VERSION "$Format:%h$"

NS_ :

BS_:

BU_: APB APP APS BCCEN BDY DAS DBG EAS EPAS EPAS2 EPAS3S EPB EPBM ESP GTW GTWU IBST IC MCU OCS PARK PARK3 RADAR RCM RT3000 SCCM SDM SEC TAS TAS2 TAS2DBG TOOL TPMS VCSEATD VCSEATP

BO_ 1009 RCM2_alertMatrix: 8 RCM
 SG_ RCM2_matrixIndex M : 0|4@1+ (1,0) [0|0] "" GTW
 SG_ RCM2_a567_seaTrkPosLeftConfig m5 : 42|1@1+ (1,0) [0|0] "" GTW
 SG_ RCM2_a568_occPROSSht2Gnd m5 : 43|1@1+ (1,0) [0|0] "" GTW
 SG_ RCM2_a569_occPROSSht2Bat m5 : 44|1@1+ (1,0) [0|0] "" GTW
 SG_ RCM2_a570_occPROSOpen m5 : 45|1@1+ (1,0) [0|0] "" GTW
 SG_ RCM2_a571_occPROSUndef m5 : 46|1@1+ (1,0) [0|0] "" GTW
 SG_ RCM2_a572_occPROSCrssCoup m5 : 47|1@1+ (1,0) [0|0] "" GTW
 SG_ RCM2_a573_occPROSConfig m5 : 48|1@1+ (1,0) [0|0] "" GTW
 SG_ RCM2_a587_sbrRearNetSht2Gnd m5 : 49|1@1+ (1,0) [0|0] "" GTW
 SG_ RCM2_a588_sbrRearNetSht2Bat m5 : 50|1@1+ (1,0) [0|0] "" GTW
 SG_ RCM2_a589_sbrRearNetOpen m5 : 51|1@1+ (1,0) [0|0] "" GTW
 SG_ RCM2_a590_sbrRearNetUndefined m5 : 52|1@1+ (1,0) [0|0] "" GTW
 SG_ RCM2_a591_sbrRearNetCrssCoup m5 : 53|1@1+ (1,0) [0|0] "" GTW
 SG_ RCM2_a592_sbrRearNetConfig m5 : 54|1@1+ (1,0) [0|0] "" GTW
 SG_ RCM2_a593_driveOrientaSht2Gnd m5 : 55|1@1+ (1,0) [0|0] "" GTW
 SG_ RCM2_a594_driveOrientaSht2Bat m5 : 56|1@1+ (1,0) [0|0] "" GTW
 SG_ RCM2_a595_driveOrientaOpen m5 : 57|1@1+ (1,0) [0|0] "" GTW
 SG_ RCM2_a596_driveOrientaUndefined m5 : 58|1@1+ (1,0) [0|0] "" GTW
 SG_ RCM2_a597_driveOrientaCrssCoup m5 : 59|1@1+ (1,0) [0|0] "" GTW
 SG_ RCM2_a598_driveOrientaConfig m5 : 60|1@1+ (1,0) [0|0] "" GTW
 SG_ RCM2_a600_comCANinternalTimeout m5 : 61|1@1+ (1,0) [0|0] "" GTW
 SG_ RCM2_a601_comChassisCANInit m5 : 62|1@1+ (1,0) [0|0] "" GTW
 SG_ RCM2_a602_comChassisCANBusOff m5 : 63|1@1+ (1,0) [0|0] "" GTW
 SG_ RCM2_a603_comPARTYCANInit m6 : 4|1@1+ (1,0) [0|0] "" GTW
 SG_ RCM2_a604_comPARTYCANBusOff m6 : 5|1@1+ (1,0) [0|0] "" GTW
 SG_ RCM2_a605_comStwAngStatMIA m6 : 6|1@1+ (1,0) [0|0] "" GTW
 SG_ RCM2_a606_comStwAngStatChkSm m6 : 7|1@1+ (1,0) [0|0] "" GTW
 SG_ RCM2_a607_comStwAngStatCntr m6 : 8|1@1+ (1,0) [0|0] "" GTW
 SG_ RCM2_a608_comDItorque1MIA m6 : 9|1@1+ (1,0) [0|0] "" GTW
 SG_ RCM2_a609_comDItorque1ChkSm m6 : 10|1@1+ (1,0) [0|0] "" GTW
 SG_ RCM2_a610_comDItorque1Cntr m6 : 11|1@1+ (1,0) [0|0] "" GTW
 SG_ RCM2_a611_comDItorque2MIA m6 : 12|1@1+ (1,0) [0|0] "" GTW
 SG_ RCM2_a612_comDItorque2ChkSm m6 : 13|1@1+ (1,0) [0|0] "" GTW
 SG_ RCM2_a613_comDItorque2Cntr m6 : 14|1@1+ (1,0) [0|0] "" GTW
 SG_ RCM2_a614_comESP135MIA m6 : 15|1@1+ (1,0) [0|0] "" GTW
 SG_ RCM2_a615_comESP135ChkSm m6 : 16|1@1+ (1,0) [0|0] "" GTW
 SG_ RCM2_a616_comESP135Cntr m6 : 17|1@1+ (1,0) [0|0] "" GTW
 SG_ RCM2_a617_comESP145MIA m6 : 18|1@1+ (1,0) [0|0] "" GTW
 SG_ RCM2_a618_comESP145ChkSm m6 : 19|1@1+ (1,0) [0|0] "" GTW
 SG_ RCM2_a619_comESP145Cntr m6 : 20|1@1+ (1,0) [0|0] "" GTW
 SG_ RCM2_a620_comInvalidVehicleSpeed m6 : 21|1@1+ (1,0) [0|0] "" GTW
 SG_ RCM2_a621_comESPBMIA m6 : 22|1@1+ (1,0) [0|0] "" GTW
 SG_ RCM2_a622_comESPBChkSm m6 : 23|1@1+ (1,0) [0|0] "" GTW
 SG_ RCM2_a623_comESPBCntr m6 : 24|1@1+ (1,0) [0|0] "" GTW
 SG_ RCM2_a624_comESPCMIA m6 : 25|1@1+ (1,0) [0|0] "" GTW
 SG_ RCM2_a625_comESPCChkSm m6 : 26|1@1+ (1,0) [0|0] "" GTW
 SG_ RCM2_a626_comESPCCntr m6 : 27|1@1+ (1,0) [0|0] "" GTW
 SG_ RCM2_a627_comEPBStatusMIA m6 : 28|1@1+ (1,0) [0|0] "" GTW
 SG_ RCM2_a628_comEPBStatusChkSm m6 : 29|1@1+ (1,0) [0|0] "" GTW
 SG_ RCM2_a629_comEPBStatusCntr m6 : 30|1@1+ (1,0) [0|0] "" GTW
 SG_ RCM2_a630_comGTWACSMIA m6 : 31|1@1+ (1,0) [0|0] "" GTW
 SG_ RCM2_a631_comGTWACSChkSm m6 : 32|1@1+ (1,0) [0|0] "" GTW
 SG_ RCM2_a632_comGTWACSCntr m6 : 33|1@1+ (1,0) [0|0] "" GTW
 SG_ RCM2_a633_comOCS1PMIA m6 : 34|1@1+ (1,0) [0|0] "" GTW
 SG_ RCM2_a634_comOCS1PChkSm m6 : 35|1@1+ (1,0) [0|0] "" GTW
 SG_ RCM2_a635_comOCS1PCntr m6 : 36|1@1+ (1,0) [0|0] "" GTW
 SG_ RCM2_a636_ocsFaulted m6 : 37|1@1+ (1,0) [0|0] "" GTW
 SG_ RCM2_a637_ocsUnknown m6 : 38|1@1+ (1,0) [0|0] "" GTW
 SG_ RCM2_a638_comGTWodoMIA m6 : 39|1@1+ (1,0) [0|0] "" GTW
 SG_ RCM2_a639_comGTWCarStateMIA m6 : 40|1@1+ (1,0) [0|0] "" GTW
 SG_ RCM2_a640_comTPMSStatusCMIA m6 : 41|1@1+ (1,0) [0|0] "" GTW
 SG_ RCM2_a641_comGTWCarConfigMIA m6 : 42|1@1+ (1,0) [0|0] "" GTW
 SG_ RCM2_a642_comVINmessageMIA m6 : 43|1@1+ (1,0) [0|0] "" GTW
 SG_ RCM2_a643_comDASSafetyFrntMIA m6 : 44|1@1+ (1,0) [0|0] "" GTW
 SG_ RCM2_a644_comDASSafetyFrntChkSm m6 : 45|1@1+ (1,0) [0|0] "" GTW
 SG_ RCM2_a645_comDASSafetyFrntCntr m6 : 46|1@1+ (1,0) [0|0] "" GTW
 SG_ RCM2_a646_comDIstateMIA m6 : 47|1@1+ (1,0) [0|0] "" GTW
 SG_ RCM2_a647_comDIstateChkSm m6 : 48|1@1+ (1,0) [0|0] "" GTW
 SG_ RCM2_a648_comDIstateCntr m6 : 49|1@1+ (1,0) [0|0] "" GTW
 SG_ RCM2_a649_comDIstate2MIA m6 : 50|1@1+ (1,0) [0|0] "" GTW
 SG_ RCM2_a650_comDIstate2ChkSm m6 : 51|1@1+ (1,0) [0|0] "" GTW
 SG_ RCM2_a651_comDIstate2Cntr m6 : 52|1@1+ (1,0) [0|0] "" GTW
 SG_ RCM2_a652_ambientTempFaulted m6 : 53|1@1+ (1,0) [0|0] "" GTW
 SG_ RCM2_a653_comGTWESP1MIA m6 : 54|1@1+ (1,0) [0|0] "" GTW
 SG_ RCM2_a654_comGTWESP1ChkSm m6 : 55|1@1+ (1,0) [0|0] "" GTW
 SG_ RCM2_a655_comGTWESP1Cntr m6 : 56|1@1+ (1,0) [0|0] "" GTW
 SG_ RCM2_a750_linInternalTimeout m6 : 57|1@1+ (1,0) [0|0] "" GTW
 SG_ RCM2_a800_cfgMissingCalibration m6 : 58|1@1+ (1,0) [0|0] "" GTW
 SG_ RCM2_a801_cfgImplausConfig m6 : 59|1@1+ (1,0) [0|0] "" GTW
 SG_ RCM2_a802_cfgInvalidConfig m6 : 60|1@1+ (1,0) [0|0] "" GTW
 SG_ RCM2_a803_cfgNotConfigured m6 : 61|1@1+ (1,0) [0|0] "" GTW
 SG_ RCM2_a804_cfgNotProgrammed m6 : 62|1@1+ (1,0) [0|0] "" GTW
 SG_ RCM2_a805_cfgPedProNotProgrammed m6 : 63|1@1+ (1,0) [0|0] "" GTW
 SG_ RCM2_a806_cfgCrashCalPNmissing m7 : 4|1@1+ (1,0) [0|0] "" GTW
 SG_ RCM2_a807_cfgExternalCRCError m7 : 5|1@1+ (1,0) [0|0] "" GTW
 SG_ RCM2_a808_cfgInvalParamLayoutID m7 : 6|1@1+ (1,0) [0|0] "" GTW
 SG_ RCM2_a809_cfgInvalParamTransID m7 : 7|1@1+ (1,0) [0|0] "" GTW
 SG_ RCM2_a810_cfgAlgoVerifySnsrID m7 : 8|1@1+ (1,0) [0|0] "" GTW
 SG_ RCM2_a811_cfgConfigDataInconsist m7 : 9|1@1+ (1,0) [0|0] "" GTW
 SG_ RCM2_a812_swVersionWrong m7 : 10|1@1+ (1,0) [0|0] "" GTW
 SG_ RCM2_a813_vinNotProgrammed m7 : 11|1@1+ (1,0) [0|0] "" GTW
 SG_ RCM2_a814_vinMismatch m7 : 12|1@1+ (1,0) [0|0] "" GTW
 SG_ RCM2_a815_driveLeaningNotDone m7 : 13|1@1+ (1,0) [0|0] "" GTW
 SG_ RCM2_a816_driveLeaningMismatch m7 : 14|1@1+ (1,0) [0|0] "" GTW
 SG_ RCM2_a817_bootActionsFailed m7 : 15|1@1+ (1,0) [0|0] "" GTW
 SG_ RCM2_a850_internalFault_001 m7 : 16|1@1+ (1,0) [0|0] "" GTW
 SG_ RCM2_a851_internalFault_002 m7 : 17|1@1+ (1,0) [0|0] "" GTW
 SG_ RCM2_a852_internalFault_003 m7 : 18|1@1+ (1,0) [0|0] "" GTW
 SG_ RCM2_a853_internalFault_004 m7 : 19|1@1+ (1,0) [0|0] "" GTW
 SG_ RCM2_a854_internalFault_005 m7 : 20|1@1+ (1,0) [0|0] "" GTW
 SG_ RCM2_a855_internalFault_006 m7 : 21|1@1+ (1,0) [0|0] "" GTW
 SG_ RCM2_a856_internalFault_007 m7 : 22|1@1+ (1,0) [0|0] "" GTW
 SG_ RCM2_a857_internalFault_008 m7 : 23|1@1+ (1,0) [0|0] "" GTW
 SG_ RCM2_a858_internalFault_009 m7 : 24|1@1+ (1,0) [0|0] "" GTW
 SG_ RCM2_a859_internalFault_010 m7 : 25|1@1+ (1,0) [0|0] "" GTW
 SG_ RCM2_a860_internalFault_011 m7 : 26|1@1+ (1,0) [0|0] "" GTW
 SG_ RCM2_a861_internalFault_012 m7 : 27|1@1+ (1,0) [0|0] "" GTW
 SG_ RCM2_a862_internalFault_013 m7 : 28|1@1+ (1,0) [0|0] "" GTW
 SG_ RCM2_a863_internalFault_014 m7 : 29|1@1+ (1,0) [0|0] "" GTW
 SG_ RCM2_a864_internalFault_015 m7 : 30|1@1+ (1,0) [0|0] "" GTW
 SG_ RCM2_a865_internalFault_016 m7 : 31|1@1+ (1,0) [0|0] "" GTW
 SG_ RCM2_a866_internalFault_017 m7 : 32|1@1+ (1,0) [0|0] "" GTW
 SG_ RCM2_a867_internalFault_018 m7 : 33|1@1+ (1,0) [0|0] "" GTW
 SG_ RCM2_a868_internalFault_019 m7 : 34|1@1+ (1,0) [0|0] "" GTW
 SG_ RCM2_a869_internalFault_020 m7 : 35|1@1+ (1,0) [0|0] "" GTW
 SG_ RCM2_a870_internalFault_021 m7 : 36|1@1+ (1,0) [0|0] "" GTW
 SG_ RCM2_a871_internalFault_022 m7 : 37|1@1+ (1,0) [0|0] "" GTW
 SG_ RCM2_a872_internalFault_023 m7 : 38|1@1+ (1,0) [0|0] "" GTW
 SG_ RCM2_a873_internalFault_024 m7 : 39|1@1+ (1,0) [0|0] "" GTW
 SG_ RCM2_a874_internalFault_025 m7 : 40|1@1+ (1,0) [0|0] "" GTW
 SG_ RCM2_a875_internalFault_026 m7 : 41|1@1+ (1,0) [0|0] "" GTW
 SG_ RCM2_a876_internalFault_027 m7 : 42|1@1+ (1,0) [0|0] "" GTW
 SG_ RCM2_a877_internalFault_028 m7 : 43|1@1+ (1,0) [0|0] "" GTW
 SG_ RCM2_a878_internalFault_029 m7 : 44|1@1+ (1,0) [0|0] "" GTW
 SG_ RCM2_a879_internalFault_030 m7 : 45|1@1+ (1,0) [0|0] "" GTW
 SG_ RCM2_a880_internalFault_031 m7 : 46|1@1+ (1,0) [0|0] "" GTW
 SG_ RCM2_a881_internalFault_032 m7 : 47|1@1+ (1,0) [0|0] "" GTW
 SG_ RCM2_a882_internalFault_033 m7 : 48|1@1+ (1,0) [0|0] "" GTW
 SG_ RCM2_a883_internalFault_034 m7 : 49|1@1+ (1,0) [0|0] "" GTW
 SG_ RCM2_a884_internalFault_035 m7 : 50|1@1+ (1,0) [0|0] "" GTW
 SG_ RCM2_a885_internalFault_036 m7 : 51|1@1+ (1,0) [0|0] "" GTW
 SG_ RCM2_a886_internalFault_037 m7 : 52|1@1+ (1,0) [0|0] "" GTW
 SG_ RCM2_a887_internalFault_038 m7 : 53|1@1+ (1,0) [0|0] "" GTW
 SG_ RCM2_a888_internalFault_039 m7 : 54|1@1+ (1,0) [0|0] "" GTW
 SG_ RCM2_a889_internalFault_040 m7 : 55|1@1+ (1,0) [0|0] "" GTW
 SG_ RCM2_a890_internalFault_041 m7 : 56|1@1+ (1,0) [0|0] "" GTW
 SG_ RCM2_a891_internalFault_042 m7 : 57|1@1+ (1,0) [0|0] "" GTW
 SG_ RCM2_a892_internalFault_043 m7 : 58|1@1+ (1,0) [0|0] "" GTW
 SG_ RCM2_a893_internalFault_044 m7 : 59|1@1+ (1,0) [0|0] "" GTW
 SG_ RCM2_a894_internalFault_045 m7 : 60|1@1+ (1,0) [0|0] "" GTW
 SG_ RCM2_a895_internalFault_046 m7 : 61|1@1+ (1,0) [0|0] "" GTW
 SG_ RCM2_a896_internalFault_047 m7 : 62|1@1+ (1,0) [0|0] "" GTW
 SG_ RCM2_a897_internalFault_048 m7 : 63|1@1+ (1,0) [0|0] "" GTW
 SG_ RCM2_a898_internalFault_049 m8 : 4|1@1+ (1,0) [0|0] "" GTW
 SG_ RCM2_a899_internalFault_050 m8 : 5|1@1+ (1,0) [0|0] "" GTW
 SG_ RCM2_a900_internalFault_051 m8 : 6|1@1+ (1,0) [0|0] "" GTW
 SG_ RCM2_a901_internalFault_052 m8 : 7|1@1+ (1,0) [0|0] "" GTW
 SG_ RCM2_a902_internalFault_053 m8 : 8|1@1+ (1,0) [0|0] "" GTW
 SG_ RCM2_a903_internalFault_054 m8 : 9|1@1+ (1,0) [0|0] "" GTW
 SG_ RCM2_a904_internalFault_055 m8 : 10|1@1+ (1,0) [0|0] "" GTW
 SG_ RCM2_a905_internalFault_056 m8 : 11|1@1+ (1,0) [0|0] "" GTW
 SG_ RCM2_a906_internalFault_057 m8 : 12|1@1+ (1,0) [0|0] "" GTW
 SG_ RCM2_a907_internalFault_058 m8 : 13|1@1+ (1,0) [0|0] "" GTW
 SG_ RCM2_a908_internalFault_059 m8 : 14|1@1+ (1,0) [0|0] "" GTW
 SG_ RCM2_a909_internalFault_060 m8 : 15|1@1+ (1,0) [0|0] "" GTW
 SG_ RCM2_a910_internalFault_061 m8 : 16|1@1+ (1,0) [0|0] "" GTW
 SG_ RCM2_a911_internalFault_062 m8 : 17|1@1+ (1,0) [0|0] "" GTW
 SG_ RCM2_a912_internalFault_063 m8 : 18|1@1+ (1,0) [0|0] "" GTW
 SG_ RCM2_a913_internalFault_064 m8 : 19|1@1+ (1,0) [0|0] "" GTW
 SG_ RCM2_a914_internalFault_065 m8 : 20|1@1+ (1,0) [0|0] "" GTW
 SG_ RCM2_a915_internalFault_066 m8 : 21|1@1+ (1,0) [0|0] "" GTW
 SG_ RCM2_a916_internalFault_067 m8 : 22|1@1+ (1,0) [0|0] "" GTW
 SG_ RCM2_a917_internalFault_068 m8 : 23|1@1+ (1,0) [0|0] "" GTW
 SG_ RCM2_a918_internalFault_069 m8 : 24|1@1+ (1,0) [0|0] "" GTW
 SG_ RCM2_a919_internalFault_070 m8 : 25|1@1+ (1,0) [0|0] "" GTW
 SG_ RCM2_a920_internalFault_071 m8 : 26|1@1+ (1,0) [0|0] "" GTW
 SG_ RCM2_a921_internalFault_072 m8 : 27|1@1+ (1,0) [0|0] "" GTW
 SG_ RCM2_a922_internalFault_073 m8 : 28|1@1+ (1,0) [0|0] "" GTW
 SG_ RCM2_a923_internalFault_074 m8 : 29|1@1+ (1,0) [0|0] "" GTW
 SG_ RCM2_a924_internalFault_075 m8 : 30|1@1+ (1,0) [0|0] "" GTW
 SG_ RCM2_a925_internalFault_076 m8 : 31|1@1+ (1,0) [0|0] "" GTW
 SG_ RCM2_a926_internalFault_077 m8 : 32|1@1+ (1,0) [0|0] "" GTW
 SG_ RCM2_a927_internalFault_078 m8 : 33|1@1+ (1,0) [0|0] "" GTW
 SG_ RCM2_a928_internalFault_079 m8 : 34|1@1+ (1,0) [0|0] "" GTW
 SG_ RCM2_a929_internalFault_080 m8 : 35|1@1+ (1,0) [0|0] "" GTW
 SG_ RCM2_a930_internalFault_081 m8 : 36|1@1+ (1,0) [0|0] "" GTW
 SG_ RCM2_a931_internalFault_082 m8 : 37|1@1+ (1,0) [0|0] "" GTW
 SG_ RCM2_a932_internalFault_083 m8 : 38|1@1+ (1,0) [0|0] "" GTW
 SG_ RCM2_a933_internalFault_084 m8 : 39|1@1+ (1,0) [0|0] "" GTW
 SG_ RCM2_a934_internalFault_085 m8 : 40|1@1+ (1,0) [0|0] "" GTW
 SG_ RCM2_a935_internalFault_086 m8 : 41|1@1+ (1,0) [0|0] "" GTW
 SG_ RCM2_a936_internalFault_087 m8 : 42|1@1+ (1,0) [0|0] "" GTW
 SG_ RCM2_a937_internalFault_088 m8 : 43|1@1+ (1,0) [0|0] "" GTW
 SG_ RCM2_a938_internalFault_089 m8 : 44|1@1+ (1,0) [0|0] "" GTW
 SG_ RCM2_a939_internalFault_090 m8 : 45|1@1+ (1,0) [0|0] "" GTW
 SG_ RCM2_a940_internalFault_091 m8 : 46|1@1+ (1,0) [0|0] "" GTW
 SG_ RCM2_a941_internalFault_092 m8 : 47|1@1+ (1,0) [0|0] "" GTW
 SG_ RCM2_a942_internalFault_093 m8 : 48|1@1+ (1,0) [0|0] "" GTW
 SG_ RCM2_a943_internalFault_094 m8 : 49|1@1+ (1,0) [0|0] "" GTW
 SG_ RCM2_a944_internalFault_095 m8 : 50|1@1+ (1,0) [0|0] "" GTW
 SG_ RCM2_a945_internalFault_096 m8 : 51|1@1+ (1,0) [0|0] "" GTW
 SG_ RCM2_a946_internalFault_097 m8 : 52|1@1+ (1,0) [0|0] "" GTW
 SG_ RCM2_a947_internalFault_098 m8 : 53|1@1+ (1,0) [0|0] "" GTW
 SG_ RCM2_a948_internalFault_099 m8 : 54|1@1+ (1,0) [0|0] "" GTW
 SG_ RCM2_a949_internalFault_100 m8 : 55|1@1+ (1,0) [0|0] "" GTW
 SG_ RCM2_a950_internalFault_101 m8 : 56|1@1+ (1,0) [0|0] "" GTW
 SG_ RCM2_a951_internalFault_102 m8 : 57|1@1+ (1,0) [0|0] "" GTW
 SG_ RCM2_a952_internalFault_103 m8 : 58|1@1+ (1,0) [0|0] "" GTW
 SG_ RCM2_a953_internalFault_104 m8 : 59|1@1+ (1,0) [0|0] "" GTW
 SG_ RCM2_a954_internalFault_105 m8 : 60|1@1+ (1,0) [0|0] "" GTW
 SG_ RCM2_a955_internalFault_106 m8 : 61|1@1+ (1,0) [0|0] "" GTW
 SG_ RCM2_a956_internalFault_107 m8 : 62|1@1+ (1,0) [0|0] "" GTW
 SG_ RCM2_a957_internalFault_108 m8 : 63|1@1+ (1,0) [0|0] "" GTW
 SG_ RCM2_a958_internalFault_109 m9 : 4|1@1+ (1,0) [0|0] "" GTW
 SG_ RCM2_a959_internalFault_110 m9 : 5|1@1+ (1,0) [0|0] "" GTW
 SG_ RCM2_a960_internalFault_111 m9 : 6|1@1+ (1,0) [0|0] "" GTW
 SG_ RCM2_a961_internalFault_112 m9 : 7|1@1+ (1,0) [0|0] "" GTW
 SG_ RCM2_a962_internalFault_113 m9 : 8|1@1+ (1,0) [0|0] "" GTW
 SG_ RCM2_a963_internalFault_114 m9 : 9|1@1+ (1,0) [0|0] "" GTW
 SG_ RCM2_a964_internalFault_115 m9 : 10|1@1+ (1,0) [0|0] "" GTW
 SG_ RCM2_a965_internalFault_116 m9 : 11|1@1+ (1,0) [0|0] "" GTW
 SG_ RCM2_a966_internalFault_117 m9 : 12|1@1+ (1,0) [0|0] "" GTW
 SG_ RCM2_a967_internalFault_118 m9 : 13|1@1+ (1,0) [0|0] "" GTW
 SG_ RCM2_a968_internalFault_119 m9 : 14|1@1+ (1,0) [0|0] "" GTW
 SG_ RCM2_a969_internalFault_120 m9 : 15|1@1+ (1,0) [0|0] "" GTW
 SG_ RCM2_a970_internalFault_121 m9 : 16|1@1+ (1,0) [0|0] "" GTW
 SG_ RCM2_a971_internalFault_122 m9 : 17|1@1+ (1,0) [0|0] "" GTW
 SG_ RCM2_a972_internalFault_123 m9 : 18|1@1+ (1,0) [0|0] "" GTW
 SG_ RCM2_a973_internalFault_124 m9 : 19|1@1+ (1,0) [0|0] "" GTW
 SG_ RCM2_a974_internalFault_125 m9 : 20|1@1+ (1,0) [0|0] "" GTW
 SG_ RCM2_a975_internalFault_126 m9 : 21|1@1+ (1,0) [0|0] "" GTW
 SG_ RCM2_a976_internalFault_127 m9 : 22|1@1+ (1,0) [0|0] "" GTW
 SG_ RCM2_a977_internalFault_128 m9 : 23|1@1+ (1,0) [0|0] "" GTW
 SG_ RCM2_a978_internalFault_129 m9 : 24|1@1+ (1,0) [0|0] "" GTW
 SG_ RCM2_a979_internalFault_130 m9 : 25|1@1+ (1,0) [0|0] "" GTW
 SG_ RCM2_a980_internalFault_131 m9 : 26|1@1+ (1,0) [0|0] "" GTW
 SG_ RCM2_a981_internalFault_132 m9 : 27|1@1+ (1,0) [0|0] "" GTW
 SG_ RCM2_a982_internalFault_133 m9 : 28|1@1+ (1,0) [0|0] "" GTW
 SG_ RCM2_a983_internalFault_134 m9 : 29|1@1+ (1,0) [0|0] "" GTW
 SG_ RCM2_a984_internalFault_135 m9 : 30|1@1+ (1,0) [0|0] "" GTW
 SG_ RCM2_a985_internalFault_136 m9 : 31|1@1+ (1,0) [0|0] "" GTW
 SG_ RCM2_a986_internalFault_137 m9 : 32|1@1+ (1,0) [0|0] "" GTW
 SG_ RCM2_a987_internalFault_138 m9 : 33|1@1+ (1,0) [0|0] "" GTW
 SG_ RCM2_a988_internalFault_139 m9 : 34|1@1+ (1,0) [0|0] "" GTW
 SG_ RCM2_a989_internalFault_140 m9 : 35|1@1+ (1,0) [0|0] "" GTW
 SG_ RCM2_a990_internalFault_141 m9 : 36|1@1+ (1,0) [0|0] "" GTW
 SG_ RCM2_a991_internalFault_142 m9 : 37|1@1+ (1,0) [0|0] "" GTW
 SG_ RCM2_a992_internalFault_143 m9 : 38|1@1+ (1,0) [0|0] "" GTW
 SG_ RCM2_a993_internalFault_144 m9 : 39|1@1+ (1,0) [0|0] "" GTW
 SG_ RCM2_a994_internalFault_145 m9 : 40|1@1+ (1,0) [0|0] "" GTW

BO_ 1297 RCM_alertLog: 8 RCM
 SG_ RCM_alertID M : 0|15@1+ (1,0) [0|0] "" GTW
 SG_ RCM_alertType : 15|1@1+ (1,0) [0|0] "" GTW
 SG_ RCM_canTimeout m16384 : 16|1@1+ (1,0) [0|0] "" GTW
 SG_ RCM_comMLCHMainFunc m16384 : 17|1@1+ (1,0) [0|0] "" GTW
 SG_ RCM_vBatHigh m16385 : 16|1@1+ (1,0) [0|0] "" GTW
 SG_ RCM_vBatLow m16385 : 17|1@1+ (1,0) [0|0] "" GTW
 SG_ RCM_vinMismatch m16386 : 16|1@1+ (1,0) [0|0] "" GTW
 SG_ RCM_vinNotProgrammed m16386 : 17|1@1+ (1,0) [0|0] "" GTW
 SG_ RCM_algoPASIDMismatch m16387 : 16|1@1+ (1,0) [0|0] "" GTW
 SG_ RCM_swVersion m16387 : 17|1@1+ (1,0) [0|0] "" GTW
 SG_ RCM_paramLayoutIDInv m16387 : 18|1@1+ (1,0) [0|0] "" GTW
 SG_ RCM_idleMode m16388 : 16|1@1+ (1,0) [0|0] "" GTW
 SG_ RCM_internalHard m16389 : 16|1@1+ (1,0) [0|0] "" GTW
 SG_ RCM_frontAlgoDisabled m16390 : 16|1@1+ (1,0) [0|0] "" GTW
 SG_ RCM_sideAlgoDisabled m16390 : 17|1@1+ (1,0) [0|0] "" GTW
 SG_ RCM_rollAlgoDisabled m16390 : 18|1@1+ (1,0) [0|0] "" GTW
 SG_ RCM_eolProgMismatch m16391 : 16|1@1+ (1,0) [0|0] "" GTW
 SG_ RCM_ccVDSImplausibleCfg m16391 : 17|1@1+ (1,0) [0|0] "" GTW
 SG_ RCM_invalidMDFval m16391 : 18|1@1+ (1,0) [0|0] "" GTW
 SG_ RCM_ccVDSNotConfigured m16391 : 19|1@1+ (1,0) [0|0] "" GTW
 SG_ RCM_missingCCVDScfgBlk m16391 : 20|1@1+ (1,0) [0|0] "" GTW
 SG_ RCM_ccVDSNotProgrammed m16391 : 21|1@1+ (1,0) [0|0] "" GTW
 SG_ RCM_eppDevNotProgrammed m16391 : 22|1@1+ (1,0) [0|0] "" GTW
 SG_ RCM_crcErrorExternal m16392 : 16|1@1+ (1,0) [0|0] "" GTW
 SG_ RCM_cfgFault m16393 : 16|1@1+ (1,0) [0|0] "" GTW
 SG_ RCM_ecuIsInPlantMode m16393 : 17|1@1+ (1,0) [0|0] "" GTW
 SG_ RCM_crashCalPNMissing m16394 : 16|1@1+ (1,0) [0|0] "" GTW
 SG_ RCM_vdsFieldCalibFailed m16395 : 16|1@1+ (1,0) [0|0] "" GTW
 SG_ RCM_vdsAxChSigMonTmp m16396 : 16|1@1+ (1,0) [0|0] "" GTW
 SG_ RCM_vdsAyChSigMonTmp m16396 : 17|1@1+ (1,0) [0|0] "" GTW
 SG_ RCM_vdsYawChSigMonTmp m16396 : 18|1@1+ (1,0) [0|0] "" GTW
 SG_ RCM_vdsRollChSigMonTmp m16396 : 19|1@1+ (1,0) [0|0] "" GTW
 SG_ RCM_vdsPitchChSigMonTmp m16396 : 20|1@1+ (1,0) [0|0] "" GTW
 SG_ RCM_vdsSMB200ChSigMonTmp m16396 : 21|1@1+ (1,0) [0|0] "" GTW
 SG_ RCM_vdsFieldCalibNotDone m16397 : 16|1@1+ (1,0) [0|0] "" GTW
 SG_ RCM_vdsAxChSigMonPerm m16398 : 16|1@1+ (1,0) [0|0] "" GTW
 SG_ RCM_vdsAyChSigMonPerm m16398 : 17|1@1+ (1,0) [0|0] "" GTW
 SG_ RCM_vdsInPlnChSigMonPerm m16398 : 18|1@1+ (1,0) [0|0] "" GTW
 SG_ RCM_vdsYawChSigMonPerm m16398 : 19|1@1+ (1,0) [0|0] "" GTW
 SG_ RCM_vdsYawSnsrMonPerm m16398 : 20|1@1+ (1,0) [0|0] "" GTW
 SG_ RCM_vdsRollChSigMonPerm m16398 : 21|1@1+ (1,0) [0|0] "" GTW
 SG_ RCM_vdsRollSnsrMonPerm m16398 : 22|1@1+ (1,0) [0|0] "" GTW
 SG_ RCM_vdsPitchChSigMonPerm m16398 : 23|1@1+ (1,0) [0|0] "" GTW
 SG_ RCM_vdsPitchSnsrMonPerm m16398 : 24|1@1+ (1,0) [0|0] "" GTW
 SG_ RCM_vdsSMB200ChSigMonPer m16398 : 25|1@1+ (1,0) [0|0] "" GTW
 SG_ RCM_vdsInPlnSnsrMonTmp m16399 : 16|1@1+ (1,0) [0|0] "" GTW
 SG_ RCM_vdsYawSnsrMonTmp m16399 : 17|1@1+ (1,0) [0|0] "" GTW
 SG_ RCM_vdsRollSnsrMonTmp m16399 : 18|1@1+ (1,0) [0|0] "" GTW
 SG_ RCM_vdsPitchSnsrMonTmp m16399 : 19|1@1+ (1,0) [0|0] "" GTW
 SG_ RCM_comCANInitFailre m16400 : 16|1@1+ (1,0) [0|0] "" GTW
 SG_ RCM_comGTWCarConfigTO m16401 : 16|1@1+ (1,0) [0|0] "" GTW
 SG_ RCM_vinEmptyError m16402 : 16|1@1+ (1,0) [0|0] "" GTW
 SG_ RCM_comESPCTO m16403 : 16|1@1+ (1,0) [0|0] "" GTW
 SG_ RCM_comESPCCRC m16403 : 17|1@1+ (1,0) [0|0] "" GTW
 SG_ RCM_comESPCCntr m16403 : 18|1@1+ (1,0) [0|0] "" GTW
 SG_ RCM_comESP135TO m16404 : 16|1@1+ (1,0) [0|0] "" GTW
 SG_ RCM_comESP135CRC m16404 : 17|1@1+ (1,0) [0|0] "" GTW
 SG_ RCM_comESP135Cntr m16404 : 18|1@1+ (1,0) [0|0] "" GTW
 SG_ RCM_comEPBStatusTO m16405 : 16|1@1+ (1,0) [0|0] "" GTW
 SG_ RCM_comEPBStatusCRC m16405 : 17|1@1+ (1,0) [0|0] "" GTW
 SG_ RCM_comEPBStatusCntr m16405 : 18|1@1+ (1,0) [0|0] "" GTW
 SG_ RCM_comBCS2RStatusTO m16406 : 16|1@1+ (1,0) [0|0] "" GTW
 SG_ RCM_comBCS2RStatusCRC m16406 : 17|1@1+ (1,0) [0|0] "" GTW
 SG_ RCM_comBCS2RStatusCntr m16406 : 18|1@1+ (1,0) [0|0] "" GTW
 SG_ RCM_comBCS2LStatusTO m16407 : 16|1@1+ (1,0) [0|0] "" GTW
 SG_ RCM_comBCS2LStatusCRC m16407 : 17|1@1+ (1,0) [0|0] "" GTW
 SG_ RCM_comBCS2LStatusCntr m16407 : 18|1@1+ (1,0) [0|0] "" GTW
 SG_ RCM_comBCS2CStatusTO m16408 : 16|1@1+ (1,0) [0|0] "" GTW
 SG_ RCM_comBCS2CStatusCRC m16408 : 17|1@1+ (1,0) [0|0] "" GTW
 SG_ RCM_comBCS2CStatusCntr m16408 : 18|1@1+ (1,0) [0|0] "" GTW
 SG_ RCM_comTPMSStatusTO m16409 : 16|1@1+ (1,0) [0|0] "" GTW
 SG_ RCM_airbagWarningMismatch m16410 : 16|1@1+ (1,0) [0|0] "" GTW
 SG_ RCM_ocsLevel1Error m16411 : 16|1@1+ (1,0) [0|0] "" GTW
 SG_ RCM_comOCSStatusTO m16411 : 17|1@1+ (1,0) [0|0] "" GTW
 SG_ RCM_comOCSStatusCRC m16411 : 18|1@1+ (1,0) [0|0] "" GTW
 SG_ RCM_comOCSStatusCntr m16411 : 19|1@1+ (1,0) [0|0] "" GTW
 SG_ RCM_comOCSIncorrect m16411 : 20|1@1+ (1,0) [0|0] "" GTW
 SG_ RCM_ocsInvalidCalibID m16411 : 21|1@1+ (1,0) [0|0] "" GTW
 SG_ RCM_comGTWACSCntr m16412 : 16|1@1+ (1,0) [0|0] "" GTW
 SG_ RCM_comGTWACSCRC m16412 : 17|1@1+ (1,0) [0|0] "" GTW
 SG_ RCM_comGTWACSTO m16412 : 18|1@1+ (1,0) [0|0] "" GTW
 SG_ RCM_comChassisBusOff m16413 : 16|1@1+ (1,0) [0|0] "" GTW
 SG_ RCM_comStwAngleTO m16414 : 16|1@1+ (1,0) [0|0] "" GTW
 SG_ RCM_comStwAngleCRC m16414 : 17|1@1+ (1,0) [0|0] "" GTW
 SG_ RCM_comStwAngleCntr m16414 : 18|1@1+ (1,0) [0|0] "" GTW
 SG_ RCM_comESP145TO m16415 : 16|1@1+ (1,0) [0|0] "" GTW
 SG_ RCM_comESP145CRC m16415 : 17|1@1+ (1,0) [0|0] "" GTW
 SG_ RCM_comESP145Cntr m16415 : 18|1@1+ (1,0) [0|0] "" GTW
 SG_ RCM_comDITorque2TO m16416 : 16|1@1+ (1,0) [0|0] "" GTW
 SG_ RCM_comDITorque2CRC m16416 : 17|1@1+ (1,0) [0|0] "" GTW
 SG_ RCM_comDITorque2Cntr m16416 : 18|1@1+ (1,0) [0|0] "" GTW
 SG_ RCM_comDITorque1TO m16417 : 16|1@1+ (1,0) [0|0] "" GTW
 SG_ RCM_comDITorque1CRC m16417 : 17|1@1+ (1,0) [0|0] "" GTW
 SG_ RCM_comDITorque1Cntr m16417 : 18|1@1+ (1,0) [0|0] "" GTW
 SG_ RCM_comESPBTO m16418 : 16|1@1+ (1,0) [0|0] "" GTW
 SG_ RCM_invalidVehSpeedQfRxd m16418 : 17|1@1+ (1,0) [0|0] "" GTW
 SG_ RCM_invalidAmbTempQfRxd m16418 : 18|1@1+ (1,0) [0|0] "" GTW
 SG_ RCM_comESPBCRC m16418 : 19|1@1+ (1,0) [0|0] "" GTW
 SG_ RCM_comESPBCntr m16418 : 20|1@1+ (1,0) [0|0] "" GTW
 SG_ RCM_comGTWOdoTO m16419 : 16|1@1+ (1,0) [0|0] "" GTW
 SG_ RCM_comPrivateBusOff m16420 : 16|1@1+ (1,0) [0|0] "" GTW
 SG_ RCM_comPublicBusOff m16420 : 17|1@1+ (1,0) [0|0] "" GTW
 SG_ RCM_comMissingACSSwSts m16421 : 16|1@1+ (1,0) [0|0] "" GTW
 SG_ RCM_comMissingVehConfPar m16421 : 17|1@1+ (1,0) [0|0] "" GTW
 SG_ RCM_sbsw2ndRowLConfig m16422 : 16|1@1+ (1,0) [0|0] "" GTW
 SG_ RCM_sbsw2ndRowLCrossCoup m16422 : 17|1@1+ (1,0) [0|0] "" GTW
 SG_ RCM_sbsw2ndRowLUndefined m16422 : 18|1@1+ (1,0) [0|0] "" GTW
 SG_ RCM_sbsw2ndRowLOpen m16422 : 19|1@1+ (1,0) [0|0] "" GTW
 SG_ RCM_sbsw2ndRowLSht2bat m16422 : 20|1@1+ (1,0) [0|0] "" GTW
 SG_ RCM_sbsw2ndRowLSht2gnd m16422 : 21|1@1+ (1,0) [0|0] "" GTW
 SG_ RCM_pretenLapRightCfg m16423 : 16|1@1+ (1,0) [0|0] "" GTW
 SG_ RCM_pretenLapRightCrosCou m16423 : 17|1@1+ (1,0) [0|0] "" GTW
 SG_ RCM_pretenLapRightShort m16423 : 18|1@1+ (1,0) [0|0] "" GTW
 SG_ RCM_pretenLapRightOpen m16423 : 19|1@1+ (1,0) [0|0] "" GTW
 SG_ RCM_pretenLapRightSht2Bat m16423 : 20|1@1+ (1,0) [0|0] "" GTW
 SG_ RCM_pretenLapRightSht2Gnd m16423 : 21|1@1+ (1,0) [0|0] "" GTW
 SG_ RCM_pretenLapLeftCfg m16424 : 16|1@1+ (1,0) [0|0] "" GTW
 SG_ RCM_pretenLapLeftCrossCo m16424 : 17|1@1+ (1,0) [0|0] "" GTW
 SG_ RCM_pretenLapLeftShort m16424 : 18|1@1+ (1,0) [0|0] "" GTW
 SG_ RCM_pretenLapLeftOpen m16424 : 19|1@1+ (1,0) [0|0] "" GTW
 SG_ RCM_pretenLapLeftSht2Bat m16424 : 20|1@1+ (1,0) [0|0] "" GTW
 SG_ RCM_pretenLapLeftSht2Gnd m16424 : 21|1@1+ (1,0) [0|0] "" GTW
 SG_ RCM_pretenShldRightCfg m16425 : 16|1@1+ (1,0) [0|0] "" GTW
 SG_ RCM_pretenShldRightCrossC m16425 : 17|1@1+ (1,0) [0|0] "" GTW
 SG_ RCM_pretenShldRightShort m16425 : 18|1@1+ (1,0) [0|0] "" GTW
 SG_ RCM_pretenShldRightOpen m16425 : 19|1@1+ (1,0) [0|0] "" GTW
 SG_ RCM_pretenShldRightSht2Ba m16425 : 20|1@1+ (1,0) [0|0] "" GTW
 SG_ RCM_pretenShldRightSht2Gn m16425 : 21|1@1+ (1,0) [0|0] "" GTW
 SG_ RCM_pretenShldLeftCfg m16426 : 16|1@1+ (1,0) [0|0] "" GTW
 SG_ RCM_pretenShldLeftCrossC m16426 : 17|1@1+ (1,0) [0|0] "" GTW
 SG_ RCM_pretenShldLeftShort m16426 : 18|1@1+ (1,0) [0|0] "" GTW
 SG_ RCM_pretenShldLeftOpen m16426 : 19|1@1+ (1,0) [0|0] "" GTW
 SG_ RCM_pretenShldLeftSht2Ba m16426 : 20|1@1+ (1,0) [0|0] "" GTW
 SG_ RCM_pretenShldLeftSht2Gn m16426 : 21|1@1+ (1,0) [0|0] "" GTW
 SG_ RCM_passABLampOnCfg m16427 : 16|1@1+ (1,0) [0|0] "" GTW
 SG_ RCM_passABLampOnGndorOpn m16427 : 17|1@1+ (1,0) [0|0] "" GTW
 SG_ RCM_passABLampSht2Bat m16427 : 18|1@1+ (1,0) [0|0] "" GTW
 SG_ RCM_passABLampOnBatorOpn m16427 : 19|1@1+ (1,0) [0|0] "" GTW
 SG_ RCM_pedProCrashDetected m16428 : 16|1@1+ (1,0) [0|0] "" GTW
 SG_ RCM_crashOutSigSht2Gnd m16429 : 16|1@1+ (1,0) [0|0] "" GTW
 SG_ RCM_crashOutSigSht2Bat m16429 : 17|1@1+ (1,0) [0|0] "" GTW
 SG_ RCM_passActiveVentCfg m16430 : 16|1@1+ (1,0) [0|0] "" GTW
 SG_ RCM_passActiveVentCrosCo m16430 : 17|1@1+ (1,0) [0|0] "" GTW
 SG_ RCM_passActiveVentShort m16430 : 18|1@1+ (1,0) [0|0] "" GTW
 SG_ RCM_passActiveVentOpen m16430 : 19|1@1+ (1,0) [0|0] "" GTW
 SG_ RCM_passActiveVentSht2Ba m16430 : 20|1@1+ (1,0) [0|0] "" GTW
 SG_ RCM_passActiveVentSht2Gn m16430 : 21|1@1+ (1,0) [0|0] "" GTW
 SG_ RCM_kneeABPassCfg m16431 : 16|1@1+ (1,0) [0|0] "" GTW
 SG_ RCM_kneeABPassCrosCoup m16431 : 17|1@1+ (1,0) [0|0] "" GTW
 SG_ RCM_kneeABPassShort m16431 : 18|1@1+ (1,0) [0|0] "" GTW
 SG_ RCM_kneeABPassOpen m16431 : 19|1@1+ (1,0) [0|0] "" GTW
 SG_ RCM_kneeABPassSht2Bat m16431 : 20|1@1+ (1,0) [0|0] "" GTW
 SG_ RCM_kneeABPassSht2Gnd m16431 : 21|1@1+ (1,0) [0|0] "" GTW
 SG_ RCM_presFrntRDoorDefect m16432 : 16|1@1+ (1,0) [0|0] "" GTW
 SG_ RCM_presFrntRDoorPlaus m16432 : 17|1@1+ (1,0) [0|0] "" GTW
 SG_ RCM_presFrntRDoorAbsPre m16432 : 18|1@1+ (1,0) [0|0] "" GTW
 SG_ RCM_presFrntRDoorOption m16432 : 19|1@1+ (1,0) [0|0] "" GTW
 SG_ RCM_presFrntRDoorInitTyp m16432 : 20|1@1+ (1,0) [0|0] "" GTW
 SG_ RCM_presFrntRDoorExComm m16432 : 21|1@1+ (1,0) [0|0] "" GTW
 SG_ RCM_presFrntRDoorCrosCo m16432 : 22|1@1+ (1,0) [0|0] "" GTW
 SG_ RCM_presFrntRDoorSht2Ba m16432 : 23|1@1+ (1,0) [0|0] "" GTW
 SG_ RCM_presFrntRDoorSht2Gn m16432 : 24|1@1+ (1,0) [0|0] "" GTW
 SG_ RCM_presFrntLDoorDefect m16433 : 16|1@1+ (1,0) [0|0] "" GTW
 SG_ RCM_presFrntLDoorPlaus m16433 : 17|1@1+ (1,0) [0|0] "" GTW
 SG_ RCM_presFrntLDoorAbsPre m16433 : 18|1@1+ (1,0) [0|0] "" GTW
 SG_ RCM_presFrntLDoorOption m16433 : 19|1@1+ (1,0) [0|0] "" GTW
 SG_ RCM_presFrntLDoorInitTyp m16433 : 20|1@1+ (1,0) [0|0] "" GTW
 SG_ RCM_presFrntLDoorExComm m16433 : 21|1@1+ (1,0) [0|0] "" GTW
 SG_ RCM_presFrntLDoorCrosCo m16433 : 22|1@1+ (1,0) [0|0] "" GTW
 SG_ RCM_presFrntLDoorSht2Ba m16433 : 23|1@1+ (1,0) [0|0] "" GTW
 SG_ RCM_presFrntLDoorSht2Gn m16433 : 24|1@1+ (1,0) [0|0] "" GTW
 SG_ RCM_edrDataAreaLocked m16434 : 16|1@1+ (1,0) [0|0] "" GTW
 SG_ RCM_eepromLocked m16434 : 17|1@1+ (1,0) [0|0] "" GTW
 SG_ RCM_hoodActuatorLCfg m16435 : 16|1@1+ (1,0) [0|0] "" GTW
 SG_ RCM_hoodActuatorLCrosCou m16435 : 17|1@1+ (1,0) [0|0] "" GTW
 SG_ RCM_hoodActuatorLShort m16435 : 18|1@1+ (1,0) [0|0] "" GTW
 SG_ RCM_hoodActuatorLOpen m16435 : 19|1@1+ (1,0) [0|0] "" GTW
 SG_ RCM_hoodActuatorLSht2Bat m16435 : 20|1@1+ (1,0) [0|0] "" GTW
 SG_ RCM_hoodActuatorLSht2Gnd m16435 : 21|1@1+ (1,0) [0|0] "" GTW
 SG_ RCM_hoodActuatorRCfg m16436 : 16|1@1+ (1,0) [0|0] "" GTW
 SG_ RCM_hoodActuatorRCrosCou m16436 : 17|1@1+ (1,0) [0|0] "" GTW
 SG_ RCM_hoodActuatorRShort m16436 : 18|1@1+ (1,0) [0|0] "" GTW
 SG_ RCM_hoodActuatorROpen m16436 : 19|1@1+ (1,0) [0|0] "" GTW
 SG_ RCM_hoodActuatorRSht2Bat m16436 : 20|1@1+ (1,0) [0|0] "" GTW
 SG_ RCM_hoodActuatorRSht2Gnd m16436 : 21|1@1+ (1,0) [0|0] "" GTW
 SG_ RCM_sbsw2ndRowRConfig m16437 : 16|1@1+ (1,0) [0|0] "" GTW
 SG_ RCM_sbsw2ndRowRCrossCoup m16437 : 17|1@1+ (1,0) [0|0] "" GTW
 SG_ RCM_sbsw2ndRowRUndefined m16437 : 18|1@1+ (1,0) [0|0] "" GTW
 SG_ RCM_sbsw2ndRowROpen m16437 : 19|1@1+ (1,0) [0|0] "" GTW
 SG_ RCM_sbsw2ndRowRshrt2bat m16437 : 20|1@1+ (1,0) [0|0] "" GTW
 SG_ RCM_sbsw2ndRowRshrt2gnd m16437 : 21|1@1+ (1,0) [0|0] "" GTW
 SG_ RCM_padLampCfg m16438 : 16|1@1+ (1,0) [0|0] "" GTW
 SG_ RCM_padLampGndorOpen m16438 : 17|1@1+ (1,0) [0|0] "" GTW
 SG_ RCM_padLampSht2Bat m16438 : 18|1@1+ (1,0) [0|0] "" GTW
 SG_ RCM_padLampBatorOpen m16438 : 19|1@1+ (1,0) [0|0] "" GTW
 SG_ RCM_passResOccSwCfg m16439 : 16|1@1+ (1,0) [0|0] "" GTW
 SG_ RCM_passResOccSwCrosCoup m16439 : 17|1@1+ (1,0) [0|0] "" GTW
 SG_ RCM_passResOccSwUndef m16439 : 18|1@1+ (1,0) [0|0] "" GTW
 SG_ RCM_passResOccSwOpen m16439 : 19|1@1+ (1,0) [0|0] "" GTW
 SG_ RCM_passResOccSwSht2Bat m16439 : 20|1@1+ (1,0) [0|0] "" GTW
 SG_ RCM_passResOccSwShort m16439 : 21|1@1+ (1,0) [0|0] "" GTW
 SG_ RCM_stpsDrvrCfg m16440 : 16|1@1+ (1,0) [0|0] "" GTW
 SG_ RCM_stpsDrvrCrosCoup m16440 : 17|1@1+ (1,0) [0|0] "" GTW
 SG_ RCM_stpsDrvrUndefined m16440 : 18|1@1+ (1,0) [0|0] "" GTW
 SG_ RCM_stpsDrvrOpen m16440 : 19|1@1+ (1,0) [0|0] "" GTW
 SG_ RCM_stpsDrvrSht2Bat m16440 : 20|1@1+ (1,0) [0|0] "" GTW
 SG_ RCM_stpsDrvrShort m16440 : 21|1@1+ (1,0) [0|0] "" GTW
 SG_ RCM_pasDLyDefect m16441 : 16|1@1+ (1,0) [0|0] "" GTW
 SG_ RCM_pasDLyplaus m16441 : 17|1@1+ (1,0) [0|0] "" GTW
 SG_ RCM_pasDLyOption m16441 : 18|1@1+ (1,0) [0|0] "" GTW
 SG_ RCM_pasDLyInitTyp m16441 : 19|1@1+ (1,0) [0|0] "" GTW
 SG_ RCM_pasDLyExComm m16441 : 20|1@1+ (1,0) [0|0] "" GTW
 SG_ RCM_pasDLyCrosCoup m16441 : 21|1@1+ (1,0) [0|0] "" GTW
 SG_ RCM_pasDLySht2Bat m16441 : 22|1@1+ (1,0) [0|0] "" GTW
 SG_ RCM_pasDLySht2Gnd m16441 : 23|1@1+ (1,0) [0|0] "" GTW
 SG_ RCM_pasDLxDefect m16442 : 16|1@1+ (1,0) [0|0] "" GTW
 SG_ RCM_pasDLxplaus m16442 : 17|1@1+ (1,0) [0|0] "" GTW
 SG_ RCM_pasDLxOption m16442 : 18|1@1+ (1,0) [0|0] "" GTW
 SG_ RCM_pasDLxInitTyp m16442 : 19|1@1+ (1,0) [0|0] "" GTW
 SG_ RCM_pasDLxExComm m16442 : 20|1@1+ (1,0) [0|0] "" GTW
 SG_ RCM_pasDLxCrosCoup m16442 : 21|1@1+ (1,0) [0|0] "" GTW
 SG_ RCM_pasDLxSht2Bat m16442 : 22|1@1+ (1,0) [0|0] "" GTW
 SG_ RCM_pasDLxSht2Gnd m16442 : 23|1@1+ (1,0) [0|0] "" GTW
 SG_ RCM_pasDRDefect m16443 : 16|1@1+ (1,0) [0|0] "" GTW
 SG_ RCM_pasDRplaus m16443 : 17|1@1+ (1,0) [0|0] "" GTW
 SG_ RCM_pasDROption m16443 : 18|1@1+ (1,0) [0|0] "" GTW
 SG_ RCM_pasDRInitTyp m16443 : 19|1@1+ (1,0) [0|0] "" GTW
 SG_ RCM_pasDRExComm m16443 : 20|1@1+ (1,0) [0|0] "" GTW
 SG_ RCM_pasDRCrosCoup m16443 : 21|1@1+ (1,0) [0|0] "" GTW
 SG_ RCM_pasDRSht2Bat m16443 : 22|1@1+ (1,0) [0|0] "" GTW
 SG_ RCM_pasDRSht2Gnd m16443 : 23|1@1+ (1,0) [0|0] "" GTW
 SG_ RCM_pasCRDefect m16444 : 16|1@1+ (1,0) [0|0] "" GTW
 SG_ RCM_pasCRplaus m16444 : 17|1@1+ (1,0) [0|0] "" GTW
 SG_ RCM_pasCROption m16444 : 18|1@1+ (1,0) [0|0] "" GTW
 SG_ RCM_pasCRInitTyp m16444 : 19|1@1+ (1,0) [0|0] "" GTW
 SG_ RCM_pasCRExComm m16444 : 20|1@1+ (1,0) [0|0] "" GTW
 SG_ RCM_pasCRCrosCoup m16444 : 21|1@1+ (1,0) [0|0] "" GTW
 SG_ RCM_pasCRSht2Bat m16444 : 22|1@1+ (1,0) [0|0] "" GTW
 SG_ RCM_pasCRSht2Gnd m16444 : 23|1@1+ (1,0) [0|0] "" GTW
 SG_ RCM_pasBRDefect m16445 : 16|1@1+ (1,0) [0|0] "" GTW
 SG_ RCM_pasBRplaus m16445 : 17|1@1+ (1,0) [0|0] "" GTW
 SG_ RCM_pasBROption m16445 : 18|1@1+ (1,0) [0|0] "" GTW
 SG_ RCM_pasBRInitTyp m16445 : 19|1@1+ (1,0) [0|0] "" GTW
 SG_ RCM_pasBRExComm m16445 : 20|1@1+ (1,0) [0|0] "" GTW
 SG_ RCM_pasBRCrosCoup m16445 : 21|1@1+ (1,0) [0|0] "" GTW
 SG_ RCM_pasBRSht2Bat m16445 : 22|1@1+ (1,0) [0|0] "" GTW
 SG_ RCM_pasBRSht2Gnd m16445 : 23|1@1+ (1,0) [0|0] "" GTW
 SG_ RCM_ufsRDefect m16446 : 16|1@1+ (1,0) [0|0] "" GTW
 SG_ RCM_ufsRplaus m16446 : 17|1@1+ (1,0) [0|0] "" GTW
 SG_ RCM_ufsROption m16446 : 18|1@1+ (1,0) [0|0] "" GTW
 SG_ RCM_ufsRInitTyp m16446 : 19|1@1+ (1,0) [0|0] "" GTW
 SG_ RCM_ufsRExComm m16446 : 20|1@1+ (1,0) [0|0] "" GTW
 SG_ RCM_ufsRCrosCoup m16446 : 21|1@1+ (1,0) [0|0] "" GTW
 SG_ RCM_ufsRSht2Bat m16446 : 22|1@1+ (1,0) [0|0] "" GTW
 SG_ RCM_ufsRSht2Gnd m16446 : 23|1@1+ (1,0) [0|0] "" GTW
 SG_ RCM_pasCLDefect m16447 : 16|1@1+ (1,0) [0|0] "" GTW
 SG_ RCM_pasCLplaus m16447 : 17|1@1+ (1,0) [0|0] "" GTW
 SG_ RCM_pasCLOption m16447 : 18|1@1+ (1,0) [0|0] "" GTW
 SG_ RCM_pasCLInitTyp m16447 : 19|1@1+ (1,0) [0|0] "" GTW
 SG_ RCM_pasCLExComm m16447 : 20|1@1+ (1,0) [0|0] "" GTW
 SG_ RCM_pasCLCrosCoup m16447 : 21|1@1+ (1,0) [0|0] "" GTW
 SG_ RCM_pasCLSht2Bat m16447 : 22|1@1+ (1,0) [0|0] "" GTW
 SG_ RCM_pasCLSht2Gnd m16447 : 23|1@1+ (1,0) [0|0] "" GTW
 SG_ RCM_pasBLDefect m16448 : 16|1@1+ (1,0) [0|0] "" GTW
 SG_ RCM_pasBLplaus m16448 : 17|1@1+ (1,0) [0|0] "" GTW
 SG_ RCM_pasBLOption m16448 : 18|1@1+ (1,0) [0|0] "" GTW
 SG_ RCM_pasBLInitTyp m16448 : 19|1@1+ (1,0) [0|0] "" GTW
 SG_ RCM_pasBLExComm m16448 : 20|1@1+ (1,0) [0|0] "" GTW
 SG_ RCM_pasBLCLosCoup m16448 : 21|1@1+ (1,0) [0|0] "" GTW
 SG_ RCM_pasBLSht2Bat m16448 : 22|1@1+ (1,0) [0|0] "" GTW
 SG_ RCM_pasBLSht2Gnd m16448 : 23|1@1+ (1,0) [0|0] "" GTW
 SG_ RCM_ufsLDefect m16449 : 16|1@1+ (1,0) [0|0] "" GTW
 SG_ RCM_ufsLplaus m16449 : 17|1@1+ (1,0) [0|0] "" GTW
 SG_ RCM_ufsLOption m16449 : 18|1@1+ (1,0) [0|0] "" GTW
 SG_ RCM_ufsLInitTyp m16449 : 19|1@1+ (1,0) [0|0] "" GTW
 SG_ RCM_ufsLExComm m16449 : 20|1@1+ (1,0) [0|0] "" GTW
 SG_ RCM_ufsLCrosCoup m16449 : 21|1@1+ (1,0) [0|0] "" GTW
 SG_ RCM_ufsLSht2Bat m16449 : 22|1@1+ (1,0) [0|0] "" GTW
 SG_ RCM_ufsLSht2Gnd m16449 : 23|1@1+ (1,0) [0|0] "" GTW
 SG_ RCM_loadLimRightCfg m16450 : 16|1@1+ (1,0) [0|0] "" GTW
 SG_ RCM_loadLimRightCrosCoup m16450 : 17|1@1+ (1,0) [0|0] "" GTW
 SG_ RCM_loadLimRightShort m16450 : 18|1@1+ (1,0) [0|0] "" GTW
 SG_ RCM_loadLimRightOpen m16450 : 19|1@1+ (1,0) [0|0] "" GTW
 SG_ RCM_loadLimRightSht2Bat m16450 : 20|1@1+ (1,0) [0|0] "" GTW
 SG_ RCM_loadLimRightSht2Gnd m16450 : 21|1@1+ (1,0) [0|0] "" GTW
 SG_ RCM_loadLimLeftCfg m16451 : 16|1@1+ (1,0) [0|0] "" GTW
 SG_ RCM_loadLimLeftCrosCoup m16451 : 17|1@1+ (1,0) [0|0] "" GTW
 SG_ RCM_loadLimLeftShort m16451 : 18|1@1+ (1,0) [0|0] "" GTW
 SG_ RCM_loadLimLeftOpen m16451 : 19|1@1+ (1,0) [0|0] "" GTW
 SG_ RCM_loadLimLeftSht2Bat m16451 : 20|1@1+ (1,0) [0|0] "" GTW
 SG_ RCM_loadLimLeftSht2Gnd m16451 : 21|1@1+ (1,0) [0|0] "" GTW
 SG_ RCM_curAB3rdRowRCfg m16452 : 16|1@1+ (1,0) [0|0] "" GTW
 SG_ RCM_curAB3rdRowRCrosCoup m16452 : 17|1@1+ (1,0) [0|0] "" GTW
 SG_ RCM_curAB3rdRowRShort m16452 : 18|1@1+ (1,0) [0|0] "" GTW
 SG_ RCM_curAB3rdRowROpen m16452 : 19|1@1+ (1,0) [0|0] "" GTW
 SG_ RCM_curAB3rdRowRSht2Bat m16452 : 20|1@1+ (1,0) [0|0] "" GTW
 SG_ RCM_curAB3rdRowRSht2Gnd m16452 : 21|1@1+ (1,0) [0|0] "" GTW
 SG_ RCM_curAB2ndRowRCfg m16453 : 16|1@1+ (1,0) [0|0] "" GTW
 SG_ RCM_curAB2ndRowRCrosCoup m16453 : 17|1@1+ (1,0) [0|0] "" GTW
 SG_ RCM_curAB2ndRowRShort m16453 : 18|1@1+ (1,0) [0|0] "" GTW
 SG_ RCM_curAB2ndRowROpen m16453 : 19|1@1+ (1,0) [0|0] "" GTW
 SG_ RCM_curAB2ndRowRSht2Bat m16453 : 20|1@1+ (1,0) [0|0] "" GTW
 SG_ RCM_curAB2ndRowRSht2Gnd m16453 : 21|1@1+ (1,0) [0|0] "" GTW
 SG_ RCM_curAB2ndRowLCfg m16454 : 16|1@1+ (1,0) [0|0] "" GTW
 SG_ RCM_curAB2ndRowLCrosCoup m16454 : 17|1@1+ (1,0) [0|0] "" GTW
 SG_ RCM_curAB2ndRowLShort m16454 : 18|1@1+ (1,0) [0|0] "" GTW
 SG_ RCM_curAB2ndRowLOpen m16454 : 19|1@1+ (1,0) [0|0] "" GTW
 SG_ RCM_curAB2ndRowLSht2Bat m16454 : 20|1@1+ (1,0) [0|0] "" GTW
 SG_ RCM_curAB2ndRowLSht2Gnd m16454 : 21|1@1+ (1,0) [0|0] "" GTW
 SG_ RCM_preten2ndRowRCgf m16455 : 16|1@1+ (1,0) [0|0] "" GTW
 SG_ RCM_preten2ndRowRCrosCou m16455 : 17|1@1+ (1,0) [0|0] "" GTW
 SG_ RCM_preten2ndRowRShort m16455 : 18|1@1+ (1,0) [0|0] "" GTW
 SG_ RCM_preten2ndRowROpen m16455 : 19|1@1+ (1,0) [0|0] "" GTW
 SG_ RCM_preten2ndRowRSht2Bat m16455 : 20|1@1+ (1,0) [0|0] "" GTW
 SG_ RCM_preten2ndRowRSht2Gnd m16455 : 21|1@1+ (1,0) [0|0] "" GTW
 SG_ RCM_curAB3rdRowLCfg m16456 : 16|1@1+ (1,0) [0|0] "" GTW
 SG_ RCM_curAB3rdRowLCrosCoup m16456 : 17|1@1+ (1,0) [0|0] "" GTW
 SG_ RCM_curAB3rdRowLShort m16456 : 18|1@1+ (1,0) [0|0] "" GTW
 SG_ RCM_curAB3rdRowLOpen m16456 : 19|1@1+ (1,0) [0|0] "" GTW
 SG_ RCM_curAB3rdRowLSht2Bat m16456 : 20|1@1+ (1,0) [0|0] "" GTW
 SG_ RCM_curAB3rdRowLSht2Gnd m16456 : 21|1@1+ (1,0) [0|0] "" GTW
 SG_ RCM_preten2ndRowLCgf m16457 : 16|1@1+ (1,0) [0|0] "" GTW
 SG_ RCM_preten2ndRowLCrosCou m16457 : 17|1@1+ (1,0) [0|0] "" GTW
 SG_ RCM_preten2ndRowLShort m16457 : 18|1@1+ (1,0) [0|0] "" GTW
 SG_ RCM_preten2ndRowLOpen m16457 : 19|1@1+ (1,0) [0|0] "" GTW
 SG_ RCM_preten2ndRowLSht2Bat m16457 : 20|1@1+ (1,0) [0|0] "" GTW
 SG_ RCM_preten2ndRowLSht2Gnd m16457 : 21|1@1+ (1,0) [0|0] "" GTW
 SG_ RCM_siAB2ndRowRCfg m16458 : 16|1@1+ (1,0) [0|0] "" GTW
 SG_ RCM_siAB2ndRowRCrosCoup m16458 : 17|1@1+ (1,0) [0|0] "" GTW
 SG_ RCM_siAB2ndRowRShort m16458 : 18|1@1+ (1,0) [0|0] "" GTW
 SG_ RCM_siAB2ndRowROpen m16458 : 19|1@1+ (1,0) [0|0] "" GTW
 SG_ RCM_siAB2ndRowRSht2Bat m16458 : 20|1@1+ (1,0) [0|0] "" GTW
 SG_ RCM_siAB2ndRowRSht2Gnd m16458 : 21|1@1+ (1,0) [0|0] "" GTW
 SG_ RCM_siAB2ndRowLCfg m16459 : 16|1@1+ (1,0) [0|0] "" GTW
 SG_ RCM_siAB2ndRowLCrosCoup m16459 : 17|1@1+ (1,0) [0|0] "" GTW
 SG_ RCM_siAB2ndRowLShort m16459 : 18|1@1+ (1,0) [0|0] "" GTW
 SG_ RCM_siAB2ndRowLOpen m16459 : 19|1@1+ (1,0) [0|0] "" GTW
 SG_ RCM_siAB2ndRowLSht2Bat m16459 : 20|1@1+ (1,0) [0|0] "" GTW
 SG_ RCM_siAB2ndRowLSht2Gnd m16459 : 21|1@1+ (1,0) [0|0] "" GTW
 SG_ RCM_hwcp3Cfg m16460 : 16|1@1+ (1,0) [0|0] "" GTW
 SG_ RCM_hwcp3CheckFail m16460 : 17|1@1+ (1,0) [0|0] "" GTW
 SG_ RCM_hwcp3CrosCoup m16460 : 18|1@1+ (1,0) [0|0] "" GTW
 SG_ RCM_hwcp3Undefined m16460 : 19|1@1+ (1,0) [0|0] "" GTW
 SG_ RCM_hwcp3Open m16460 : 20|1@1+ (1,0) [0|0] "" GTW
 SG_ RCM_hwcp3Sht2Bat m16460 : 21|1@1+ (1,0) [0|0] "" GTW
 SG_ RCM_hwcp3Short m16460 : 22|1@1+ (1,0) [0|0] "" GTW
 SG_ RCM_hwcp2Cfg m16461 : 16|1@1+ (1,0) [0|0] "" GTW
 SG_ RCM_hwcp2CheckFail m16461 : 17|1@1+ (1,0) [0|0] "" GTW
 SG_ RCM_hwcp2CrosCoup m16461 : 18|1@1+ (1,0) [0|0] "" GTW
 SG_ RCM_hwcp2Undefined m16461 : 19|1@1+ (1,0) [0|0] "" GTW
 SG_ RCM_hwcp2Open m16461 : 20|1@1+ (1,0) [0|0] "" GTW
 SG_ RCM_hwcp2Sht2Bat m16461 : 21|1@1+ (1,0) [0|0] "" GTW
 SG_ RCM_hwcp2Short m16461 : 22|1@1+ (1,0) [0|0] "" GTW
 SG_ RCM_hwcp1Cfg m16462 : 16|1@1+ (1,0) [0|0] "" GTW
 SG_ RCM_hwcp1CheckFail m16462 : 17|1@1+ (1,0) [0|0] "" GTW
 SG_ RCM_hwcp1CrosCoup m16462 : 18|1@1+ (1,0) [0|0] "" GTW
 SG_ RCM_hwcp1Undefined m16462 : 19|1@1+ (1,0) [0|0] "" GTW
 SG_ RCM_hwcp1Open m16462 : 20|1@1+ (1,0) [0|0] "" GTW
 SG_ RCM_hwcp1Sht2Bat m16462 : 21|1@1+ (1,0) [0|0] "" GTW
 SG_ RCM_hwcp1Short m16462 : 22|1@1+ (1,0) [0|0] "" GTW
 SG_ RCM_buckleHallRightCfg m16463 : 16|1@1+ (1,0) [0|0] "" GTW
 SG_ RCM_buckleSwRightCfg m16463 : 17|1@1+ (1,0) [0|0] "" GTW
 SG_ RCM_buckleHallRightCrosCo m16463 : 18|1@1+ (1,0) [0|0] "" GTW
 SG_ RCM_buckleHallRightUndef m16463 : 19|1@1+ (1,0) [0|0] "" GTW
 SG_ RCM_buckleHallRightOpen m16463 : 20|1@1+ (1,0) [0|0] "" GTW
 SG_ RCM_buckleHallRightSht2Ba m16463 : 21|1@1+ (1,0) [0|0] "" GTW
 SG_ RCM_buckleHallRightShort m16463 : 22|1@1+ (1,0) [0|0] "" GTW
 SG_ RCM_buckleHallLeftCfg m16464 : 16|1@1+ (1,0) [0|0] "" GTW
 SG_ RCM_buckleSwLeftCfg m16464 : 17|1@1+ (1,0) [0|0] "" GTW
 SG_ RCM_buckleHallLeftCrosCo m16464 : 18|1@1+ (1,0) [0|0] "" GTW
 SG_ RCM_buckleHallLeftUndef m16464 : 19|1@1+ (1,0) [0|0] "" GTW
 SG_ RCM_buckleHallLeftOpen m16464 : 20|1@1+ (1,0) [0|0] "" GTW
 SG_ RCM_buckleHallLeftSht2Ba m16464 : 21|1@1+ (1,0) [0|0] "" GTW
 SG_ RCM_buckleHallLeftShort m16464 : 22|1@1+ (1,0) [0|0] "" GTW
 SG_ RCM_curAB1stRowRCfg m16465 : 16|1@1+ (1,0) [0|0] "" GTW
 SG_ RCM_curAB1stRowRCrosCoup m16465 : 17|1@1+ (1,0) [0|0] "" GTW
 SG_ RCM_curAB1stRowRShort m16465 : 18|1@1+ (1,0) [0|0] "" GTW
 SG_ RCM_curAB1stRowROpen m16465 : 19|1@1+ (1,0) [0|0] "" GTW
 SG_ RCM_curAB1stRowRSht2Bat m16465 : 20|1@1+ (1,0) [0|0] "" GTW
 SG_ RCM_curAB1stRowRSht2Gnd m16465 : 21|1@1+ (1,0) [0|0] "" GTW
 SG_ RCM_siAB1stRowRCfg m16466 : 16|1@1+ (1,0) [0|0] "" GTW
 SG_ RCM_siAB1stRowRCrosCoup m16466 : 17|1@1+ (1,0) [0|0] "" GTW
 SG_ RCM_siAB1stRowRShort m16466 : 18|1@1+ (1,0) [0|0] "" GTW
 SG_ RCM_siAB1stRowROpen m16466 : 19|1@1+ (1,0) [0|0] "" GTW
 SG_ RCM_siAB1stRowRSht2Bat m16466 : 20|1@1+ (1,0) [0|0] "" GTW
 SG_ RCM_siAB1stRowRSht2Gnd m16466 : 21|1@1+ (1,0) [0|0] "" GTW
 SG_ RCM_curAB1stRowLCfg m16467 : 16|1@1+ (1,0) [0|0] "" GTW
 SG_ RCM_curAB1stRowLCrosCoup m16467 : 17|1@1+ (1,0) [0|0] "" GTW
 SG_ RCM_curAB1stRowLShort m16467 : 18|1@1+ (1,0) [0|0] "" GTW
 SG_ RCM_curAB1stRowLOpen m16467 : 19|1@1+ (1,0) [0|0] "" GTW
 SG_ RCM_curAB1stRowLSht2Bat m16467 : 20|1@1+ (1,0) [0|0] "" GTW
 SG_ RCM_curAB1stRowLSht2Gnd m16467 : 21|1@1+ (1,0) [0|0] "" GTW
 SG_ RCM_siAB1stRowLCfg m16468 : 16|1@1+ (1,0) [0|0] "" GTW
 SG_ RCM_siAB1stRowLCrosCoup m16468 : 17|1@1+ (1,0) [0|0] "" GTW
 SG_ RCM_siAB1stRowLShort m16468 : 18|1@1+ (1,0) [0|0] "" GTW
 SG_ RCM_siAB1stRowLOpen m16468 : 19|1@1+ (1,0) [0|0] "" GTW
 SG_ RCM_siAB1stRowLSht2Bat m16468 : 20|1@1+ (1,0) [0|0] "" GTW
 SG_ RCM_siAB1stRowLSht2Gnd m16468 : 21|1@1+ (1,0) [0|0] "" GTW
 SG_ RCM_pabStg2Cfg m16469 : 16|1@1+ (1,0) [0|0] "" GTW
 SG_ RCM_pabStg2CrosCo m16469 : 17|1@1+ (1,0) [0|0] "" GTW
 SG_ RCM_pabStg2Short m16469 : 18|1@1+ (1,0) [0|0] "" GTW
 SG_ RCM_pabStg2Open m16469 : 19|1@1+ (1,0) [0|0] "" GTW
 SG_ RCM_pabStg2Sht2Ba m16469 : 20|1@1+ (1,0) [0|0] "" GTW
 SG_ RCM_pabStg2Sht2Gn m16469 : 21|1@1+ (1,0) [0|0] "" GTW
 SG_ RCM_pabStg1Cfg m16470 : 16|1@1+ (1,0) [0|0] "" GTW
 SG_ RCM_pabStg1CrosCo m16470 : 17|1@1+ (1,0) [0|0] "" GTW
 SG_ RCM_pabStg1Short m16470 : 18|1@1+ (1,0) [0|0] "" GTW
 SG_ RCM_pabStg1Open m16470 : 19|1@1+ (1,0) [0|0] "" GTW
 SG_ RCM_pabStg1Sht2Ba m16470 : 20|1@1+ (1,0) [0|0] "" GTW
 SG_ RCM_pabStg1Sht2Gn m16470 : 21|1@1+ (1,0) [0|0] "" GTW
 SG_ RCM_hvDisconnectCfg m16471 : 16|1@1+ (1,0) [0|0] "" GTW
 SG_ RCM_hvDisconnectCrosCoup m16471 : 17|1@1+ (1,0) [0|0] "" GTW
 SG_ RCM_hvDisconnectShort m16471 : 18|1@1+ (1,0) [0|0] "" GTW
 SG_ RCM_hvDisconnectOpen m16471 : 19|1@1+ (1,0) [0|0] "" GTW
 SG_ RCM_hvDisconnectSht2Bat m16471 : 20|1@1+ (1,0) [0|0] "" GTW
 SG_ RCM_hvDisconnectSht2Gnd m16471 : 21|1@1+ (1,0) [0|0] "" GTW
 SG_ RCM_kneeABDrvrCfg m16472 : 16|1@1+ (1,0) [0|0] "" GTW
 SG_ RCM_kneeABDrvrCrosCoup m16472 : 17|1@1+ (1,0) [0|0] "" GTW
 SG_ RCM_kneeABDrvrShort m16472 : 18|1@1+ (1,0) [0|0] "" GTW
 SG_ RCM_kneeABDrvrOpen m16472 : 19|1@1+ (1,0) [0|0] "" GTW
 SG_ RCM_kneeABDrvrSht2Bat m16472 : 20|1@1+ (1,0) [0|0] "" GTW
 SG_ RCM_kneeABDrvrSht2Gnd m16472 : 21|1@1+ (1,0) [0|0] "" GTW
 SG_ RCM_dabStg2Cfg m16473 : 16|1@1+ (1,0) [0|0] "" GTW
 SG_ RCM_dabStg2CrosCo m16473 : 17|1@1+ (1,0) [0|0] "" GTW
 SG_ RCM_dabStg2Short m16473 : 18|1@1+ (1,0) [0|0] "" GTW
 SG_ RCM_dabStg2Open m16473 : 19|1@1+ (1,0) [0|0] "" GTW
 SG_ RCM_dabStg2Sht2Ba m16473 : 20|1@1+ (1,0) [0|0] "" GTW
 SG_ RCM_dabStg2Sht2Gn m16473 : 21|1@1+ (1,0) [0|0] "" GTW
 SG_ RCM_dabStg1Cfg m16474 : 16|1@1+ (1,0) [0|0] "" GTW
 SG_ RCM_dabStg1CrosCo m16474 : 17|1@1+ (1,0) [0|0] "" GTW
 SG_ RCM_dabStg1Short m16474 : 18|1@1+ (1,0) [0|0] "" GTW
 SG_ RCM_dabStg1Open m16474 : 19|1@1+ (1,0) [0|0] "" GTW
 SG_ RCM_dabStg1Sht2Ba m16474 : 20|1@1+ (1,0) [0|0] "" GTW
 SG_ RCM_dabStg1Sht2Gn m16474 : 21|1@1+ (1,0) [0|0] "" GTW
 SG_ RCM_comGTWCarStateTO m16475 : 16|1@1+ (1,0) [0|0] "" GTW
 SG_ RCM_driverOrientiInitNC m16476 : 16|1@1+ (1,0) [0|0] "" GTW
 SG_ RCM_driverOrientPlausi m16476 : 17|1@1+ (1,0) [0|0] "" GTW
 SG_ RCM_scmUnavailable m16477 : 16|1@1+ (1,0) [0|0] "" GTW
 SG_ RCM_comGTWESP1TO m16478 : 16|1@1+ (1,0) [0|0] "" GTW
 SG_ RCM_comGTWESP1CRC m16478 : 17|1@1+ (1,0) [0|0] "" GTW
 SG_ RCM_comGTWESP1Cnt m16478 : 18|1@1+ (1,0) [0|0] "" GTW
 SG_ RCM_comDasIDFTO m16479 : 16|1@1+ (1,0) [0|0] "" GTW
 SG_ RCM_comDasIDFCRC m16479 : 17|1@1+ (1,0) [0|0] "" GTW
 SG_ RCM_comDasIDFCntr m16479 : 18|1@1+ (1,0) [0|0] "" GTW
 SG_ RCM_comDasStatusTO m16480 : 16|1@1+ (1,0) [0|0] "" GTW
 SG_ RCM_comDasStatusCRC m16480 : 17|1@1+ (1,0) [0|0] "" GTW
 SG_ RCM_comDasStatusCntr m16480 : 18|1@1+ (1,0) [0|0] "" GTW
 SG_ RCM_comDiStateTO m16481 : 16|1@1+ (1,0) [0|0] "" GTW
 SG_ RCM_comDiStateCRC m16481 : 17|1@1+ (1,0) [0|0] "" GTW
 SG_ RCM_comDiStateCntr m16481 : 18|1@1+ (1,0) [0|0] "" GTW
 SG_ RCM_comDiState2TO m16482 : 16|1@1+ (1,0) [0|0] "" GTW
 SG_ RCM_comDiState2CRC m16482 : 17|1@1+ (1,0) [0|0] "" GTW
 SG_ RCM_comDiState2Cntr m16482 : 18|1@1+ (1,0) [0|0] "" GTW
 SG_ RCM_pedProPTSLDefect m16483 : 16|1@1+ (1,0) [0|0] "" GTW
 SG_ RCM_pedProPTSLplaus m16483 : 17|1@1+ (1,0) [0|0] "" GTW
 SG_ RCM_pedProPTSLOption m16483 : 18|1@1+ (1,0) [0|0] "" GTW
 SG_ RCM_pedProPTSLInitTyp m16483 : 19|1@1+ (1,0) [0|0] "" GTW
 SG_ RCM_pedProPTSLExComm m16483 : 20|1@1+ (1,0) [0|0] "" GTW
 SG_ RCM_pedProPTSLCrosCoup m16483 : 21|1@1+ (1,0) [0|0] "" GTW
 SG_ RCM_pedProPTSLSht2Bat m16483 : 22|1@1+ (1,0) [0|0] "" GTW
 SG_ RCM_pedProPTSLSht2Gnd m16483 : 23|1@1+ (1,0) [0|0] "" GTW
 SG_ RCM_pedProPTSRDefect m16484 : 16|1@1+ (1,0) [0|0] "" GTW
 SG_ RCM_pedProPTSRplaus m16484 : 17|1@1+ (1,0) [0|0] "" GTW
 SG_ RCM_pedProPTSROption m16484 : 18|1@1+ (1,0) [0|0] "" GTW
 SG_ RCM_pedProPTSRInitTyp m16484 : 19|1@1+ (1,0) [0|0] "" GTW
 SG_ RCM_pedProPTSRExComm m16484 : 20|1@1+ (1,0) [0|0] "" GTW
 SG_ RCM_pedProPTSRCLosCoup m16484 : 21|1@1+ (1,0) [0|0] "" GTW
 SG_ RCM_pedProPTSRSht2Bat m16484 : 22|1@1+ (1,0) [0|0] "" GTW
 SG_ RCM_pedProPTSRSht2Gnd m16484 : 23|1@1+ (1,0) [0|0] "" GTW
 SG_ RCM_comVCSEATPrestTO m16485 : 16|1@1+ (1,0) [0|0] "" GTW
 SG_ RCM_comVCSEATPrestCRC m16485 : 17|1@1+ (1,0) [0|0] "" GTW
 SG_ RCM_comVCSEATPrestCntr m16485 : 18|1@1+ (1,0) [0|0] "" GTW
 SG_ RCM_comBucklePassenger m16485 : 19|1@1+ (1,0) [0|0] "" GTW
 SG_ RCM_comOccupancyPassenger m16485 : 20|1@1+ (1,0) [0|0] "" GTW
 SG_ RCM_comOCSclassification m16485 : 21|1@1+ (1,0) [0|0] "" GTW
 SG_ RCM_comTrackPositionPass m16485 : 22|1@1+ (1,0) [0|0] "" GTW
 SG_ RCM_comVCSEATDrestTO m16486 : 16|1@1+ (1,0) [0|0] "" GTW
 SG_ RCM_comVCSEATDrestCRC m16486 : 17|1@1+ (1,0) [0|0] "" GTW
 SG_ RCM_comVCSEATDrestCntr m16486 : 18|1@1+ (1,0) [0|0] "" GTW
 SG_ RCM_comBuckleDriver m16486 : 19|1@1+ (1,0) [0|0] "" GTW
 SG_ RCM_comOccupancyDriver m16486 : 20|1@1+ (1,0) [0|0] "" GTW
 SG_ RCM_comTrackPositionDrvr m16486 : 21|1@1+ (1,0) [0|0] "" GTW
 SG_ RCM_crashDetectedFront m16487 : 16|1@1+ (1,0) [0|0] "" GTW
 SG_ RCM_crashDetectedRear m16487 : 17|1@1+ (1,0) [0|0] "" GTW
 SG_ RCM_crashDetectedLeft m16487 : 18|1@1+ (1,0) [0|0] "" GTW
 SG_ RCM_crashDetectedRight m16487 : 19|1@1+ (1,0) [0|0] "" GTW
 SG_ RCM_crashDetectedRoll m16487 : 20|1@1+ (1,0) [0|0] "" GTW
 SG_ RCM_crashDetectedPreten m16487 : 21|1@1+ (1,0) [0|0] "" GTW
 SG_ RCM_crashDetectedStage1 m16487 : 22|1@1+ (1,0) [0|0] "" GTW
 SG_ RCM_crashDetectedStage2 m16487 : 23|1@1+ (1,0) [0|0] "" GTW
 SG_ RCM_crashDetectedHVpyro m16487 : 24|1@1+ (1,0) [0|0] "" GTW
 SG_ RCM_nearDeployFront m16488 : 16|1@1+ (1,0) [0|0] "" GTW
 SG_ RCM_nearDeployRear m16488 : 17|1@1+ (1,0) [0|0] "" GTW
 SG_ RCM_nearDeployLeft m16488 : 18|1@1+ (1,0) [0|0] "" GTW
 SG_ RCM_nearDeployRight m16488 : 19|1@1+ (1,0) [0|0] "" GTW
 SG_ RCM_nearDeployRoll m16488 : 20|1@1+ (1,0) [0|0] "" GTW
 SG_ RCM_airbagsUnArmed m16489 : 16|1@1+ (1,0) [0|0] "" GTW
 SG_ RCM_warningIndicatorOn m16490 : 16|1@1+ (1,0) [0|0] "" GTW
 SG_ RCM_pedProDeployment m16491 : 16|1@1+ (1,0) [0|0] "" GTW
 SG_ RCM_pedProNearDeployment m16492 : 16|1@1+ (1,0) [0|0] "" GTW
 SG_ RCM_immunityThrshold m16493 : 16|1@1+ (1,0) [0|0] "" GTW
 SG_ RCM_ndCrashCal m16494 : 16|1@1+ (1,0) [0|0] "" GTW
 SG_ RCM_ndPedProCal m16495 : 16|1@1+ (1,0) [0|0] "" GTW

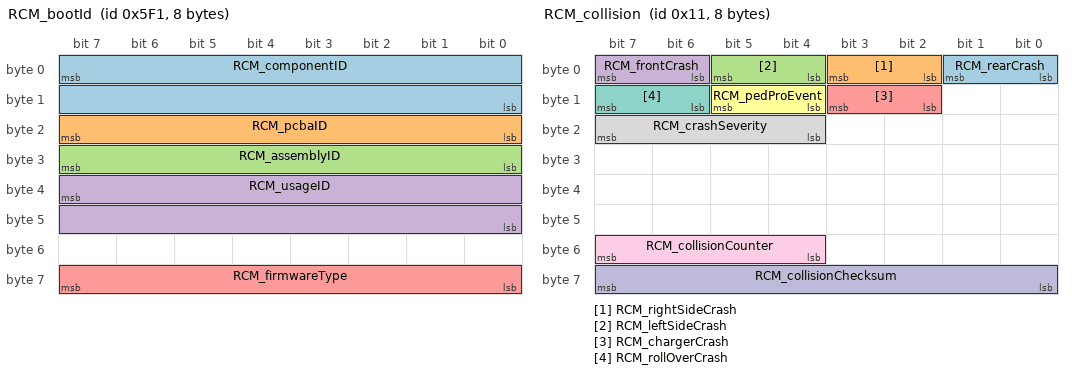
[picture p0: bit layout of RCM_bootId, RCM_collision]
BO_ 1521 RCM_bootId: 8 RCM
 SG_ RCM_componentID : 7|16@0+ (1,0) [0|65535] "" Vector__XXX
 SG_ RCM_pcbaID : 23|8@0+ (1,0) [0|255] "" Vector__XXX
 SG_ RCM_assemblyID : 31|8@0+ (1,0) [0|255] "" Vector__XXX
 SG_ RCM_usageID : 39|16@0+ (1,0) [0|65535] "" Vector__XXX
 SG_ RCM_firmwareType : 63|8@0+ (1,0) [0|255] "" Vector__XXX

BO_ 17 RCM_collision: 8 RCM
 SG_ RCM_rearCrash : 1|2@0+ (1,0) [0|3] "" BCCEN,GTW,OCS,DAS,TAS
 SG_ RCM_rightSideCrash : 3|2@0+ (1,0) [0|3] "" BCCEN,GTW,OCS,DAS,TAS
 SG_ RCM_leftSideCrash : 5|2@0+ (1,0) [0|3] "" BCCEN,GTW,OCS,DAS,TAS
 SG_ RCM_frontCrash : 7|2@0+ (1,0) [0|3] "" BCCEN,GTW,OCS,DAS,TAS
 SG_ RCM_chargerCrash : 11|2@0+ (1,0) [0|3] "" BCCEN,GTW,OCS,DAS,TAS
 SG_ RCM_pedProEvent : 13|2@0+ (1,0) [0|3] "" BCCEN,GTW,OCS,DAS
 SG_ RCM_rollOverCrash : 15|2@0+ (1,0) [0|3] "" BCCEN,GTW,OCS,DAS,TAS
 SG_ RCM_crashSeverity : 23|4@0+ (1,0) [0|15] "" BCCEN,GTW,OCS
 SG_ RCM_collisionCounter : 55|4@0+ (1,0) [0|15] "" GTW,BCCEN,DAS,TAS
 SG_ RCM_collisionChecksum : 63|8@0+ (1,0) [0|255] "" GTW,BCCEN,DAS,TAS

BO_ 881 RCM_dtcMatrix: 8 RCM
 SG_ RCM_dtcIndex M : 0|8@1+ (1,0) [0|255] "" GTW
 SG_ RCM_d000_comFault1 m0 : 8|2@1+ (1,0) [0|0] "" GTW
 SG_ RCM_d001_vBatRange m0 : 10|2@1+ (1,0) [0|0] "" GTW
 SG_ RCM_d002_vinMismatch m0 : 12|2@1+ (1,0) [0|0] "" GTW
 SG_ RCM_d003_swVersionMismatch m0 : 14|2@1+ (1,0) [0|0] "" GTW
 SG_ RCM_d004_idleMode m0 : 16|2@1+ (1,0) [0|0] "" GTW
 SG_ RCM_d005_internalHard m0 : 18|2@1+ (1,0) [0|0] "" GTW
 SG_ RCM_d006_crashAlgoDisabled m0 : 20|2@1+ (1,0) [0|0] "" GTW
 SG_ RCM_d007_eolProgMismatch m0 : 22|2@1+ (1,0) [0|0] "" GTW
 SG_ RCM_d008_crcErrorExternal m0 : 24|2@1+ (1,0) [0|0] "" GTW
 SG_ RCM_d009_cfgFault m0 : 26|2@1+ (1,0) [0|0] "" GTW
 SG_ RCM_d010_crashCalPNMissing m0 : 28|2@1+ (1,0) [0|0] "" GTW
 SG_ RCM_d011_vdsFieldCalibFailed m0 : 30|2@1+ (1,0) [0|0] "" GTW
 SG_ RCM_d012_vdsChannelSigMonTmp m0 : 32|2@1+ (1,0) [0|0] "" GTW
 SG_ RCM_d013_vdsFieldCalibNotDone m0 : 34|2@1+ (1,0) [0|0] "" GTW
 SG_ RCM_d014_vdsChannelSigMonPerm m0 : 36|2@1+ (1,0) [0|0] "" GTW
 SG_ RCM_d015_vdsSensorMonitorTemp m0 : 38|2@1+ (1,0) [0|0] "" GTW
 SG_ RCM_d016_comCANInitFailure m0 : 40|2@1+ (1,0) [0|0] "" GTW
 SG_ RCM_d017_comGTWCarConfig m0 : 42|2@1+ (1,0) [0|0] "" GTW
 SG_ RCM_d018_vinEmptyError m0 : 44|2@1+ (1,0) [0|0] "" GTW
 SG_ RCM_d019_comESPC m0 : 46|2@1+ (1,0) [0|0] "" GTW
 SG_ RCM_d020_comESP135 m0 : 48|2@1+ (1,0) [0|0] "" GTW
 SG_ RCM_d021_comEPBStatus m0 : 50|2@1+ (1,0) [0|0] "" GTW
 SG_ RCM_d022_comBCS2RStatus m0 : 52|2@1+ (1,0) [0|0] "" GTW
 SG_ RCM_d023_comBCS2LStatus m0 : 54|2@1+ (1,0) [0|0] "" GTW
 SG_ RCM_d024_comBCS2CStatus m0 : 56|2@1+ (1,0) [0|0] "" GTW
 SG_ RCM_d025_comTPMSStatus m0 : 58|2@1+ (1,0) [0|0] "" GTW
 SG_ RCM_d026_airbagWarnMismatch m0 : 60|2@1+ (1,0) [0|0] "" GTW
 SG_ RCM_d027_ocsFailure m0 : 62|2@1+ (1,0) [0|0] "" GTW
 SG_ RCM_d028_comGTWACS m1 : 8|2@1+ (1,0) [0|0] "" GTW
 SG_ RCM_d029_comChassisBusOff m1 : 10|2@1+ (1,0) [0|0] "" GTW
 SG_ RCM_d030_comStwAngle m1 : 12|2@1+ (1,0) [0|0] "" GTW
 SG_ RCM_d031_comESP145 m1 : 14|2@1+ (1,0) [0|0] "" GTW
 SG_ RCM_d032_comDITorque2 m1 : 16|2@1+ (1,0) [0|0] "" GTW
 SG_ RCM_d033_comDITorque1 m1 : 18|2@1+ (1,0) [0|0] "" GTW
 SG_ RCM_d034_comESPB m1 : 20|2@1+ (1,0) [0|0] "" GTW
 SG_ RCM_d035_comGTWOdo m1 : 22|2@1+ (1,0) [0|0] "" GTW
 SG_ RCM_d036_comBusOff m1 : 24|2@1+ (1,0) [0|0] "" GTW
 SG_ RCM_d037_comMissingVehConfg m1 : 26|2@1+ (1,0) [0|0] "" GTW
 SG_ RCM_d038_seatBackSw2ndRowLeft m1 : 28|2@1+ (1,0) [0|0] "" GTW
 SG_ RCM_d039_pretenLapFrontRight m1 : 30|2@1+ (1,0) [0|0] "" GTW
 SG_ RCM_d040_pretenLapFrontLeft m1 : 32|2@1+ (1,0) [0|0] "" GTW
 SG_ RCM_d041_pretenShldFrontRight m1 : 34|2@1+ (1,0) [0|0] "" GTW
 SG_ RCM_d042_pretenShldrFrontLeft m1 : 36|2@1+ (1,0) [0|0] "" GTW
 SG_ RCM_d043_passABLampOnHardWire m1 : 38|2@1+ (1,0) [0|0] "" GTW
 SG_ RCM_d044_pedProCrashDetected m1 : 40|2@1+ (1,0) [0|0] "" GTW
 SG_ RCM_d045_crashOutSignal m1 : 42|2@1+ (1,0) [0|0] "" GTW
 SG_ RCM_d046_passengerActiveVent m1 : 44|2@1+ (1,0) [0|0] "" GTW
 SG_ RCM_d047_kneeABFrontPassenger m1 : 46|2@1+ (1,0) [0|0] "" GTW
 SG_ RCM_d048_pressureFrontRtDoor m1 : 48|2@1+ (1,0) [0|0] "" GTW
 SG_ RCM_d049_pressureFrontLftDoor m1 : 50|2@1+ (1,0) [0|0] "" GTW
 SG_ RCM_d050_eepromDataLocked m1 : 52|2@1+ (1,0) [0|0] "" GTW
 SG_ RCM_d051_hoodActuatorLeft m1 : 54|2@1+ (1,0) [0|0] "" GTW
 SG_ RCM_d052_hoodActuatorRight m1 : 56|2@1+ (1,0) [0|0] "" GTW
 SG_ RCM_d053_sbsw2ndRowRight m1 : 58|2@1+ (1,0) [0|0] "" GTW
 SG_ RCM_d054_padLampHardWire m1 : 60|2@1+ (1,0) [0|0] "" GTW
 SG_ RCM_d055_passResOccupancySw m1 : 62|2@1+ (1,0) [0|0] "" GTW
 SG_ RCM_d056_stpsDriver m2 : 8|2@1+ (1,0) [0|0] "" GTW
 SG_ RCM_d057_pasDPillarLeftYAxis m2 : 10|2@1+ (1,0) [0|0] "" GTW
 SG_ RCM_d058_pasDPillarLeftXAxis m2 : 12|2@1+ (1,0) [0|0] "" GTW
 SG_ RCM_d059_pasDPillarRight m2 : 14|2@1+ (1,0) [0|0] "" GTW
 SG_ RCM_d060_pasCPillarRight m2 : 16|2@1+ (1,0) [0|0] "" GTW
 SG_ RCM_d061_pasBPillarRight m2 : 18|2@1+ (1,0) [0|0] "" GTW
 SG_ RCM_d062_ufsRightSide m2 : 20|2@1+ (1,0) [0|0] "" GTW
 SG_ RCM_d063_pasCPillarLeft m2 : 22|2@1+ (1,0) [0|0] "" GTW
 SG_ RCM_d064_pasBPillarLeft m2 : 24|2@1+ (1,0) [0|0] "" GTW
 SG_ RCM_d065_ufsLeftSide m2 : 26|2@1+ (1,0) [0|0] "" GTW
 SG_ RCM_d066_loadLimiterRightSide m2 : 28|2@1+ (1,0) [0|0] "" GTW
 SG_ RCM_d067_loadLimiterLeftSide m2 : 30|2@1+ (1,0) [0|0] "" GTW
 SG_ RCM_d068_curAB3rdRowRight m2 : 32|2@1+ (1,0) [0|0] "" GTW
 SG_ RCM_d069_curAB2ndRowRight m2 : 34|2@1+ (1,0) [0|0] "" GTW
 SG_ RCM_d070_curAB2ndRowLeft m2 : 36|2@1+ (1,0) [0|0] "" GTW
 SG_ RCM_d071_preten2ndRowRight m2 : 38|2@1+ (1,0) [0|0] "" GTW
 SG_ RCM_d072_curAB3rdRowLeft m2 : 40|2@1+ (1,0) [0|0] "" GTW
 SG_ RCM_d073_preten2ndRowLeft m2 : 42|2@1+ (1,0) [0|0] "" GTW
 SG_ RCM_d074_siAB2ndRowRight m2 : 44|2@1+ (1,0) [0|0] "" GTW
 SG_ RCM_d075_siAB2ndRowLeft m2 : 46|2@1+ (1,0) [0|0] "" GTW
 SG_ RCM_d076_hardwarCodingPin3 m2 : 48|2@1+ (1,0) [0|0] "" GTW
 SG_ RCM_d077_hardwareCodingPin2 m2 : 50|2@1+ (1,0) [0|0] "" GTW
 SG_ RCM_d078_hardwareCodingPin1 m2 : 52|2@1+ (1,0) [0|0] "" GTW
 SG_ RCM_d079_buckleRightSide m2 : 54|2@1+ (1,0) [0|0] "" GTW
 SG_ RCM_d080_buckleLeftSide m2 : 56|2@1+ (1,0) [0|0] "" GTW
 SG_ RCM_d081_curAB1stRowRight m2 : 58|2@1+ (1,0) [0|0] "" GTW
 SG_ RCM_d082_siAB1stRowRight m2 : 60|2@1+ (1,0) [0|0] "" GTW
 SG_ RCM_d083_curAB1stRowLeft m2 : 62|2@1+ (1,0) [0|0] "" GTW
 SG_ RCM_d084_siAB1stRowLeft m3 : 8|2@1+ (1,0) [0|0] "" GTW
 SG_ RCM_d085_pabStage2 m3 : 10|2@1+ (1,0) [0|0] "" GTW
 SG_ RCM_d086_pabStage1 m3 : 12|2@1+ (1,0) [0|0] "" GTW
 SG_ RCM_d087_hvDisconnect m3 : 14|2@1+ (1,0) [0|0] "" GTW
 SG_ RCM_d088_kneeABDriver m3 : 16|2@1+ (1,0) [0|0] "" GTW
 SG_ RCM_d089_dabStage2 m3 : 18|2@1+ (1,0) [0|0] "" GTW
 SG_ RCM_d090_dabStage1 m3 : 20|2@1+ (1,0) [0|0] "" GTW
 SG_ RCM_d091_comGTWCarState m3 : 22|2@1+ (1,0) [0|0] "" GTW
 SG_ RCM_d092_driverOrientation m3 : 24|2@1+ (1,0) [0|0] "" GTW
 SG_ RCM_d093_scmUnavailable m3 : 26|2@1+ (1,0) [0|0] "" GTW
 SG_ RCM_d094_comGTWESP1 m3 : 28|2@1+ (1,0) [0|0] "" GTW
 SG_ RCM_d095_comDasIDF m3 : 30|2@1+ (1,0) [0|0] "" GTW
 SG_ RCM_d096_comDasStatus m3 : 32|2@1+ (1,0) [0|0] "" GTW
 SG_ RCM_d097_comDIState m3 : 34|2@1+ (1,0) [0|0] "" GTW
 SG_ RCM_d098_comDIState2 m3 : 36|2@1+ (1,0) [0|0] "" GTW
 SG_ RCM_d099_pedProPTSL m3 : 38|2@1+ (1,0) [0|0] "" GTW
 SG_ RCM_d100_pedProPTSR m3 : 40|2@1+ (1,0) [0|0] "" GTW
 SG_ RCM_d101_comVCSEATPrest m3 : 42|2@1+ (1,0) [0|0] "" GTW
 SG_ RCM_d102_comVCSEATDrest m3 : 44|2@1+ (1,0) [0|0] "" GTW
 SG_ RCM_d103_crashDetected m3 : 46|2@1+ (1,0) [0|0] "" GTW
 SG_ RCM_d104_nearDeploy m3 : 48|2@1+ (1,0) [0|0] "" GTW
 SG_ RCM_d105_airbagsNotArmed m3 : 50|2@1+ (1,0) [0|0] "" GTW
 SG_ RCM_d106_warningIndicator m3 : 52|2@1+ (1,0) [0|0] "" GTW
 SG_ RCM_d107_pedProCrashDetected m3 : 54|2@1+ (1,0) [0|0] "" GTW
 SG_ RCM_d108_pedProNearDeploy m3 : 56|2@1+ (1,0) [0|0] "" GTW
 SG_ RCM_d109_abuseImmunity m3 : 58|2@1+ (1,0) [0|0] "" GTW
 SG_ RCM_d110_noDeployCrashCal m3 : 60|2@1+ (1,0) [0|0] "" GTW
 SG_ RCM_d111_noDeployPedProCal m3 : 62|2@1+ (1,0) [0|0] "" GTW

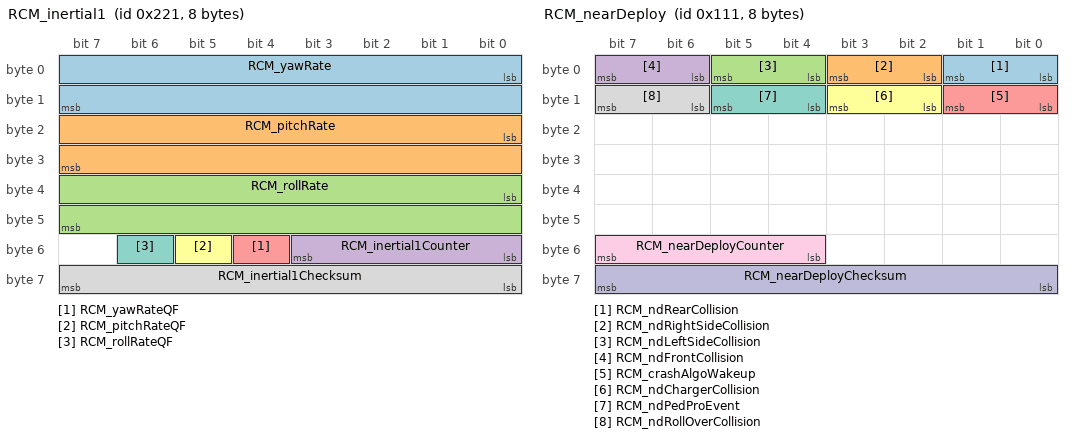
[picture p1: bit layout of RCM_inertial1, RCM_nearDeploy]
BO_ 545 RCM_inertial1: 8 RCM
 SG_ RCM_yawRate : 0|16@1+ (0.005,-163.84) [-163.84|163.835] "Deg/s" DBG
 SG_ RCM_pitchRate : 16|16@1+ (0.005,-163.84) [-163.84|163.83] "Deg/s" DBG
 SG_ RCM_rollRate : 32|16@1+ (0.005,-163.84) [-163.84|163.83] "Deg/s" DBG
 SG_ RCM_inertial1Counter : 51|4@0+ (1,0) [0|15] "" DBG
 SG_ RCM_yawRateQF : 52|1@1- (1,0) [0|0] "" DBG
 SG_ RCM_pitchRateQF : 53|1@1- (1,0) [0|0] "" DBG
 SG_ RCM_rollRateQF : 54|1@1- (1,0) [0|0] "" DBG
 SG_ RCM_inertial1Checksum : 63|8@0+ (1,0) [0|255] "" DBG

BO_ 849 RCM_info: 8 RCM
 SG_ RCM_infoIndex M : 0|8@1+ (1,0) [0|0] "" GTW,GTWU
 SG_ RCM_infoBuildType m10 : 8|8@1+ (1,0) [0|0] "" GTW,GTWU
 SG_ RCM_infoComponentID m10 : 48|16@1+ (1,0) [0|0] "" GTW,GTWU
 SG_ RCM_infoPcbaID m11 : 16|8@1+ (1,0) [0|0] "" GTW,GTWU
 SG_ RCM_infoAssemblyID m11 : 24|8@1+ (1,0) [0|255] "" GTW,GTWU
 SG_ RCM_infoUsageID m11 : 32|16@1+ (1,0) [0|65535] "" GTW,GTWU
 SG_ RCM_infoApplicationCRC m13 : 32|32@1+ (1,0) [0|0] "" GTW,GTWU
 SG_ RCM_infoBootUdsProtoVersion m20 : 8|8@1+ (1,0) [0|0] "" GTW,GTWU
 SG_ RCM_infoBootloaderCRC m20 : 32|32@1+ (1,0) [0|0] "" GTW,GTWU
 SG_ RCM_infoVariantCRC m22 : 32|32@1+ (1,0) [0|0] "" GTW,GTWU

BO_ 273 RCM_nearDeploy: 8 RCM
 SG_ RCM_ndRearCollision : 1|2@0+ (1,0) [0|3] "" GTW,DAS
 SG_ RCM_ndRightSideCollision : 3|2@0+ (1,0) [0|3] "" GTW,DAS
 SG_ RCM_ndLeftSideCollision : 5|2@0+ (1,0) [0|3] "" GTW,DAS
 SG_ RCM_ndFrontCollision : 7|2@0+ (1,0) [0|3] "" GTW,DAS
 SG_ RCM_crashAlgoWakeup : 9|2@0+ (1,0) [0|3] "" GTW,APP,APS
 SG_ RCM_ndChargerCollision : 11|2@0+ (1,0) [0|3] "" GTW,APP,APS
 SG_ RCM_ndPedProEvent : 13|2@0+ (1,0) [0|3] "" GTW,DAS
 SG_ RCM_ndRollOverCollision : 15|2@0+ (1,0) [0|3] "" GTW,DAS
 SG_ RCM_nearDeployCounter : 55|4@0+ (1,0) [0|15] "" GTW
 SG_ RCM_nearDeployChecksum : 63|8@0+ (1,0) [0|255] "" GTW

BO_ 529 RCM_status: 8 RCM
 SG_ RCM_driverOrientationInitStatus : 2|3@0+ (1,0) [0|7] "" GTW,OCS
 SG_ RCM_armStatus : 5|2@0+ (1,0) [0|3] "" GTW,OCS
 SG_ RCM_warningIndicatorState : 7|2@0+ (1,0) [0|3] "" GTW,OCS
 SG_ RCM_tellTalePassengerState : 9|2@0+ (1,0) [0|3] "" GTW,OCS,DAS
 SG_ RCM_bucklePassengerStatus : 11|2@0+ (1,0) [0|3] "" GTW,OCS,APP
 SG_ RCM_tellTaleDriverState : 13|2@0+ (1,0) [0|3] "" GTW,OCS
 SG_ RCM_buckleDriverStatus : 15|2@0+ (1,0) [0|3] "" GTW,OCS,DAS
 SG_ RCM_seatTrackPositionPass : 17|2@0+ (1,0) [0|3] "" GTW,OCS
 SG_ RCM_seatTrackPositionDrvr : 19|2@0+ (1,0) [0|3] "" GTW,OCS
 SG_ RCM_passAirbagRequest : 21|2@0+ (1,0) [0|3] "" GTW,OCS
 SG_ RCM_chimeState1stRow : 23|2@0+ (1,0) [0|3] "" GTW,OCS
 SG_ RCM_vinLearnFlag : 25|2@0+ (1,0) [0|3] "" GTW,OCS
 SG_ RCM_hwConfigPin58 : 27|2@0+ (1,0) [0|3] "" GTW,OCS
 SG_ RCM_hwConfigPin57 : 29|2@0+ (1,0) [0|3] "" GTW,OCS
 SG_ RCM_hwConfigPin56 : 31|2@0+ (1,0) [0|3] "" GTW,OCS
 SG_ RCM_passOccupantStatus : 33|2@0+ (1,0) [0|3] "" GTW,OCS,APP
 SG_ RCM_airbagCutoffSwStatus : 35|2@0+ (1,0) [0|3] "" GTW,OCS
 SG_ RCM_privateCANStatus : 37|2@0+ (1,0) [0|3] "" GTW,OCS
 SG_ RCM_publicCANStatus : 39|2@0+ (1,0) [0|3] "" GTW,OCS
 SG_ RCM_pedProEDR2State : 41|2@0+ (1,0) [0|3] "" GTW,OCS
 SG_ RCM_pedProEDR1State : 43|2@0+ (1,0) [0|3] "" GTW,OCS
 SG_ RCM_edr2State : 45|2@0+ (1,0) [0|3] "" GTW,OCS
 SG_ RCM_edr1State : 47|2@0+ (1,0) [0|3] "" GTW,OCS
 SG_ RCM_buckle2ndRowStatus : 50|3@0+ (1,0) [0|3] "" GTW,OCS,DAS
 SG_ RCM_statusCounter : 55|4@0+ (1,0) [0|15] "" GTW,OCS,DAS
 SG_ RCM_statusChecksum : 63|8@0+ (1,0) [0|255] "" GTW,OCS,DAS

BO_ 2041 RCM_udsDisposalResponse: 8 RCM
 SG_ RCM_udsDisposalResponseData : 7|64@0+ (1,0) [0|0] "" GTW

BO_ 1617 RCM_udsResponse: 8 RCM
 SG_ RCM_udsResponseData : 7|64@0+ (1,0) [0|0] "" GTW,GTWU

BO_ 1538 RT3000_Altitude: 4 RT3000
 SG_ RT3000_PosAlt : 0|32@1- (0.001,0) [-2147483.648|2147483.647] "m" APP

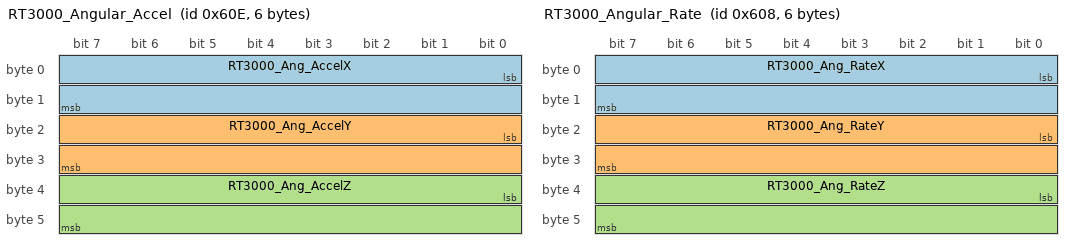
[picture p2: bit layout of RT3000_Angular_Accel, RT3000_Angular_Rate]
BO_ 1550 RT3000_Angular_Accel: 6 RT3000
 SG_ RT3000_Ang_AccelX : 0|16@1- (0.01,0) [-327.68|327.67] "deg/s/s" APP
 SG_ RT3000_Ang_AccelY : 16|16@1- (0.01,0) [-327.68|327.67] "deg/s/s" APP
 SG_ RT3000_Ang_AccelZ : 32|16@1- (0.01,0) [-327.68|327.67] "deg/s/s" APP

BO_ 1544 RT3000_Angular_Rate: 6 RT3000
 SG_ RT3000_Ang_RateX : 0|16@1- (0.01,0) [-327.68|327.67] "deg/s" APP
 SG_ RT3000_Ang_RateY : 16|16@1- (0.01,0) [-327.68|327.67] "deg/s" APP
 SG_ RT3000_Ang_RateZ : 32|16@1- (0.01,0) [-327.68|327.67] "deg/s" APP

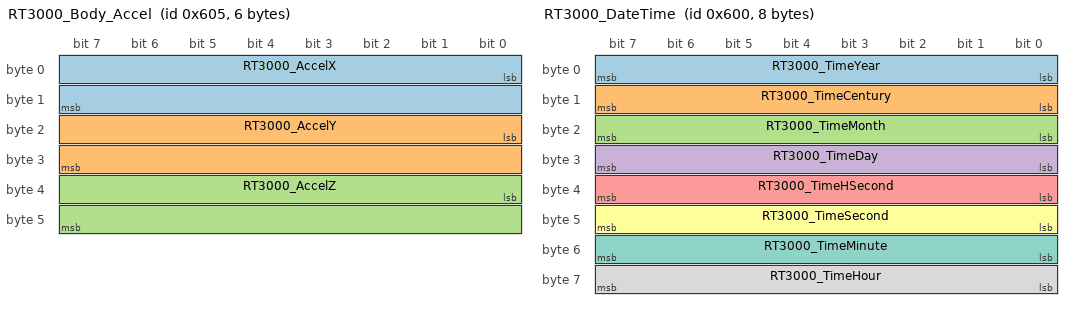
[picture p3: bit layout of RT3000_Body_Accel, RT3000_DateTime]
BO_ 1541 RT3000_Body_Accel: 6 RT3000
 SG_ RT3000_AccelX : 0|16@1- (0.01,0) [-327.68|327.67] "m/s/s" APP
 SG_ RT3000_AccelY : 16|16@1- (0.01,0) [-327.68|327.67] "m/s/s" APP
 SG_ RT3000_AccelZ : 32|16@1- (0.01,0) [-327.68|327.67] "m/s/s" APP

BO_ 1536 RT3000_DateTime: 8 RT3000
 SG_ RT3000_TimeYear : 0|8@1+ (1,0) [0|100] "" APP
 SG_ RT3000_TimeCentury : 8|8@1+ (1,0) [0|100] "" APP
 SG_ RT3000_TimeMonth : 16|8@1+ (1,0) [1|12] "" APP
 SG_ RT3000_TimeDay : 24|8@1+ (1,0) [1|31] "" APP
 SG_ RT3000_TimeHSecond : 32|8@1+ (0.01,0) [0|1] "" APP
 SG_ RT3000_TimeSecond : 40|8@1+ (1,0) [0|60] "" APP
 SG_ RT3000_TimeMinute : 48|8@1+ (1,0) [0|60] "" APP
 SG_ RT3000_TimeHour : 56|8@1+ (1,0) [0|24] "" APP

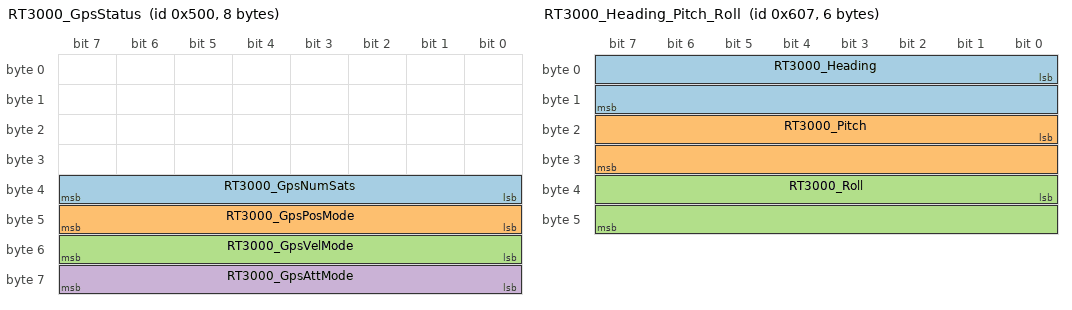
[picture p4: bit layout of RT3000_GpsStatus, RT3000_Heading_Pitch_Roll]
BO_ 1280 RT3000_GpsStatus: 8 RT3000
 SG_ RT3000_GpsNumSats : 32|8@1+ (1,0) [0|0] "" APP
 SG_ RT3000_GpsPosMode : 40|8@1+ (1,0) [0|0] "" APP
 SG_ RT3000_GpsVelMode : 48|8@1+ (1,0) [0|0] "" APP
 SG_ RT3000_GpsAttMode : 56|8@1+ (1,0) [0|0] "" APP

BO_ 1543 RT3000_Heading_Pitch_Roll: 6 RT3000
 SG_ RT3000_Heading : 0|16@1+ (0.01,0) [0|655.35] "deg" APP
 SG_ RT3000_Pitch : 16|16@1- (0.01,0) [-327.68|327.67] "deg" APP
 SG_ RT3000_Roll : 32|16@1- (0.01,0) [-327.68|327.67] "deg" APP

BO_ 1537 RT3000_Latitude_Longitude: 8 RT3000
 SG_ RT3000_PosLat : 0|32@1- (1E-07,0) [-214.7483648|214.7483647] "" APP
 SG_ RT3000_PosLon : 32|32@1- (1E-07,0) [-214.7483648|214.7483647] "" APP

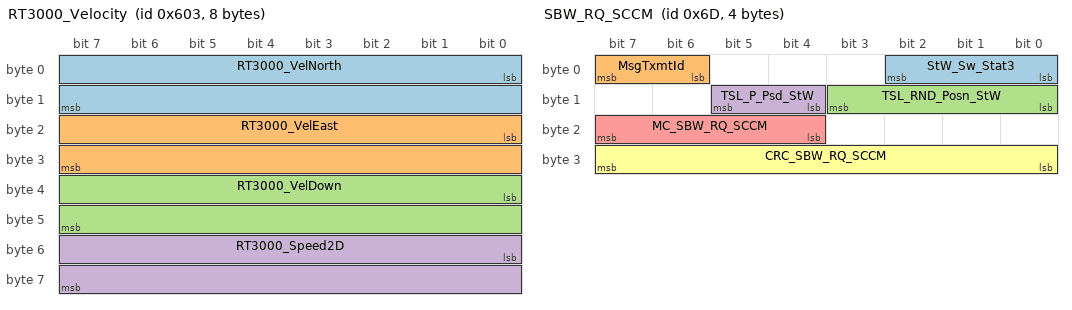
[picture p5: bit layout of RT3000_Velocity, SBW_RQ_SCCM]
BO_ 1539 RT3000_Velocity: 8 RT3000
 SG_ RT3000_VelNorth : 0|16@1- (0.01,0) [-327.68|327.67] "m/s" APP
 SG_ RT3000_VelEast : 16|16@1- (0.01,0) [-327.68|327.67] "m/s" APP
 SG_ RT3000_VelDown : 32|16@1- (0.01,0) [-327.68|327.67] "m/s" APP
 SG_ RT3000_Speed2D : 48|16@1+ (0.01,0) [0|655.35] "m/s" APP

BO_ 109 SBW_RQ_SCCM: 4 SCCM
 SG_ StW_Sw_Stat3 : 0|3@1+ (1,0) [0|0] "" GTW
 SG_ MsgTxmtId : 6|2@1+ (1,0) [0|0] "" GTW
 SG_ TSL_RND_Posn_StW : 8|4@1+ (1,0) [0|0] "" GTW
 SG_ TSL_P_Psd_StW : 12|2@1+ (1,0) [0|0] "" SEC,GTW,EPB,EPBM,BCCEN,DAS
 SG_ MC_SBW_RQ_SCCM : 20|4@1+ (1,0) [0|15] "" SEC,GTW,EPB,EPBM
 SG_ CRC_SBW_RQ_SCCM : 24|8@1+ (1,0) [0|0] "" SEC,GTW,EPB,EPBM

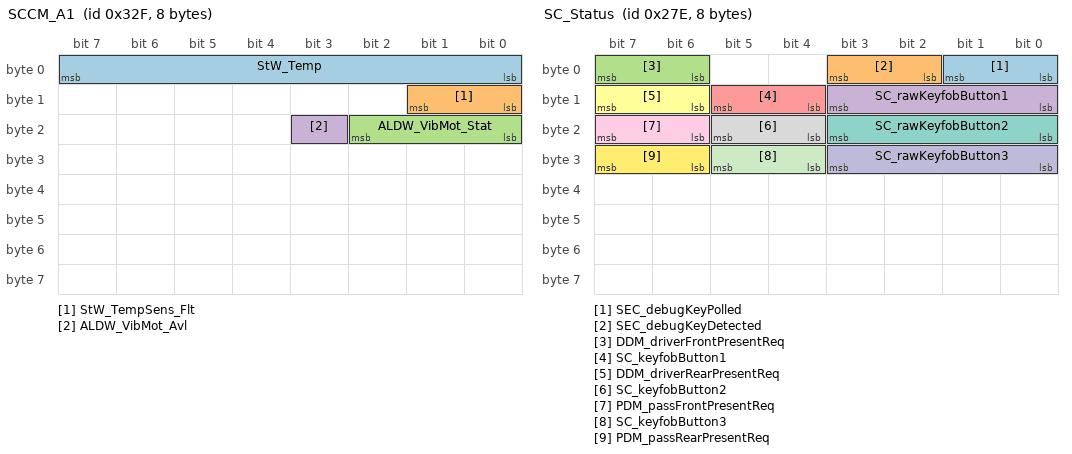
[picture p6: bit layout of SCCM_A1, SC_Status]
BO_ 815 SCCM_A1: 8 SCCM
 SG_ StW_Temp : 0|8@1+ (0.5,-40) [-40|85] "C" Vector__XXX
 SG_ StW_TempSens_Flt : 8|2@1+ (1,0) [0|0] "" Vector__XXX
 SG_ ALDW_VibMot_Stat : 16|3@1+ (1,0) [0|0] "" Vector__XXX
 SG_ ALDW_VibMot_Avl : 19|1@1+ (1,0) [0|0] "" Vector__XXX

BO_ 1944 SCCM_udsResponse: 8 SCCM
 SG_ SCCM_udsResponseData : 7|64@0+ (1,0) [0|0] "" GTW,GTWU

BO_ 638 SC_Status: 8 GTW
 SG_ SEC_debugKeyPolled : 1|2@0+ (1,0) [0|0] "" Vector__XXX
 SG_ SEC_debugKeyDetected : 3|2@0+ (1,0) [0|0] "" Vector__XXX
 SG_ DDM_driverFrontPresentReq : 7|2@0+ (1,0) [0|0] "" DAS
 SG_ SC_rawKeyfobButton1 : 11|4@0+ (1,0) [0|0] "" Vector__XXX
 SG_ SC_keyfobButton1 : 13|2@0+ (1,0) [0|3] "" DAS
 SG_ DDM_driverRearPresentReq : 15|2@0+ (1,0) [0|0] "" DAS
 SG_ SC_rawKeyfobButton2 : 19|4@0+ (1,0) [0|0] "" Vector__XXX
 SG_ SC_keyfobButton2 : 21|2@0+ (1,0) [0|3] "" DAS
 SG_ PDM_passFrontPresentReq : 23|2@0+ (1,0) [0|0] "" DAS
 SG_ SC_rawKeyfobButton3 : 27|4@0+ (1,0) [0|0] "" Vector__XXX
 SG_ SC_keyfobButton3 : 29|2@0+ (1,0) [0|3] "" DAS
 SG_ PDM_passRearPresentReq : 31|2@0+ (1,0) [0|0] "" DAS

CM_ BO_ 1944 "SG_APPL_SCCM2";
CM_ BO_ 638 "The button states from the keyfob. The raw signals are not populated.";
CM_ SG_ 1009 RCM2_a567_seaTrkPosLeftConfig "DTC value: 0x80B556";
CM_ SG_ 1009 RCM2_a568_occPROSSht2Gnd "DTC value: 0x80C511";
CM_ SG_ 1009 RCM2_a569_occPROSSht2Bat "DTC value: 0x80C512";
CM_ SG_ 1009 RCM2_a570_occPROSOpen "DTC value: 0x80C513";
CM_ SG_ 1009 RCM2_a571_occPROSUndef "DTC value: 0x80C51D";
CM_ SG_ 1009 RCM2_a572_occPROSCrssCoup "DTC value: 0x80C52B";
CM_ SG_ 1009 RCM2_a573_occPROSConfig "DTC value: 0x80C556";
CM_ SG_ 1009 RCM2_a587_sbrRearNetSht2Gnd "DTC value: 0x80DE11";
CM_ SG_ 1009 RCM2_a588_sbrRearNetSht2Bat "DTC value: 0x80DE12";
CM_ SG_ 1009 RCM2_a589_sbrRearNetOpen "DTC value: 0x80DE13";
CM_ SG_ 1009 RCM2_a590_sbrRearNetUndefined "DTC value: 0x80DE1D";
CM_ SG_ 1009 RCM2_a591_sbrRearNetCrssCoup "DTC value: 0x80DE2B";
CM_ SG_ 1009 RCM2_a592_sbrRearNetConfig "DTC value: 0x80DE56";
CM_ SG_ 1009 RCM2_a593_driveOrientaSht2Gnd "DTC value: 0x805411";
CM_ SG_ 1009 RCM2_a594_driveOrientaSht2Bat "DTC value: 0x805412";
CM_ SG_ 1009 RCM2_a595_driveOrientaOpen "DTC value: 0x805413";
CM_ SG_ 1009 RCM2_a596_driveOrientaUndefined "DTC value: 0x80541D";
CM_ SG_ 1009 RCM2_a597_driveOrientaCrssCoup "DTC value: 0x80542B";
CM_ SG_ 1009 RCM2_a598_driveOrientaConfig "DTC value: 0x805456";
CM_ SG_ 1009 RCM2_a600_comCANinternalTimeout "DTC value: 0xF00049";
CM_ SG_ 1009 RCM2_a601_comChassisCANInit "DTC value: 0xDA1400";
CM_ SG_ 1009 RCM2_a602_comChassisCANBusOff "DTC value: 0xC00188";
CM_ SG_ 1009 RCM2_a603_comPARTYCANInit "DTC value: 0xDA1500";
CM_ SG_ 1009 RCM2_a604_comPARTYCANBusOff "DTC value: 0xC00288";
CM_ SG_ 1009 RCM2_a605_comStwAngStatMIA "DTC value: 0xC00787";
CM_ SG_ 1009 RCM2_a606_comStwAngStatChkSm "DTC value: 0xC00770";
CM_ SG_ 1009 RCM2_a607_comStwAngStatCntr "DTC value: 0xC00769";
CM_ SG_ 1009 RCM2_a608_comDItorque1MIA "DTC value: 0xC00487";
CM_ SG_ 1009 RCM2_a609_comDItorque1ChkSm "DTC value: 0xC00470";
CM_ SG_ 1009 RCM2_a610_comDItorque1Cntr "DTC value: 0xC00469";
CM_ SG_ 1009 RCM2_a611_comDItorque2MIA "DTC value: 0xC00587";
CM_ SG_ 1009 RCM2_a612_comDItorque2ChkSm "DTC value: 0xC00570";
CM_ SG_ 1009 RCM2_a613_comDItorque2Cntr "DTC value: 0xC00569";
CM_ SG_ 1009 RCM2_a614_comESP135MIA "DTC value: 0xCA5B87";
CM_ SG_ 1009 RCM2_a615_comESP135ChkSm "DTC value: 0xCA5B70";
CM_ SG_ 1009 RCM2_a616_comESP135Cntr "DTC value: 0xCA5B69";
CM_ SG_ 1009 RCM2_a617_comESP145MIA "DTC value: 0xC00687";
CM_ SG_ 1009 RCM2_a618_comESP145ChkSm "DTC value: 0xC00670";
CM_ SG_ 1009 RCM2_a619_comESP145Cntr "DTC value: 0xC00669";
CM_ SG_ 1009 RCM2_a620_comInvalidVehicleSpeed "DTC value: 0xC00381";
CM_ SG_ 1009 RCM2_a621_comESPBMIA "DTC value: 0xC00387";
CM_ SG_ 1009 RCM2_a622_comESPBChkSm "DTC value: 0xC00370";
CM_ SG_ 1009 RCM2_a623_comESPBCntr "DTC value: 0xC00369";
CM_ SG_ 1009 RCM2_a624_comESPCMIA "DTC value: 0xCB5C87";
CM_ SG_ 1009 RCM2_a625_comESPCChkSm "DTC value: 0xCB5C70";
CM_ SG_ 1009 RCM2_a626_comESPCCntr "DTC value: 0xCB5C69";
CM_ SG_ 1009 RCM2_a627_comEPBStatusMIA "DTC value: 0xC95A87";
CM_ SG_ 1009 RCM2_a628_comEPBStatusChkSm "DTC value: 0xC95A70";
CM_ SG_ 1009 RCM2_a629_comEPBStatusCntr "DTC value: 0xC95A69";
CM_ SG_ 1009 RCM2_a630_comGTWACSMIA "DTC value: 0xC04500";
CM_ SG_ 1009 RCM2_a631_comGTWACSChkSm "DTC value: 0xC07870";
CM_ SG_ 1009 RCM2_a632_comGTWACSCntr "DTC value: 0xC07969";
CM_ SG_ 1009 RCM2_a633_comOCS1PMIA "DTC value: 0xC45587";
CM_ SG_ 1009 RCM2_a634_comOCS1PChkSm "DTC value: 0xC45570";
CM_ SG_ 1009 RCM2_a635_comOCS1PCntr "DTC value: 0xC45569";
CM_ SG_ 1009 RCM2_a636_ocsFaulted "DTC value: 0xC45593";
CM_ SG_ 1009 RCM2_a637_ocsUnknown "DTC value: 0xC45594";
CM_ SG_ 1009 RCM2_a638_comGTWodoMIA "DTC value: 0xC00287";
CM_ SG_ 1009 RCM2_a639_comGTWCarStateMIA "DTC value: 0x560787";
CM_ SG_ 1009 RCM2_a640_comTPMSStatusCMIA "DTC value: 0xC55687";
CM_ SG_ 1009 RCM2_a641_comGTWCarConfigMIA "DTC value: 0xCD5687";
CM_ SG_ 1009 RCM2_a642_comVINmessageMIA "DTC value: 0xCC5D87";
CM_ SG_ 1009 RCM2_a643_comDASSafetyFrntMIA "DTC value: 0xFE5C87";
CM_ SG_ 1009 RCM2_a644_comDASSafetyFrntChkSm "DTC value: 0xFE5C70";
CM_ SG_ 1009 RCM2_a645_comDASSafetyFrntCntr "DTC value: 0xFE5C69";
CM_ SG_ 1009 RCM2_a646_comDIstateMIA "DTC value: 0xFE5F87";
CM_ SG_ 1009 RCM2_a647_comDIstateChkSm "DTC value: 0xFE5F70";
CM_ SG_ 1009 RCM2_a648_comDIstateCntr "DTC value: 0xFE5F69";
CM_ SG_ 1009 RCM2_a649_comDIstate2MIA "DTC value: 0xFE6087";
CM_ SG_ 1009 RCM2_a650_comDIstate2ChkSm "DTC value: 0xFE6070";
CM_ SG_ 1009 RCM2_a651_comDIstate2Cntr "DTC value: 0xFE6069";
CM_ SG_ 1009 RCM2_a652_ambientTempFaulted "DTC value: 0xC04781";
CM_ SG_ 1009 RCM2_a653_comGTWESP1MIA "DTC value: 0xC04787";
CM_ SG_ 1009 RCM2_a654_comGTWESP1ChkSm "DTC value: 0xC04770";
CM_ SG_ 1009 RCM2_a655_comGTWESP1Cntr "DTC value: 0xC04769";
CM_ SG_ 1009 RCM2_a750_linInternalTimeout "DTC value: 0x80A049";
CM_ SG_ 1009 RCM2_a800_cfgMissingCalibration "DTC value: 0xE30054";
CM_ SG_ 1009 RCM2_a801_cfgImplausConfig "DTC value: 0xE30064";
CM_ SG_ 1009 RCM2_a802_cfgInvalidConfig "DTC value: 0xE30056";
CM_ SG_ 1009 RCM2_a803_cfgNotConfigured "DTC value: 0xE30055";
CM_ SG_ 1009 RCM2_a804_cfgNotProgrammed "DTC value: 0xE30051";
CM_ SG_ 1009 RCM2_a805_cfgPedProNotProgrammed "DTC value: 0xE30051";
CM_ SG_ 1009 RCM2_a806_cfgCrashCalPNmissing "DTC value: 0xE01A51";
CM_ SG_ 1009 RCM2_a807_cfgExternalCRCError "DTC value: 0xE20000";
CM_ SG_ 1009 RCM2_a808_cfgInvalParamLayoutID "DTC value: 0xF00057";
CM_ SG_ 1009 RCM2_a809_cfgInvalParamTransID "DTC value: 0xF00057";
CM_ SG_ 1009 RCM2_a810_cfgAlgoVerifySnsrID "DTC value: 0xF00057";
CM_ SG_ 1009 RCM2_a811_cfgConfigDataInconsist "DTC value: 0xF00056";
CM_ SG_ 1009 RCM2_a812_swVersionWrong "DTC value: 0xE20000";
CM_ SG_ 1009 RCM2_a813_vinNotProgrammed "DTC value: 0xF00251";
CM_ SG_ 1009 RCM2_a814_vinMismatch "DTC value: 0xF00295";
CM_ SG_ 1009 RCM2_a815_driveLeaningNotDone "DTC value: 0xF10351";
CM_ SG_ 1009 RCM2_a816_driveLeaningMismatch "DTC value: 0xF10395";
CM_ SG_ 1009 RCM2_a817_bootActionsFailed "DTC value: 0xE00002";
CM_ SG_ 1009 RCM2_a850_internalFault_001 "DTC value: 0xF00049";
CM_ SG_ 1009 RCM2_a851_internalFault_002 "DTC value: 0xF00049";
CM_ SG_ 1009 RCM2_a852_internalFault_003 "DTC value: 0xF00049";
CM_ SG_ 1009 RCM2_a853_internalFault_004 "DTC value: 0xF00049";
CM_ SG_ 1009 RCM2_a854_internalFault_005 "DTC value: 0xF00049";
CM_ SG_ 1009 RCM2_a855_internalFault_006 "DTC value: 0xF00049";
CM_ SG_ 1009 RCM2_a856_internalFault_007 "DTC value: 0xF00049";
CM_ SG_ 1009 RCM2_a857_internalFault_008 "DTC value: 0xF00049";
CM_ SG_ 1009 RCM2_a858_internalFault_009 "DTC value: 0xF00049";
CM_ SG_ 1009 RCM2_a859_internalFault_010 "DTC value: 0xF00049";
CM_ SG_ 1009 RCM2_a860_internalFault_011 "DTC value: 0xF00049";
CM_ SG_ 1009 RCM2_a861_internalFault_012 "DTC value: 0xF00049";
CM_ SG_ 1009 RCM2_a862_internalFault_013 "DTC value: 0xF00049";
CM_ SG_ 1009 RCM2_a863_internalFault_014 "DTC value: 0xF00049";
CM_ SG_ 1009 RCM2_a864_internalFault_015 "DTC value: 0xF00049";
CM_ SG_ 1009 RCM2_a865_internalFault_016 "DTC value: 0xF00049";
CM_ SG_ 1009 RCM2_a866_internalFault_017 "DTC value: 0xF00049";
CM_ SG_ 1009 RCM2_a867_internalFault_018 "DTC value: 0xF00049";
CM_ SG_ 1009 RCM2_a868_internalFault_019 "DTC value: 0xF00049";
CM_ SG_ 1009 RCM2_a869_internalFault_020 "DTC value: 0xF00049";
CM_ SG_ 1009 RCM2_a870_internalFault_021 "DTC value: 0xF00049";
CM_ SG_ 1009 RCM2_a871_internalFault_022 "DTC value: 0xF00049";
CM_ SG_ 1009 RCM2_a872_internalFault_023 "DTC value: 0xF00049";
CM_ SG_ 1009 RCM2_a873_internalFault_024 "DTC value: 0xF00049";
CM_ SG_ 1009 RCM2_a874_internalFault_025 "DTC value: 0xF00049";
CM_ SG_ 1009 RCM2_a875_internalFault_026 "DTC value: 0xF00049";
CM_ SG_ 1009 RCM2_a876_internalFault_027 "DTC value: 0xF00049";
CM_ SG_ 1009 RCM2_a877_internalFault_028 "DTC value: 0xF00049";
CM_ SG_ 1009 RCM2_a878_internalFault_029 "DTC value: 0xF00049";
CM_ SG_ 1009 RCM2_a879_internalFault_030 "DTC value: 0xF00049";
CM_ SG_ 1009 RCM2_a880_internalFault_031 "DTC value: 0xF00049";
CM_ SG_ 1009 RCM2_a881_internalFault_032 "DTC value: 0xF00049";
CM_ SG_ 1009 RCM2_a882_internalFault_033 "DTC value: 0xF00049";
CM_ SG_ 1009 RCM2_a883_internalFault_034 "DTC value: 0xF00049";
CM_ SG_ 1009 RCM2_a884_internalFault_035 "DTC value: 0xF00049";
CM_ SG_ 1009 RCM2_a885_internalFault_036 "DTC value: 0xF00049";
CM_ SG_ 1009 RCM2_a886_internalFault_037 "DTC value: 0xF00049";
CM_ SG_ 1009 RCM2_a887_internalFault_038 "DTC value: 0xF00049";
CM_ SG_ 1009 RCM2_a888_internalFault_039 "DTC value: 0xF00049";
CM_ SG_ 1009 RCM2_a889_internalFault_040 "DTC value: 0xF00049";
CM_ SG_ 1009 RCM2_a890_internalFault_041 "DTC value: 0xF00049";
CM_ SG_ 1009 RCM2_a891_internalFault_042 "DTC value: 0xF00049";
CM_ SG_ 1009 RCM2_a892_internalFault_043 "DTC value: 0xF00049";
CM_ SG_ 1009 RCM2_a893_internalFault_044 "DTC value: 0xF00049";
CM_ SG_ 1009 RCM2_a894_internalFault_045 "DTC value: 0xF00049";
CM_ SG_ 1009 RCM2_a895_internalFault_046 "DTC value: 0xF00049";
CM_ SG_ 1009 RCM2_a896_internalFault_047 "DTC value: 0xF00049";
CM_ SG_ 1009 RCM2_a897_internalFault_048 "DTC value: 0xF00049";
CM_ SG_ 1009 RCM2_a898_internalFault_049 "DTC value: 0xF00049";
CM_ SG_ 1009 RCM2_a899_internalFault_050 "DTC value: 0xF00049";
CM_ SG_ 1009 RCM2_a900_internalFault_051 "DTC value: 0xF00049";
CM_ SG_ 1009 RCM2_a901_internalFault_052 "DTC value: 0xF00049";
CM_ SG_ 1009 RCM2_a902_internalFault_053 "DTC value: 0xF00049";
CM_ SG_ 1009 RCM2_a903_internalFault_054 "DTC value: 0xF00049";
CM_ SG_ 1009 RCM2_a904_internalFault_055 "DTC value: 0xF00049";
CM_ SG_ 1009 RCM2_a905_internalFault_056 "DTC value: 0xF00049";
CM_ SG_ 1009 RCM2_a906_internalFault_057 "DTC value: 0xF00049";
CM_ SG_ 1009 RCM2_a907_internalFault_058 "DTC value: 0xF00049";
CM_ SG_ 1009 RCM2_a908_internalFault_059 "DTC value: 0xF00049";
CM_ SG_ 1009 RCM2_a909_internalFault_060 "DTC value: 0xF00049";
CM_ SG_ 1009 RCM2_a910_internalFault_061 "DTC value: 0xF00049";
CM_ SG_ 1009 RCM2_a911_internalFault_062 "DTC value: 0xF00049";
CM_ SG_ 1009 RCM2_a912_internalFault_063 "DTC value: 0xF00049";
CM_ SG_ 1009 RCM2_a913_internalFault_064 "DTC value: 0xF00049";
CM_ SG_ 1009 RCM2_a914_internalFault_065 "DTC value: 0xF00049";
CM_ SG_ 1009 RCM2_a915_internalFault_066 "DTC value: 0xF00049";
CM_ SG_ 1009 RCM2_a916_internalFault_067 "DTC value: 0xF00049";
CM_ SG_ 1009 RCM2_a917_internalFault_068 "DTC value: 0xF00049";
CM_ SG_ 1009 RCM2_a918_internalFault_069 "DTC value: 0xF00049";
CM_ SG_ 1009 RCM2_a919_internalFault_070 "DTC value: 0xF00049";
CM_ SG_ 1009 RCM2_a920_internalFault_071 "DTC value: 0xF00049";
CM_ SG_ 1009 RCM2_a921_internalFault_072 "DTC value: 0xF00049";
CM_ SG_ 1009 RCM2_a922_internalFault_073 "DTC value: 0xF00049";
CM_ SG_ 1009 RCM2_a923_internalFault_074 "DTC value: 0xF00049";
CM_ SG_ 1009 RCM2_a924_internalFault_075 "DTC value: 0xF00049";
CM_ SG_ 1009 RCM2_a925_internalFault_076 "DTC value: 0xF00049";
CM_ SG_ 1009 RCM2_a926_internalFault_077 "DTC value: 0xF00049";
CM_ SG_ 1009 RCM2_a927_internalFault_078 "DTC value: 0xF00049";
CM_ SG_ 1009 RCM2_a928_internalFault_079 "DTC value: 0xF00049";
CM_ SG_ 1009 RCM2_a929_internalFault_080 "DTC value: 0xF00049";
CM_ SG_ 1009 RCM2_a930_internalFault_081 "DTC value: 0xF00049";
CM_ SG_ 1009 RCM2_a931_internalFault_082 "DTC value: 0xF00049";
CM_ SG_ 1009 RCM2_a932_internalFault_083 "DTC value: 0xF00049";
CM_ SG_ 1009 RCM2_a933_internalFault_084 "DTC value: 0xF00049";
CM_ SG_ 1009 RCM2_a934_internalFault_085 "DTC value: 0xF00049";
CM_ SG_ 1009 RCM2_a935_internalFault_086 "DTC value: 0xF00049";
CM_ SG_ 1009 RCM2_a936_internalFault_087 "DTC value: 0xF00049";
CM_ SG_ 1009 RCM2_a937_internalFault_088 "DTC value: 0xF00049";
CM_ SG_ 1009 RCM2_a938_internalFault_089 "DTC value: 0xF00049";
CM_ SG_ 1009 RCM2_a939_internalFault_090 "DTC value: 0xF00049";
CM_ SG_ 1009 RCM2_a940_internalFault_091 "DTC value: 0xF00049";
CM_ SG_ 1009 RCM2_a941_internalFault_092 "DTC value: 0xF00049";
CM_ SG_ 1009 RCM2_a942_internalFault_093 "DTC value: 0xF00049";
CM_ SG_ 1009 RCM2_a943_internalFault_094 "DTC value: 0xF00049";
CM_ SG_ 1009 RCM2_a944_internalFault_095 "DTC value: 0xF00049";
CM_ SG_ 1009 RCM2_a945_internalFault_096 "DTC value: 0xF00049";
CM_ SG_ 1009 RCM2_a946_internalFault_097 "DTC value: 0xF00049";
CM_ SG_ 1009 RCM2_a947_internalFault_098 "DTC value: 0xF00049";
CM_ SG_ 1009 RCM2_a948_internalFault_099 "DTC value: 0xF00049";
CM_ SG_ 1009 RCM2_a949_internalFault_100 "DTC value: 0xF00049";
CM_ SG_ 1009 RCM2_a950_internalFault_101 "DTC value: 0xF00049";
CM_ SG_ 1009 RCM2_a951_internalFault_102 "DTC value: 0xF00049";
CM_ SG_ 1009 RCM2_a952_internalFault_103 "DTC value: 0xF00049";
CM_ SG_ 1009 RCM2_a953_internalFault_104 "DTC value: 0xF00049";
CM_ SG_ 1009 RCM2_a954_internalFault_105 "DTC value: 0xF00049";
CM_ SG_ 1009 RCM2_a955_internalFault_106 "DTC value: 0xF00049";
CM_ SG_ 1009 RCM2_a956_internalFault_107 "DTC value: 0xF00049";
CM_ SG_ 1009 RCM2_a957_internalFault_108 "DTC value: 0xF00049";
CM_ SG_ 1009 RCM2_a958_internalFault_109 "DTC value: 0xF00049";
CM_ SG_ 1009 RCM2_a959_internalFault_110 "DTC value: 0xF00049";
CM_ SG_ 1009 RCM2_a960_internalFault_111 "DTC value: 0xF00049";
CM_ SG_ 1009 RCM2_a961_internalFault_112 "DTC value: 0xF00049";
CM_ SG_ 1009 RCM2_a962_internalFault_113 "DTC value: 0xF00049";
CM_ SG_ 1009 RCM2_a963_internalFault_114 "DTC value: 0xF00049";
CM_ SG_ 1009 RCM2_a964_internalFault_115 "DTC value: 0xF00049";
CM_ SG_ 1009 RCM2_a965_internalFault_116 "DTC value: 0xF00049";
CM_ SG_ 1009 RCM2_a966_internalFault_117 "DTC value: 0xF00049";
CM_ SG_ 1009 RCM2_a967_internalFault_118 "DTC value: 0xF00049";
CM_ SG_ 1009 RCM2_a968_internalFault_119 "DTC value: 0xF00049";
CM_ SG_ 1009 RCM2_a969_internalFault_120 "DTC value: 0xF00049";
CM_ SG_ 1009 RCM2_a970_internalFault_121 "DTC value: 0xF00049";
CM_ SG_ 1009 RCM2_a971_internalFault_122 "DTC value: 0xF00049";
CM_ SG_ 1009 RCM2_a972_internalFault_123 "DTC value: 0xF00049";
CM_ SG_ 1009 RCM2_a973_internalFault_124 "DTC value: 0xF00049";
CM_ SG_ 1009 RCM2_a974_internalFault_125 "DTC value: 0xF00049";
CM_ SG_ 1009 RCM2_a975_internalFault_126 "DTC value: 0xF00049";
CM_ SG_ 1009 RCM2_a976_internalFault_127 "DTC value: 0xF00049";
CM_ SG_ 1009 RCM2_a977_internalFault_128 "DTC value: 0xF00049";
CM_ SG_ 1009 RCM2_a978_internalFault_129 "DTC value: 0xF00049";
CM_ SG_ 1009 RCM2_a979_internalFault_130 "DTC value: 0xF00049";
CM_ SG_ 1009 RCM2_a980_internalFault_131 "DTC value: 0xF00049";
CM_ SG_ 1009 RCM2_a981_internalFault_132 "DTC value: 0xF00049";
CM_ SG_ 1009 RCM2_a982_internalFault_133 "DTC value: 0xF00049";
CM_ SG_ 1009 RCM2_a983_internalFault_134 "DTC value: 0xF00049";
CM_ SG_ 1009 RCM2_a984_internalFault_135 "DTC value: 0xF00049";
CM_ SG_ 1009 RCM2_a985_internalFault_136 "DTC value: 0xF00049";
CM_ SG_ 1009 RCM2_a986_internalFault_137 "DTC value: 0xF00049";
CM_ SG_ 1009 RCM2_a987_internalFault_138 "DTC value: 0xF00049";
CM_ SG_ 1009 RCM2_a988_internalFault_139 "DTC value: 0xF00049";
CM_ SG_ 1009 RCM2_a989_internalFault_140 "DTC value: 0xF00049";
CM_ SG_ 1009 RCM2_a990_internalFault_141 "DTC value: 0xF00049";
CM_ SG_ 1009 RCM2_a991_internalFault_142 "DTC value: 0xF00049";
CM_ SG_ 1009 RCM2_a992_internalFault_143 "DTC value: 0xF00049";
CM_ SG_ 1009 RCM2_a993_internalFault_144 "DTC value: 0xF00049";
CM_ SG_ 1009 RCM2_a994_internalFault_145 "DTC value: 0xF00049";
CM_ SG_ 17 RCM_collisionChecksum "Message checksum for RCM_collision message: Sum of all bytes in message (Unused fields are set to 0) + 0x17.";
CM_ SG_ 881 RCM_d000_comFault1 "Bosch DTC value: 0x00ffffxx";
CM_ SG_ 881 RCM_d001_vBatRange "Bosch DTC value: 0x00f003xx";
CM_ SG_ 881 RCM_d002_vinMismatch "Bosch DTC value: 0x00f002xx";
CM_ SG_ 881 RCM_d003_swVersionMismatch "Bosch DTC value: 0x00f000xx";
CM_ SG_ 881 RCM_d004_idleMode "Bosch DTC value: 0x00f000xx";
CM_ SG_ 881 RCM_d005_internalHard "Bosch DTC value: 0x00f000xx";
CM_ SG_ 881 RCM_d006_crashAlgoDisabled "Bosch DTC value: 0x00f000xx";
CM_ SG_ 881 RCM_d007_eolProgMismatch "Bosch DTC value: 0x00e300xx";
CM_ SG_ 881 RCM_d008_crcErrorExternal "Bosch DTC value: 0x00e200xx";
CM_ SG_ 881 RCM_d009_cfgFault "Bosch DTC value: 0x00e100xx";
CM_ SG_ 881 RCM_d010_crashCalPNMissing "Bosch DTC value: 0x00e01axx";
CM_ SG_ 881 RCM_d011_vdsFieldCalibFailed "Bosch DTC value: 0x00e008xx";
CM_ SG_ 881 RCM_d012_vdsChannelSigMonTmp "Bosch DTC value: 0x00e008xx";
CM_ SG_ 881 RCM_d013_vdsFieldCalibNotDone "Bosch DTC value: 0x00e008xx";
CM_ SG_ 881 RCM_d014_vdsChannelSigMonPerm "Bosch DTC value: 0x00e008xx";
CM_ SG_ 881 RCM_d015_vdsSensorMonitorTemp "Bosch DTC value: 0x00e008xx";
CM_ SG_ 881 RCM_d016_comCANInitFailure "Bosch DTC value: 0x00da14xx";
CM_ SG_ 881 RCM_d017_comGTWCarConfig "Bosch DTC value: 0x00cd56xx";
CM_ SG_ 881 RCM_d018_vinEmptyError "Bosch DTC value: 0x00cc5dxx";
CM_ SG_ 881 RCM_d019_comESPC "Bosch DTC value: 0x00cb5cxx";
CM_ SG_ 881 RCM_d020_comESP135 "Bosch DTC value: 0x00ca5bxx";
CM_ SG_ 881 RCM_d021_comEPBStatus "Bosch DTC value: 0x00c95axx";
CM_ SG_ 881 RCM_d022_comBCS2RStatus "Bosch DTC value: 0x00c859xx";
CM_ SG_ 881 RCM_d023_comBCS2LStatus "Bosch DTC value: 0x00c758xx";
CM_ SG_ 881 RCM_d024_comBCS2CStatus "Bosch DTC value: 0x00c657xx";
CM_ SG_ 881 RCM_d025_comTPMSStatus "Bosch DTC value: 0x00c556xx";
CM_ SG_ 881 RCM_d026_airbagWarnMismatch "Bosch DTC value: 0x00c456xx";
CM_ SG_ 881 RCM_d027_ocsFailure "Bosch DTC value: 0x00c455xx";
CM_ SG_ 881 RCM_d028_comGTWACS "Bosch DTC value: 0x00c079xx";
CM_ SG_ 881 RCM_d029_comChassisBusOff "Bosch DTC value: 0x00c028xx";
CM_ SG_ 881 RCM_d030_comStwAngle "Bosch DTC value: 0x00c007xx";
CM_ SG_ 881 RCM_d031_comESP145 "Bosch DTC value: 0x00c006xx";
CM_ SG_ 881 RCM_d032_comDITorque2 "Bosch DTC value: 0x00c005xx";
CM_ SG_ 881 RCM_d033_comDITorque1 "Bosch DTC value: 0x00c004xx";
CM_ SG_ 881 RCM_d034_comESPB "Bosch DTC value: 0x00c003xx";
CM_ SG_ 881 RCM_d035_comGTWOdo "Bosch DTC value: 0x00c002xx";
CM_ SG_ 881 RCM_d036_comBusOff "Bosch DTC value: 0x00c001xx";
CM_ SG_ 881 RCM_d037_comMissingVehConfg "Bosch DTC value: 0x00c001xx";
CM_ SG_ 881 RCM_d038_seatBackSw2ndRowLeft "Bosch DTC value: 0x009d75xx";
CM_ SG_ 881 RCM_d039_pretenLapFrontRight "Bosch DTC value: 0x009409xx";
CM_ SG_ 881 RCM_d040_pretenLapFrontLeft "Bosch DTC value: 0x009408xx";
CM_ SG_ 881 RCM_d041_pretenShldFrontRight "Bosch DTC value: 0x009214xx";
CM_ SG_ 881 RCM_d042_pretenShldrFrontLeft "Bosch DTC value: 0x009211xx";
CM_ SG_ 881 RCM_d043_passABLampOnHardWire "Bosch DTC value: 0x009202xx";
CM_ SG_ 881 RCM_d044_pedProCrashDetected "Bosch DTC value: 0x0091d8xx";
CM_ SG_ 881 RCM_d045_crashOutSignal "Bosch DTC value: 0x0091d8xx";
CM_ SG_ 881 RCM_d046_passengerActiveVent "Bosch DTC value: 0x0091cfxx";
CM_ SG_ 881 RCM_d047_kneeABFrontPassenger "Bosch DTC value: 0x0091cdxx";
CM_ SG_ 881 RCM_d048_pressureFrontRtDoor "Bosch DTC value: 0x0091a1xx";
CM_ SG_ 881 RCM_d049_pressureFrontLftDoor "Bosch DTC value: 0x0091a0xx";
CM_ SG_ 881 RCM_d050_eepromDataLocked "Bosch DTC value: 0x009193xx";
CM_ SG_ 881 RCM_d051_hoodActuatorLeft "Bosch DTC value: 0x009003xx";
CM_ SG_ 881 RCM_d052_hoodActuatorRight "Bosch DTC value: 0x009001xx";
CM_ SG_ 881 RCM_d053_sbsw2ndRowRight "Bosch DTC value: 0x0080dfxx";
CM_ SG_ 881 RCM_d054_padLampHardWire "Bosch DTC value: 0x0080d5xx";
CM_ SG_ 881 RCM_d055_passResOccupancySw "Bosch DTC value: 0x0080C5xx";
CM_ SG_ 881 RCM_d056_stpsDriver "Bosch DTC value: 0x0080b5xx";
CM_ SG_ 881 RCM_d057_pasDPillarLeftYAxis "Bosch DTC value: 0x0080a0xx";
CM_ SG_ 881 RCM_d058_pasDPillarLeftXAxis "Bosch DTC value: 0x008099xx";
CM_ SG_ 881 RCM_d059_pasDPillarRight "Bosch DTC value: 0x008098xx";
CM_ SG_ 881 RCM_d060_pasCPillarRight "Bosch DTC value: 0x008097xx";
CM_ SG_ 881 RCM_d061_pasBPillarRight "Bosch DTC value: 0x008096xx";
CM_ SG_ 881 RCM_d062_ufsRightSide "Bosch DTC value: 0x008095xx";
CM_ SG_ 881 RCM_d063_pasCPillarLeft "Bosch DTC value: 0x008092xx";
CM_ SG_ 881 RCM_d064_pasBPillarLeft "Bosch DTC value: 0x008091xx";
CM_ SG_ 881 RCM_d065_ufsLeftSide "Bosch DTC value: 0x008090xx";
CM_ SG_ 881 RCM_d066_loadLimiterRightSide "Bosch DTC value: 0x008082xx";
CM_ SG_ 881 RCM_d067_loadLimiterLeftSide "Bosch DTC value: 0x008080xx";
CM_ SG_ 881 RCM_d068_curAB3rdRowRight "Bosch DTC value: 0x008079xx";
CM_ SG_ 881 RCM_d069_curAB2ndRowRight "Bosch DTC value: 0x008078xx";
CM_ SG_ 881 RCM_d070_curAB2ndRowLeft "Bosch DTC value: 0x008076xx";
CM_ SG_ 881 RCM_d071_preten2ndRowRight "Bosch DTC value: 0x008075xx";
CM_ SG_ 881 RCM_d072_curAB3rdRowLeft "Bosch DTC value: 0x008074xx";
CM_ SG_ 881 RCM_d073_preten2ndRowLeft "Bosch DTC value: 0x008073xx";
CM_ SG_ 881 RCM_d074_siAB2ndRowRight "Bosch DTC value: 0x008072xx";
CM_ SG_ 881 RCM_d075_siAB2ndRowLeft "Bosch DTC value: 0x008071xx";
CM_ SG_ 881 RCM_d076_hardwarCodingPin3 "Bosch DTC value: 0x008055xx";
CM_ SG_ 881 RCM_d077_hardwareCodingPin2 "Bosch DTC value: 0x008054xx";
CM_ SG_ 881 RCM_d078_hardwareCodingPin1 "Bosch DTC value: 0x008053xx";
CM_ SG_ 881 RCM_d079_buckleRightSide "Bosch DTC value: 0x008052xx";
CM_ SG_ 881 RCM_d080_buckleLeftSide "Bosch DTC value: 0x008050xx";
CM_ SG_ 881 RCM_d081_curAB1stRowRight "Bosch DTC value: 0x008029xx";
CM_ SG_ 881 RCM_d082_siAB1stRowRight "Bosch DTC value: 0x008028xx";
CM_ SG_ 881 RCM_d083_curAB1stRowLeft "Bosch DTC value: 0x008021xx";
CM_ SG_ 881 RCM_d084_siAB1stRowLeft "Bosch DTC value: 0x008020xx";
CM_ SG_ 881 RCM_d085_pabStage2 "Bosch DTC value: 0x008011xx";
CM_ SG_ 881 RCM_d086_pabStage1 "Bosch DTC value: 0x008010xx";
CM_ SG_ 881 RCM_d087_hvDisconnect "Bosch DTC value: 0x008005xx";
CM_ SG_ 881 RCM_d088_kneeABDriver "Bosch DTC value: 0x008004xx";
CM_ SG_ 881 RCM_d089_dabStage2 "Bosch DTC value: 0x008002xx";
CM_ SG_ 881 RCM_d090_dabStage1 "Bosch DTC value: 0x008001xx";
CM_ SG_ 881 RCM_d091_comGTWCarState "Bosch DTC value: 0x005607xx";
CM_ SG_ 881 RCM_d092_driverOrientation "Bosch DTC value: 0x00f103xx";
CM_ SG_ 881 RCM_d093_scmUnavailable "Bosch DTC value: 0x00f104xx";
CM_ SG_ 881 RCM_d094_comGTWESP1 "Bosch DTC value: 0x00c047xx";
CM_ SG_ 881 RCM_d095_comDasIDF "Bosch DTC value: 0x00fe5cxx";
CM_ SG_ 881 RCM_d096_comDasStatus "Bosch DTC value: 0x00fe5exx";
CM_ SG_ 881 RCM_d097_comDIState "Bosch DTC value: 0x00fe5fxx";
CM_ SG_ 881 RCM_d098_comDIState2 "Bosch DTC value: 0x00fe60xx";
CM_ SG_ 881 RCM_d099_pedProPTSL "Bosch DTC value: 0x009005xx";
CM_ SG_ 881 RCM_d100_pedProPTSR "Bosch DTC value: 0x009004xx";
CM_ SG_ 881 RCM_d101_comVCSEATPrest "Bosch DTC value: 0x00c100xx";
CM_ SG_ 881 RCM_d102_comVCSEATDrest "Bosch DTC value: 0x00c101xx";
CM_ SG_ 881 RCM_d103_crashDetected "RCM_d103_crashDetected";
CM_ SG_ 881 RCM_d104_nearDeploy "RCM_d104_nearDeploy";
CM_ SG_ 881 RCM_d105_airbagsNotArmed "RCM_d105_airbagsNotArmed";
CM_ SG_ 881 RCM_d106_warningIndicator "RCM_d106_warningIndicator";
CM_ SG_ 881 RCM_d107_pedProCrashDetected "RCM_d107_pedProCrashDetected";
CM_ SG_ 881 RCM_d108_pedProNearDeploy "RCM_d108_pedProNearDeploy";
CM_ SG_ 881 RCM_d109_abuseImmunity "RCM_d109_abuseImmunity";
CM_ SG_ 881 RCM_d110_noDeployCrashCal "RCM_d110_noDeployCrashCal";
CM_ SG_ 881 RCM_d111_noDeployPedProCal "RCM_d111_noDeployPedProCal";
CM_ SG_ 545 RCM_inertial1Checksum "Message checksum for RCM_inertial1 message: Sum of all bytes in message (Unused fields are set to 0) + 0x23.";
CM_ SG_ 273 RCM_nearDeployChecksum "Message checksum for RCM_nearDeploy message: Sum of all bytes in message (Unused fields are set to 0) + 0x12.";
CM_ SG_ 529 RCM_statusChecksum "Message checksum for RCM_status message: Sum of all bytes in message (Unused fields are set to 0) + 0x13.";
CM_ SG_ 109 StW_Sw_Stat3 "State steering wheel switch ('+','-')";
CM_ SG_ 109 MsgTxmtId "Message transmitter identification";
CM_ SG_ 109 TSL_RND_Posn_StW "Indicates transmission selector lever RND position (steering wheel).";
CM_ SG_ 109 TSL_P_Psd_StW "Indicates when transmission selector lever 'P' switch is selected (steering wheel).";
CM_ SG_ 109 MC_SBW_RQ_SCCM "Message counter";
CM_ SG_ 109 CRC_SBW_RQ_SCCM "CRC-checksum byte 1 to 3 according to SAE J1850";
CM_ SG_ 815 StW_Temp "Steering wheel temperature";
CM_ SG_ 815 StW_TempSens_Flt "Steering wheel temperature sensor fault";
CM_ SG_ 815 ALDW_VibMot_Stat "ALDW vibration motor state";
CM_ SG_ 815 ALDW_VibMot_Avl "ALDW vibration motor available";
CM_ SG_ 1944 SCCM_udsResponseData "ECU to external application";
CM_ SG_ 638 SC_keyfobButton1 "Center (lock) key fob button state, with 200ms of hystersis on falling edge.";
CM_ SG_ 638 SC_keyfobButton2 "Rear (trunk) key fob button state, with 200ms of hystersis on falling edge.";
CM_ SG_ 638 SC_keyfobButton3 "Front (frunk) key fob button state, with 200ms of hystersis on falling edge.";
BA_DEF_ BO_ "AlertLogSubSystemId" INT 0 0;
BA_DEF_ BO_ "AlertType" INT 0 4;
BA_DEF_ BO_ "AppBotschaft" ENUM "nein","ja";
BA_DEF_ BO_ "DiagRequest" ENUM "No","Yes";
BA_DEF_ BO_ "DiagResponse" ENUM "No","Yes";
BA_DEF_ BO_ "ETHGatewayMessageSendType" ENUM "UseGenMsgSendType","onWrite","noAutoCode";
BA_DEF_ BO_ "ETHId" STRING ;
BA_DEF_ BO_ "GatewayHandlerEnum" ENUM "noHandler","uds","alertLog","messageLogOnReception","udsClient";
BA_DEF_ BO_ "GatewayMessageAtomic" ENUM "No","Yes";
BA_DEF_ BO_ "GatewayMessageSendType" ENUM "UseGenMsgSendType","onWrite","noAutoCode";
BA_DEF_ BO_ "GenMsgCycleTime" INT 0 0;
BA_DEF_ BO_ "GenMsgCycleTimeFast" INT 0 0;
BA_DEF_ BO_ "GenMsgDelayTime" INT 0 0;
BA_DEF_ BO_ "GenMsgForceMiaCheck" ENUM "No","Yes";
BA_DEF_ BO_ "GenMsgGatewayNotification" STRING ;
BA_DEF_ BO_ "GenMsgILSupport" ENUM "No","Yes";
BA_DEF_ BO_ "GenMsgSaltingFunction" ENUM "No","Yes";
BA_DEF_ BO_ "GenMsgSendType" ENUM "Cyclic","NotUsed","NotUsed","NotUsed","NotUsed","NotUsed","NotUsed","IfActive","NoMsgSendType","Sporadic";
BA_DEF_ BO_ "GenMsgStartValue" STRING ;
BA_DEF_ BO_ "GenMsgTimeOut" INT 0 0;
BA_DEF_ BO_ "MessageIdType" ENUM "normal","udsRequest","udsResponse","udsReserved","udsFunctionalRequest","networkManagement","bootloader","xcp","dtc","diagnostic","vendorExempt";
BA_DEF_ BO_ "NWMBotschaft" ENUM "nein","ja";
BA_DEF_ BO_ "NmMessage" ENUM "No","Yes";
BA_DEF_ BO_ "SubSystemId" INT 0 256;
BA_DEF_ BO_ "UsesChecksum" ENUM "No","Yes";
BA_DEF_ SG_ "FieldType" STRING ;
BA_DEF_ SG_ "FlexKomComment" STRING ;
BA_DEF_ SG_ "FlexKomIsMotorola" ENUM "nein","ja";
BA_DEF_ SG_ "FlexKomSID" INT 0 2147483647;
BA_DEF_ SG_ "FlexKomSigLaenge" INT 0 64;
BA_DEF_ SG_ "FlexKomSigName" STRING ;
BA_DEF_ SG_ "FlexKomSigStartPos" INT 0 63;
BA_DEF_ SG_ "FlexKomSigStartValue" STRING ;
BA_DEF_ SG_ "Gatewaysignal" INT 0 1;
BA_DEF_ SG_ "GenSigCycleTime" INT 0 0;
BA_DEF_ SG_ "GenSigCycleTimeActive" INT 0 0;
BA_DEF_ SG_ "GenSigPersistent" ENUM "No","Yes";
BA_DEF_ SG_ "GenSigSNA" STRING ;
BA_DEF_ SG_ "GenSigSendType" ENUM "Cyclic","OnWrite","OnWriteWithRepetition","OnChange","OnChangeWithRepetition","IfActive","IfActiveWithRepetition","NoSigSendType","NotUsed","NotUsed","NotUsed","NotUsed","NotUsed";
BA_DEF_ SG_ "GenSigStartValue" INT 0 0;
BA_DEF_ SG_ "GenSigTimeout_CGW" INT 0 65535;
BA_DEF_ SG_ "GenSigTimeout_DRVU" INT 0 65535;
BA_DEF_ SG_ "GenSigTimeout_ECM" INT 0 65535;
BA_DEF_ SG_ "GenSigTimeout_EIS" INT 0 65535;
BA_DEF_ SG_ "GenSigTimeout_EPS" INT 0 65535;
BA_DEF_ SG_ "GenSigTimeout_ESP_ABR" INT 0 65535;
BA_DEF_ SG_ "GenSigTimeout_IC" INT 0 65535;
BA_DEF_ SG_ "GenSigTimeout_MPC" INT 0 65535;
BA_DEF_ SG_ "GenSigTimeout_NV" INT 0 65535;
BA_DEF_ SG_ "GenSigTimeout_ORC" INT 0 65535;
BA_DEF_ SG_ "GenSigTimeout_PTS" INT 0 65535;
BA_DEF_ SG_ "GenSigTimeout_RBTM_FL" INT 0 65535;
BA_DEF_ SG_ "GenSigTimeout_RBTM_FR" INT 0 65535;
BA_DEF_ SG_ "GenSigTimeout_RDU" INT 0 65535;
BA_DEF_ SG_ "GenSigTimeout_SCCM" INT 0 65535;
BA_DEF_ SG_ "GenSigTimeout_SPC" INT 0 65535;
BA_DEF_ SG_ "GenSigTimeout_TPM" INT 0 65535;
BA_DEF_ SG_ "LogSignal" STRING ;
BA_DEF_ SG_ "PektronUpdateBitType" ENUM "Not used","Has update bit","Is update bit";
BA_DEF_REL_ BU_SG_REL_ "GenSigTimeoutTime" INT 0 0;

BA_DEF_DEF_ "AlertLogSubSystemId" 0;
BA_DEF_DEF_ "AlertType" 4;
BA_DEF_DEF_ "AppBotschaft" "nein";
BA_DEF_DEF_ "DiagRequest" "No";
BA_DEF_DEF_ "DiagResponse" "No";
BA_DEF_DEF_ "ETHGatewayMessageSendType" "UseGenMsgSendType";
BA_DEF_DEF_ "ETHId" "";
BA_DEF_DEF_ "FieldType" "";
BA_DEF_DEF_ "FlexKomComment" "";
BA_DEF_DEF_ "FlexKomIsMotorola" "";
BA_DEF_DEF_ "FlexKomSID" 0;
BA_DEF_DEF_ "FlexKomSigLaenge" 0;
BA_DEF_DEF_ "FlexKomSigName" "";
BA_DEF_DEF_ "FlexKomSigStartPos" 0;
BA_DEF_DEF_ "FlexKomSigStartValue" "";
BA_DEF_DEF_ "GatewayHandlerEnum" "noHandler";
BA_DEF_DEF_ "GatewayMessageAtomic" "No";
BA_DEF_DEF_ "GatewayMessageSendType" "UseGenMsgSendType";
BA_DEF_DEF_ "Gatewaysignal" 0;
BA_DEF_DEF_ "GenMsgCycleTime" 0;
BA_DEF_DEF_ "GenMsgCycleTimeFast" 0;
BA_DEF_DEF_ "GenMsgDelayTime" 0;
BA_DEF_DEF_ "GenMsgForceMiaCheck" "No";
BA_DEF_DEF_ "GenMsgGatewayNotification" "";
BA_DEF_DEF_ "GenMsgILSupport" "Yes";
BA_DEF_DEF_ "GenMsgSaltingFunction" "No";
BA_DEF_DEF_ "GenMsgSendType" "Cyclic";
BA_DEF_DEF_ "GenMsgStartValue" "";
BA_DEF_DEF_ "GenMsgTimeOut" 0;
BA_DEF_DEF_ "GenSigCycleTime" 0;
BA_DEF_DEF_ "GenSigCycleTimeActive" 0;
BA_DEF_DEF_ "GenSigPersistent" "No";
BA_DEF_DEF_ "GenSigSNA" "";
BA_DEF_DEF_ "GenSigSendType" "Cyclic";
BA_DEF_DEF_ "GenSigStartValue" 0;
BA_DEF_DEF_ "GenSigTimeout_CGW" 0;
BA_DEF_DEF_ "GenSigTimeout_DRVU" 0;
BA_DEF_DEF_ "GenSigTimeout_ECM" 0;
BA_DEF_DEF_ "GenSigTimeout_EIS" 0;
BA_DEF_DEF_ "GenSigTimeout_EPS" 0;
BA_DEF_DEF_ "GenSigTimeout_ESP_ABR" 0;
BA_DEF_DEF_ "GenSigTimeout_IC" 0;
BA_DEF_DEF_ "GenSigTimeout_MPC" 0;
BA_DEF_DEF_ "GenSigTimeout_NV" 0;
BA_DEF_DEF_ "GenSigTimeout_ORC" 0;
BA_DEF_DEF_ "GenSigTimeout_PTS" 0;
BA_DEF_DEF_ "GenSigTimeout_RBTM_FL" 0;
BA_DEF_DEF_ "GenSigTimeout_RBTM_FR" 0;
BA_DEF_DEF_ "GenSigTimeout_RDU" 0;
BA_DEF_DEF_ "GenSigTimeout_SCCM" 0;
BA_DEF_DEF_ "GenSigTimeout_SPC" 0;
BA_DEF_DEF_ "GenSigTimeout_TPM" 0;
BA_DEF_DEF_ "LogSignal" "";
BA_DEF_DEF_ "MessageIdType" "normal";
BA_DEF_DEF_ "NWMBotschaft" "nein";
BA_DEF_DEF_ "NmMessage" "No";
BA_DEF_DEF_ "PektronUpdateBitType" "Not used";
BA_DEF_DEF_ "SubSystemId" 0;
BA_DEF_DEF_ "UsesChecksum" "No";
BA_DEF_DEF_REL_ "GenSigTimeoutTime" 0;
BA_ "AlertLogSubSystemId" BO_ 1297 214;
BA_ "GatewayHandlerEnum" BO_ 1297 2;
BA_ "GenMsgSendType" BO_ 1297 7;
BA_ "GenMsgCycleTime" BO_ 1521 500;
BA_ "GenMsgSendType" BO_ 1521 8;
BA_ "GenMsgCycleTime" BO_ 17 10;
BA_ "GenMsgSendType" BO_ 17 7;
BA_ "UsesChecksum" BO_ 17 1;
BA_ "GenMsgCycleTime" BO_ 881 1000;
BA_ "GenMsgCycleTime" BO_ 545 20;
BA_ "GenMsgCycleTime" BO_ 273 10;
BA_ "GenMsgSendType" BO_ 273 7;
BA_ "UsesChecksum" BO_ 273 1;
BA_ "GenMsgCycleTime" BO_ 529 100;
BA_ "UsesChecksum" BO_ 529 1;
BA_ "DiagResponse" BO_ 2041 1;
BA_ "GenMsgSendType" BO_ 2041 8;
BA_ "MessageIdType" BO_ 2041 2;
BA_ "DiagResponse" BO_ 1617 1;
BA_ "GatewayHandlerEnum" BO_ 1617 4;
BA_ "GenMsgSendType" BO_ 1617 8;
BA_ "MessageIdType" BO_ 1617 2;
BA_ "GenMsgCycleTime" BO_ 1538 20;
BA_ "GenMsgCycleTime" BO_ 1550 20;
BA_ "GenMsgCycleTime" BO_ 1544 20;
BA_ "GenMsgCycleTime" BO_ 1541 20;
BA_ "GenMsgCycleTime" BO_ 1536 20;
BA_ "GenMsgCycleTime" BO_ 1280 1000;
BA_ "GenMsgCycleTime" BO_ 1543 20;
BA_ "GenMsgCycleTime" BO_ 1537 20;
BA_ "GenMsgCycleTime" BO_ 1539 20;
BA_ "GenMsgCycleTime" BO_ 109 10;
BA_ "GenMsgStartValue" BO_ 109 "00E600FFh";
BA_ "MessageIdType" BO_ 109 10;
BA_ "GenMsgCycleTime" BO_ 815 100;
BA_ "GenMsgStartValue" BO_ 815 "FF030700FFFFFFFFh";
BA_ "MessageIdType" BO_ 815 10;
BA_ "AppBotschaft" BO_ 1944 1;
BA_ "DiagResponse" BO_ 1944 1;
BA_ "GatewayHandlerEnum" BO_ 1944 4;
BA_ "GenMsgCycleTime" BO_ 1944 100;
BA_ "GenMsgSendType" BO_ 1944 8;
BA_ "GenMsgStartValue" BO_ 1944 "0000000000000000h";
BA_ "MessageIdType" BO_ 1944 2;
BA_ "GenMsgCycleTime" BO_ 638 50;
BA_ "FieldType" SG_ 1009 RCM2_a567_seaTrkPosLeftConfig "PASSIVE_SAFETY_ALERT";
BA_ "GenSigSendType" SG_ 1009 RCM2_a567_seaTrkPosLeftConfig 7;
BA_ "FieldType" SG_ 1009 RCM2_a568_occPROSSht2Gnd "PASSIVE_SAFETY_ALERT";
BA_ "GenSigSendType" SG_ 1009 RCM2_a568_occPROSSht2Gnd 7;
BA_ "FieldType" SG_ 1009 RCM2_a569_occPROSSht2Bat "PASSIVE_SAFETY_ALERT";
BA_ "GenSigSendType" SG_ 1009 RCM2_a569_occPROSSht2Bat 7;
BA_ "FieldType" SG_ 1009 RCM2_a570_occPROSOpen "PASSIVE_SAFETY_ALERT";
BA_ "GenSigSendType" SG_ 1009 RCM2_a570_occPROSOpen 7;
BA_ "FieldType" SG_ 1009 RCM2_a571_occPROSUndef "PASSIVE_SAFETY_ALERT";
BA_ "GenSigSendType" SG_ 1009 RCM2_a571_occPROSUndef 7;
BA_ "FieldType" SG_ 1009 RCM2_a572_occPROSCrssCoup "PASSIVE_SAFETY_ALERT";
BA_ "GenSigSendType" SG_ 1009 RCM2_a572_occPROSCrssCoup 7;
BA_ "FieldType" SG_ 1009 RCM2_a573_occPROSConfig "PASSIVE_SAFETY_ALERT";
BA_ "GenSigSendType" SG_ 1009 RCM2_a573_occPROSConfig 7;
BA_ "FieldType" SG_ 1009 RCM2_a587_sbrRearNetSht2Gnd "PASSIVE_SAFETY_ALERT";
BA_ "GenSigSendType" SG_ 1009 RCM2_a587_sbrRearNetSht2Gnd 7;
BA_ "FieldType" SG_ 1009 RCM2_a588_sbrRearNetSht2Bat "PASSIVE_SAFETY_ALERT";
BA_ "GenSigSendType" SG_ 1009 RCM2_a588_sbrRearNetSht2Bat 7;
BA_ "FieldType" SG_ 1009 RCM2_a589_sbrRearNetOpen "PASSIVE_SAFETY_ALERT";
BA_ "GenSigSendType" SG_ 1009 RCM2_a589_sbrRearNetOpen 7;
BA_ "FieldType" SG_ 1009 RCM2_a590_sbrRearNetUndefined "PASSIVE_SAFETY_ALERT";
BA_ "GenSigSendType" SG_ 1009 RCM2_a590_sbrRearNetUndefined 7;
BA_ "FieldType" SG_ 1009 RCM2_a591_sbrRearNetCrssCoup "PASSIVE_SAFETY_ALERT";
BA_ "GenSigSendType" SG_ 1009 RCM2_a591_sbrRearNetCrssCoup 7;
BA_ "FieldType" SG_ 1009 RCM2_a592_sbrRearNetConfig "PASSIVE_SAFETY_ALERT";
BA_ "GenSigSendType" SG_ 1009 RCM2_a592_sbrRearNetConfig 7;
BA_ "FieldType" SG_ 1009 RCM2_a593_driveOrientaSht2Gnd "PASSIVE_SAFETY_ALERT";
BA_ "GenSigSendType" SG_ 1009 RCM2_a593_driveOrientaSht2Gnd 7;
BA_ "FieldType" SG_ 1009 RCM2_a594_driveOrientaSht2Bat "PASSIVE_SAFETY_ALERT";
BA_ "GenSigSendType" SG_ 1009 RCM2_a594_driveOrientaSht2Bat 7;
BA_ "FieldType" SG_ 1009 RCM2_a595_driveOrientaOpen "PASSIVE_SAFETY_ALERT";
BA_ "GenSigSendType" SG_ 1009 RCM2_a595_driveOrientaOpen 7;
BA_ "FieldType" SG_ 1009 RCM2_a596_driveOrientaUndefined "PASSIVE_SAFETY_ALERT";
BA_ "GenSigSendType" SG_ 1009 RCM2_a596_driveOrientaUndefined 7;
BA_ "FieldType" SG_ 1009 RCM2_a597_driveOrientaCrssCoup "PASSIVE_SAFETY_ALERT";
BA_ "GenSigSendType" SG_ 1009 RCM2_a597_driveOrientaCrssCoup 7;
BA_ "FieldType" SG_ 1009 RCM2_a598_driveOrientaConfig "PASSIVE_SAFETY_ALERT";
BA_ "GenSigSendType" SG_ 1009 RCM2_a598_driveOrientaConfig 7;
BA_ "FieldType" SG_ 1009 RCM2_a600_comCANinternalTimeout "PASSIVE_SAFETY_ALERT";
BA_ "GenSigSendType" SG_ 1009 RCM2_a600_comCANinternalTimeout 7;
BA_ "FieldType" SG_ 1009 RCM2_a601_comChassisCANInit "PASSIVE_SAFETY_ALERT";
BA_ "GenSigSendType" SG_ 1009 RCM2_a601_comChassisCANInit 7;
BA_ "FieldType" SG_ 1009 RCM2_a602_comChassisCANBusOff "PASSIVE_SAFETY_ALERT";
BA_ "GenSigSendType" SG_ 1009 RCM2_a602_comChassisCANBusOff 7;
BA_ "FieldType" SG_ 1009 RCM2_a603_comPARTYCANInit "PASSIVE_SAFETY_ALERT";
BA_ "GenSigSendType" SG_ 1009 RCM2_a603_comPARTYCANInit 7;
BA_ "FieldType" SG_ 1009 RCM2_a604_comPARTYCANBusOff "PASSIVE_SAFETY_ALERT";
BA_ "GenSigSendType" SG_ 1009 RCM2_a604_comPARTYCANBusOff 7;
BA_ "FieldType" SG_ 1009 RCM2_a605_comStwAngStatMIA "PASSIVE_SAFETY_ALERT";
BA_ "GenSigSendType" SG_ 1009 RCM2_a605_comStwAngStatMIA 7;
BA_ "FieldType" SG_ 1009 RCM2_a606_comStwAngStatChkSm "PASSIVE_SAFETY_ALERT";
BA_ "GenSigSendType" SG_ 1009 RCM2_a606_comStwAngStatChkSm 7;
BA_ "FieldType" SG_ 1009 RCM2_a607_comStwAngStatCntr "PASSIVE_SAFETY_ALERT";
BA_ "GenSigSendType" SG_ 1009 RCM2_a607_comStwAngStatCntr 7;
BA_ "FieldType" SG_ 1009 RCM2_a608_comDItorque1MIA "PASSIVE_SAFETY_ALERT";
BA_ "GenSigSendType" SG_ 1009 RCM2_a608_comDItorque1MIA 7;
BA_ "FieldType" SG_ 1009 RCM2_a609_comDItorque1ChkSm "PASSIVE_SAFETY_ALERT";
BA_ "GenSigSendType" SG_ 1009 RCM2_a609_comDItorque1ChkSm 7;
BA_ "FieldType" SG_ 1009 RCM2_a610_comDItorque1Cntr "PASSIVE_SAFETY_ALERT";
BA_ "GenSigSendType" SG_ 1009 RCM2_a610_comDItorque1Cntr 7;
BA_ "FieldType" SG_ 1009 RCM2_a611_comDItorque2MIA "PASSIVE_SAFETY_ALERT";
BA_ "GenSigSendType" SG_ 1009 RCM2_a611_comDItorque2MIA 7;
BA_ "FieldType" SG_ 1009 RCM2_a612_comDItorque2ChkSm "PASSIVE_SAFETY_ALERT";
BA_ "GenSigSendType" SG_ 1009 RCM2_a612_comDItorque2ChkSm 7;
BA_ "FieldType" SG_ 1009 RCM2_a613_comDItorque2Cntr "PASSIVE_SAFETY_ALERT";
BA_ "GenSigSendType" SG_ 1009 RCM2_a613_comDItorque2Cntr 7;
BA_ "FieldType" SG_ 1009 RCM2_a614_comESP135MIA "PASSIVE_SAFETY_ALERT";
BA_ "GenSigSendType" SG_ 1009 RCM2_a614_comESP135MIA 7;
BA_ "FieldType" SG_ 1009 RCM2_a615_comESP135ChkSm "PASSIVE_SAFETY_ALERT";
BA_ "GenSigSendType" SG_ 1009 RCM2_a615_comESP135ChkSm 7;
BA_ "FieldType" SG_ 1009 RCM2_a616_comESP135Cntr "PASSIVE_SAFETY_ALERT";
BA_ "GenSigSendType" SG_ 1009 RCM2_a616_comESP135Cntr 7;
BA_ "FieldType" SG_ 1009 RCM2_a617_comESP145MIA "PASSIVE_SAFETY_ALERT";
BA_ "GenSigSendType" SG_ 1009 RCM2_a617_comESP145MIA 7;
BA_ "FieldType" SG_ 1009 RCM2_a618_comESP145ChkSm "PASSIVE_SAFETY_ALERT";
BA_ "GenSigSendType" SG_ 1009 RCM2_a618_comESP145ChkSm 7;
BA_ "FieldType" SG_ 1009 RCM2_a619_comESP145Cntr "PASSIVE_SAFETY_ALERT";
BA_ "GenSigSendType" SG_ 1009 RCM2_a619_comESP145Cntr 7;
BA_ "FieldType" SG_ 1009 RCM2_a620_comInvalidVehicleSpeed "PASSIVE_SAFETY_ALERT";
BA_ "GenSigSendType" SG_ 1009 RCM2_a620_comInvalidVehicleSpeed 7;
BA_ "FieldType" SG_ 1009 RCM2_a621_comESPBMIA "PASSIVE_SAFETY_ALERT";
BA_ "GenSigSendType" SG_ 1009 RCM2_a621_comESPBMIA 7;
BA_ "FieldType" SG_ 1009 RCM2_a622_comESPBChkSm "PASSIVE_SAFETY_ALERT";
BA_ "GenSigSendType" SG_ 1009 RCM2_a622_comESPBChkSm 7;
BA_ "FieldType" SG_ 1009 RCM2_a623_comESPBCntr "PASSIVE_SAFETY_ALERT";
BA_ "GenSigSendType" SG_ 1009 RCM2_a623_comESPBCntr 7;
BA_ "FieldType" SG_ 1009 RCM2_a624_comESPCMIA "PASSIVE_SAFETY_ALERT";
BA_ "GenSigSendType" SG_ 1009 RCM2_a624_comESPCMIA 7;
BA_ "FieldType" SG_ 1009 RCM2_a625_comESPCChkSm "PASSIVE_SAFETY_ALERT";
BA_ "GenSigSendType" SG_ 1009 RCM2_a625_comESPCChkSm 7;
BA_ "FieldType" SG_ 1009 RCM2_a626_comESPCCntr "PASSIVE_SAFETY_ALERT";
BA_ "GenSigSendType" SG_ 1009 RCM2_a626_comESPCCntr 7;
BA_ "FieldType" SG_ 1009 RCM2_a627_comEPBStatusMIA "PASSIVE_SAFETY_ALERT";
BA_ "GenSigSendType" SG_ 1009 RCM2_a627_comEPBStatusMIA 7;
BA_ "FieldType" SG_ 1009 RCM2_a628_comEPBStatusChkSm "PASSIVE_SAFETY_ALERT";
BA_ "GenSigSendType" SG_ 1009 RCM2_a628_comEPBStatusChkSm 7;
BA_ "FieldType" SG_ 1009 RCM2_a629_comEPBStatusCntr "PASSIVE_SAFETY_ALERT";
BA_ "GenSigSendType" SG_ 1009 RCM2_a629_comEPBStatusCntr 7;
BA_ "FieldType" SG_ 1009 RCM2_a630_comGTWACSMIA "PASSIVE_SAFETY_ALERT";
BA_ "GenSigSendType" SG_ 1009 RCM2_a630_comGTWACSMIA 7;
BA_ "FieldType" SG_ 1009 RCM2_a631_comGTWACSChkSm "PASSIVE_SAFETY_ALERT";
BA_ "GenSigSendType" SG_ 1009 RCM2_a631_comGTWACSChkSm 7;
BA_ "FieldType" SG_ 1009 RCM2_a632_comGTWACSCntr "PASSIVE_SAFETY_ALERT";
BA_ "GenSigSendType" SG_ 1009 RCM2_a632_comGTWACSCntr 7;
BA_ "FieldType" SG_ 1009 RCM2_a633_comOCS1PMIA "PASSIVE_SAFETY_ALERT";
BA_ "GenSigSendType" SG_ 1009 RCM2_a633_comOCS1PMIA 7;
BA_ "FieldType" SG_ 1009 RCM2_a634_comOCS1PChkSm "PASSIVE_SAFETY_ALERT";
BA_ "GenSigSendType" SG_ 1009 RCM2_a634_comOCS1PChkSm 7;
BA_ "FieldType" SG_ 1009 RCM2_a635_comOCS1PCntr "PASSIVE_SAFETY_ALERT";
BA_ "GenSigSendType" SG_ 1009 RCM2_a635_comOCS1PCntr 7;
BA_ "FieldType" SG_ 1009 RCM2_a636_ocsFaulted "PASSIVE_SAFETY_ALERT";
BA_ "GenSigSendType" SG_ 1009 RCM2_a636_ocsFaulted 7;
BA_ "FieldType" SG_ 1009 RCM2_a637_ocsUnknown "PASSIVE_SAFETY_ALERT";
BA_ "GenSigSendType" SG_ 1009 RCM2_a637_ocsUnknown 7;
BA_ "FieldType" SG_ 1009 RCM2_a638_comGTWodoMIA "PASSIVE_SAFETY_ALERT";
BA_ "GenSigSendType" SG_ 1009 RCM2_a638_comGTWodoMIA 7;
BA_ "FieldType" SG_ 1009 RCM2_a639_comGTWCarStateMIA "PASSIVE_SAFETY_ALERT";
BA_ "GenSigSendType" SG_ 1009 RCM2_a639_comGTWCarStateMIA 7;
BA_ "FieldType" SG_ 1009 RCM2_a640_comTPMSStatusCMIA "PASSIVE_SAFETY_ALERT";
BA_ "GenSigSendType" SG_ 1009 RCM2_a640_comTPMSStatusCMIA 7;
BA_ "FieldType" SG_ 1009 RCM2_a641_comGTWCarConfigMIA "PASSIVE_SAFETY_ALERT";
BA_ "GenSigSendType" SG_ 1009 RCM2_a641_comGTWCarConfigMIA 7;
BA_ "FieldType" SG_ 1009 RCM2_a642_comVINmessageMIA "PASSIVE_SAFETY_ALERT";
BA_ "GenSigSendType" SG_ 1009 RCM2_a642_comVINmessageMIA 7;
BA_ "FieldType" SG_ 1009 RCM2_a643_comDASSafetyFrntMIA "PASSIVE_SAFETY_ALERT";
BA_ "GenSigSendType" SG_ 1009 RCM2_a643_comDASSafetyFrntMIA 7;
BA_ "FieldType" SG_ 1009 RCM2_a644_comDASSafetyFrntChkSm "PASSIVE_SAFETY_ALERT";
BA_ "GenSigSendType" SG_ 1009 RCM2_a644_comDASSafetyFrntChkSm 7;
BA_ "FieldType" SG_ 1009 RCM2_a645_comDASSafetyFrntCntr "PASSIVE_SAFETY_ALERT";
BA_ "GenSigSendType" SG_ 1009 RCM2_a645_comDASSafetyFrntCntr 7;
BA_ "FieldType" SG_ 1009 RCM2_a646_comDIstateMIA "PASSIVE_SAFETY_ALERT";
BA_ "GenSigSendType" SG_ 1009 RCM2_a646_comDIstateMIA 7;
BA_ "FieldType" SG_ 1009 RCM2_a647_comDIstateChkSm "PASSIVE_SAFETY_ALERT";
BA_ "GenSigSendType" SG_ 1009 RCM2_a647_comDIstateChkSm 7;
BA_ "FieldType" SG_ 1009 RCM2_a648_comDIstateCntr "PASSIVE_SAFETY_ALERT";
BA_ "GenSigSendType" SG_ 1009 RCM2_a648_comDIstateCntr 7;
BA_ "FieldType" SG_ 1009 RCM2_a649_comDIstate2MIA "PASSIVE_SAFETY_ALERT";
BA_ "GenSigSendType" SG_ 1009 RCM2_a649_comDIstate2MIA 7;
BA_ "FieldType" SG_ 1009 RCM2_a650_comDIstate2ChkSm "PASSIVE_SAFETY_ALERT";
BA_ "GenSigSendType" SG_ 1009 RCM2_a650_comDIstate2ChkSm 7;
BA_ "FieldType" SG_ 1009 RCM2_a651_comDIstate2Cntr "PASSIVE_SAFETY_ALERT";
BA_ "GenSigSendType" SG_ 1009 RCM2_a651_comDIstate2Cntr 7;
BA_ "FieldType" SG_ 1009 RCM2_a652_ambientTempFaulted "PASSIVE_SAFETY_ALERT";
BA_ "GenSigSendType" SG_ 1009 RCM2_a652_ambientTempFaulted 7;
BA_ "FieldType" SG_ 1009 RCM2_a653_comGTWESP1MIA "PASSIVE_SAFETY_ALERT";
BA_ "GenSigSendType" SG_ 1009 RCM2_a653_comGTWESP1MIA 7;
BA_ "FieldType" SG_ 1009 RCM2_a654_comGTWESP1ChkSm "PASSIVE_SAFETY_ALERT";
BA_ "GenSigSendType" SG_ 1009 RCM2_a654_comGTWESP1ChkSm 7;
BA_ "FieldType" SG_ 1009 RCM2_a655_comGTWESP1Cntr "PASSIVE_SAFETY_ALERT";
BA_ "GenSigSendType" SG_ 1009 RCM2_a655_comGTWESP1Cntr 7;
BA_ "FieldType" SG_ 1009 RCM2_a750_linInternalTimeout "PASSIVE_SAFETY_ALERT";
BA_ "GenSigSendType" SG_ 1009 RCM2_a750_linInternalTimeout 7;
BA_ "FieldType" SG_ 1009 RCM2_a800_cfgMissingCalibration "PASSIVE_SAFETY_ALERT";
BA_ "GenSigSendType" SG_ 1009 RCM2_a800_cfgMissingCalibration 7;
BA_ "FieldType" SG_ 1009 RCM2_a801_cfgImplausConfig "PASSIVE_SAFETY_ALERT";
BA_ "GenSigSendType" SG_ 1009 RCM2_a801_cfgImplausConfig 7;
BA_ "FieldType" SG_ 1009 RCM2_a802_cfgInvalidConfig "PASSIVE_SAFETY_ALERT";
BA_ "GenSigSendType" SG_ 1009 RCM2_a802_cfgInvalidConfig 7;
BA_ "FieldType" SG_ 1009 RCM2_a803_cfgNotConfigured "PASSIVE_SAFETY_ALERT";
BA_ "GenSigSendType" SG_ 1009 RCM2_a803_cfgNotConfigured 7;
BA_ "FieldType" SG_ 1009 RCM2_a804_cfgNotProgrammed "PASSIVE_SAFETY_ALERT";
BA_ "GenSigSendType" SG_ 1009 RCM2_a804_cfgNotProgrammed 7;
BA_ "FieldType" SG_ 1009 RCM2_a805_cfgPedProNotProgrammed "PASSIVE_SAFETY_ALERT";
BA_ "GenSigSendType" SG_ 1009 RCM2_a805_cfgPedProNotProgrammed 7;
BA_ "FieldType" SG_ 1009 RCM2_a806_cfgCrashCalPNmissing "PASSIVE_SAFETY_ALERT";
BA_ "GenSigSendType" SG_ 1009 RCM2_a806_cfgCrashCalPNmissing 7;
BA_ "FieldType" SG_ 1009 RCM2_a807_cfgExternalCRCError "PASSIVE_SAFETY_ALERT";
BA_ "GenSigSendType" SG_ 1009 RCM2_a807_cfgExternalCRCError 7;
BA_ "FieldType" SG_ 1009 RCM2_a808_cfgInvalParamLayoutID "PASSIVE_SAFETY_ALERT";
BA_ "GenSigSendType" SG_ 1009 RCM2_a808_cfgInvalParamLayoutID 7;
BA_ "FieldType" SG_ 1009 RCM2_a809_cfgInvalParamTransID "PASSIVE_SAFETY_ALERT";
BA_ "GenSigSendType" SG_ 1009 RCM2_a809_cfgInvalParamTransID 7;
BA_ "FieldType" SG_ 1009 RCM2_a810_cfgAlgoVerifySnsrID "PASSIVE_SAFETY_ALERT";
BA_ "GenSigSendType" SG_ 1009 RCM2_a810_cfgAlgoVerifySnsrID 7;
BA_ "FieldType" SG_ 1009 RCM2_a811_cfgConfigDataInconsist "PASSIVE_SAFETY_ALERT";
BA_ "GenSigSendType" SG_ 1009 RCM2_a811_cfgConfigDataInconsist 7;
BA_ "FieldType" SG_ 1009 RCM2_a812_swVersionWrong "PASSIVE_SAFETY_ALERT";
BA_ "GenSigSendType" SG_ 1009 RCM2_a812_swVersionWrong 7;
BA_ "FieldType" SG_ 1009 RCM2_a813_vinNotProgrammed "PASSIVE_SAFETY_ALERT";
BA_ "GenSigSendType" SG_ 1009 RCM2_a813_vinNotProgrammed 7;
BA_ "FieldType" SG_ 1009 RCM2_a814_vinMismatch "PASSIVE_SAFETY_ALERT";
BA_ "GenSigSendType" SG_ 1009 RCM2_a814_vinMismatch 7;
BA_ "FieldType" SG_ 1009 RCM2_a815_driveLeaningNotDone "PASSIVE_SAFETY_ALERT";
BA_ "GenSigSendType" SG_ 1009 RCM2_a815_driveLeaningNotDone 7;
BA_ "FieldType" SG_ 1009 RCM2_a816_driveLeaningMismatch "PASSIVE_SAFETY_ALERT";
BA_ "GenSigSendType" SG_ 1009 RCM2_a816_driveLeaningMismatch 7;
BA_ "FieldType" SG_ 1009 RCM2_a817_bootActionsFailed "PASSIVE_SAFETY_ALERT";
BA_ "GenSigSendType" SG_ 1009 RCM2_a817_bootActionsFailed 7;
BA_ "FieldType" SG_ 1009 RCM2_a850_internalFault_001 "PASSIVE_SAFETY_ALERT";
BA_ "GenSigSendType" SG_ 1009 RCM2_a850_internalFault_001 7;
BA_ "FieldType" SG_ 1009 RCM2_a851_internalFault_002 "PASSIVE_SAFETY_ALERT";
BA_ "GenSigSendType" SG_ 1009 RCM2_a851_internalFault_002 7;
BA_ "FieldType" SG_ 1009 RCM2_a852_internalFault_003 "PASSIVE_SAFETY_ALERT";
BA_ "GenSigSendType" SG_ 1009 RCM2_a852_internalFault_003 7;
BA_ "FieldType" SG_ 1009 RCM2_a853_internalFault_004 "PASSIVE_SAFETY_ALERT";
BA_ "GenSigSendType" SG_ 1009 RCM2_a853_internalFault_004 7;
BA_ "FieldType" SG_ 1009 RCM2_a854_internalFault_005 "PASSIVE_SAFETY_ALERT";
BA_ "GenSigSendType" SG_ 1009 RCM2_a854_internalFault_005 7;
BA_ "FieldType" SG_ 1009 RCM2_a855_internalFault_006 "PASSIVE_SAFETY_ALERT";
BA_ "GenSigSendType" SG_ 1009 RCM2_a855_internalFault_006 7;
BA_ "FieldType" SG_ 1009 RCM2_a856_internalFault_007 "PASSIVE_SAFETY_ALERT";
BA_ "GenSigSendType" SG_ 1009 RCM2_a856_internalFault_007 7;
BA_ "FieldType" SG_ 1009 RCM2_a857_internalFault_008 "PASSIVE_SAFETY_ALERT";
BA_ "GenSigSendType" SG_ 1009 RCM2_a857_internalFault_008 7;
BA_ "FieldType" SG_ 1009 RCM2_a858_internalFault_009 "PASSIVE_SAFETY_ALERT";
BA_ "GenSigSendType" SG_ 1009 RCM2_a858_internalFault_009 7;
BA_ "FieldType" SG_ 1009 RCM2_a859_internalFault_010 "PASSIVE_SAFETY_ALERT";
BA_ "GenSigSendType" SG_ 1009 RCM2_a859_internalFault_010 7;
BA_ "FieldType" SG_ 1009 RCM2_a860_internalFault_011 "PASSIVE_SAFETY_ALERT";
BA_ "GenSigSendType" SG_ 1009 RCM2_a860_internalFault_011 7;
BA_ "FieldType" SG_ 1009 RCM2_a861_internalFault_012 "PASSIVE_SAFETY_ALERT";
BA_ "GenSigSendType" SG_ 1009 RCM2_a861_internalFault_012 7;
BA_ "FieldType" SG_ 1009 RCM2_a862_internalFault_013 "PASSIVE_SAFETY_ALERT";
BA_ "GenSigSendType" SG_ 1009 RCM2_a862_internalFault_013 7;
BA_ "FieldType" SG_ 1009 RCM2_a863_internalFault_014 "PASSIVE_SAFETY_ALERT";
BA_ "GenSigSendType" SG_ 1009 RCM2_a863_internalFault_014 7;
BA_ "FieldType" SG_ 1009 RCM2_a864_internalFault_015 "PASSIVE_SAFETY_ALERT";
BA_ "GenSigSendType" SG_ 1009 RCM2_a864_internalFault_015 7;
BA_ "FieldType" SG_ 1009 RCM2_a865_internalFault_016 "PASSIVE_SAFETY_ALERT";
BA_ "GenSigSendType" SG_ 1009 RCM2_a865_internalFault_016 7;
BA_ "FieldType" SG_ 1009 RCM2_a866_internalFault_017 "PASSIVE_SAFETY_ALERT";
BA_ "GenSigSendType" SG_ 1009 RCM2_a866_internalFault_017 7;
BA_ "FieldType" SG_ 1009 RCM2_a867_internalFault_018 "PASSIVE_SAFETY_ALERT";
BA_ "GenSigSendType" SG_ 1009 RCM2_a867_internalFault_018 7;
BA_ "FieldType" SG_ 1009 RCM2_a868_internalFault_019 "PASSIVE_SAFETY_ALERT";
BA_ "GenSigSendType" SG_ 1009 RCM2_a868_internalFault_019 7;
BA_ "FieldType" SG_ 1009 RCM2_a869_internalFault_020 "PASSIVE_SAFETY_ALERT";
BA_ "GenSigSendType" SG_ 1009 RCM2_a869_internalFault_020 7;
BA_ "FieldType" SG_ 1009 RCM2_a870_internalFault_021 "PASSIVE_SAFETY_ALERT";
BA_ "GenSigSendType" SG_ 1009 RCM2_a870_internalFault_021 7;
BA_ "FieldType" SG_ 1009 RCM2_a871_internalFault_022 "PASSIVE_SAFETY_ALERT";
BA_ "GenSigSendType" SG_ 1009 RCM2_a871_internalFault_022 7;
BA_ "FieldType" SG_ 1009 RCM2_a872_internalFault_023 "PASSIVE_SAFETY_ALERT";
BA_ "GenSigSendType" SG_ 1009 RCM2_a872_internalFault_023 7;
BA_ "FieldType" SG_ 1009 RCM2_a873_internalFault_024 "PASSIVE_SAFETY_ALERT";
BA_ "GenSigSendType" SG_ 1009 RCM2_a873_internalFault_024 7;
BA_ "FieldType" SG_ 1009 RCM2_a874_internalFault_025 "PASSIVE_SAFETY_ALERT";
BA_ "GenSigSendType" SG_ 1009 RCM2_a874_internalFault_025 7;
BA_ "FieldType" SG_ 1009 RCM2_a875_internalFault_026 "PASSIVE_SAFETY_ALERT";
BA_ "GenSigSendType" SG_ 1009 RCM2_a875_internalFault_026 7;
BA_ "FieldType" SG_ 1009 RCM2_a876_internalFault_027 "PASSIVE_SAFETY_ALERT";
BA_ "GenSigSendType" SG_ 1009 RCM2_a876_internalFault_027 7;
BA_ "FieldType" SG_ 1009 RCM2_a877_internalFault_028 "PASSIVE_SAFETY_ALERT";
BA_ "GenSigSendType" SG_ 1009 RCM2_a877_internalFault_028 7;
BA_ "FieldType" SG_ 1009 RCM2_a878_internalFault_029 "PASSIVE_SAFETY_ALERT";
BA_ "GenSigSendType" SG_ 1009 RCM2_a878_internalFault_029 7;
BA_ "FieldType" SG_ 1009 RCM2_a879_internalFault_030 "PASSIVE_SAFETY_ALERT";
BA_ "GenSigSendType" SG_ 1009 RCM2_a879_internalFault_030 7;
BA_ "FieldType" SG_ 1009 RCM2_a880_internalFault_031 "PASSIVE_SAFETY_ALERT";
BA_ "GenSigSendType" SG_ 1009 RCM2_a880_internalFault_031 7;
BA_ "FieldType" SG_ 1009 RCM2_a881_internalFault_032 "PASSIVE_SAFETY_ALERT";
BA_ "GenSigSendType" SG_ 1009 RCM2_a881_internalFault_032 7;
BA_ "FieldType" SG_ 1009 RCM2_a882_internalFault_033 "PASSIVE_SAFETY_ALERT";
BA_ "GenSigSendType" SG_ 1009 RCM2_a882_internalFault_033 7;
BA_ "FieldType" SG_ 1009 RCM2_a883_internalFault_034 "PASSIVE_SAFETY_ALERT";
BA_ "GenSigSendType" SG_ 1009 RCM2_a883_internalFault_034 7;
BA_ "FieldType" SG_ 1009 RCM2_a884_internalFault_035 "PASSIVE_SAFETY_ALERT";
BA_ "GenSigSendType" SG_ 1009 RCM2_a884_internalFault_035 7;
BA_ "FieldType" SG_ 1009 RCM2_a885_internalFault_036 "PASSIVE_SAFETY_ALERT";
BA_ "GenSigSendType" SG_ 1009 RCM2_a885_internalFault_036 7;
BA_ "FieldType" SG_ 1009 RCM2_a886_internalFault_037 "PASSIVE_SAFETY_ALERT";
BA_ "GenSigSendType" SG_ 1009 RCM2_a886_internalFault_037 7;
BA_ "FieldType" SG_ 1009 RCM2_a887_internalFault_038 "PASSIVE_SAFETY_ALERT";
BA_ "GenSigSendType" SG_ 1009 RCM2_a887_internalFault_038 7;
BA_ "FieldType" SG_ 1009 RCM2_a888_internalFault_039 "PASSIVE_SAFETY_ALERT";
BA_ "GenSigSendType" SG_ 1009 RCM2_a888_internalFault_039 7;
BA_ "FieldType" SG_ 1009 RCM2_a889_internalFault_040 "PASSIVE_SAFETY_ALERT";
BA_ "GenSigSendType" SG_ 1009 RCM2_a889_internalFault_040 7;
BA_ "FieldType" SG_ 1009 RCM2_a890_internalFault_041 "PASSIVE_SAFETY_ALERT";
BA_ "GenSigSendType" SG_ 1009 RCM2_a890_internalFault_041 7;
BA_ "FieldType" SG_ 1009 RCM2_a891_internalFault_042 "PASSIVE_SAFETY_ALERT";
BA_ "GenSigSendType" SG_ 1009 RCM2_a891_internalFault_042 7;
BA_ "FieldType" SG_ 1009 RCM2_a892_internalFault_043 "PASSIVE_SAFETY_ALERT";
BA_ "GenSigSendType" SG_ 1009 RCM2_a892_internalFault_043 7;
BA_ "FieldType" SG_ 1009 RCM2_a893_internalFault_044 "PASSIVE_SAFETY_ALERT";
BA_ "GenSigSendType" SG_ 1009 RCM2_a893_internalFault_044 7;
BA_ "FieldType" SG_ 1009 RCM2_a894_internalFault_045 "PASSIVE_SAFETY_ALERT";
BA_ "GenSigSendType" SG_ 1009 RCM2_a894_internalFault_045 7;
BA_ "FieldType" SG_ 1009 RCM2_a895_internalFault_046 "PASSIVE_SAFETY_ALERT";
BA_ "GenSigSendType" SG_ 1009 RCM2_a895_internalFault_046 7;
BA_ "FieldType" SG_ 1009 RCM2_a896_internalFault_047 "PASSIVE_SAFETY_ALERT";
BA_ "GenSigSendType" SG_ 1009 RCM2_a896_internalFault_047 7;
BA_ "FieldType" SG_ 1009 RCM2_a897_internalFault_048 "PASSIVE_SAFETY_ALERT";
BA_ "GenSigSendType" SG_ 1009 RCM2_a897_internalFault_048 7;
BA_ "FieldType" SG_ 1009 RCM2_a898_internalFault_049 "PASSIVE_SAFETY_ALERT";
BA_ "GenSigSendType" SG_ 1009 RCM2_a898_internalFault_049 7;
BA_ "FieldType" SG_ 1009 RCM2_a899_internalFault_050 "PASSIVE_SAFETY_ALERT";
BA_ "GenSigSendType" SG_ 1009 RCM2_a899_internalFault_050 7;
BA_ "FieldType" SG_ 1009 RCM2_a900_internalFault_051 "PASSIVE_SAFETY_ALERT";
BA_ "GenSigSendType" SG_ 1009 RCM2_a900_internalFault_051 7;
BA_ "FieldType" SG_ 1009 RCM2_a901_internalFault_052 "PASSIVE_SAFETY_ALERT";
BA_ "GenSigSendType" SG_ 1009 RCM2_a901_internalFault_052 7;
BA_ "FieldType" SG_ 1009 RCM2_a902_internalFault_053 "PASSIVE_SAFETY_ALERT";
BA_ "GenSigSendType" SG_ 1009 RCM2_a902_internalFault_053 7;
BA_ "FieldType" SG_ 1009 RCM2_a903_internalFault_054 "PASSIVE_SAFETY_ALERT";
BA_ "GenSigSendType" SG_ 1009 RCM2_a903_internalFault_054 7;
BA_ "FieldType" SG_ 1009 RCM2_a904_internalFault_055 "PASSIVE_SAFETY_ALERT";
BA_ "GenSigSendType" SG_ 1009 RCM2_a904_internalFault_055 7;
BA_ "FieldType" SG_ 1009 RCM2_a905_internalFault_056 "PASSIVE_SAFETY_ALERT";
BA_ "GenSigSendType" SG_ 1009 RCM2_a905_internalFault_056 7;
BA_ "FieldType" SG_ 1009 RCM2_a906_internalFault_057 "PASSIVE_SAFETY_ALERT";
BA_ "GenSigSendType" SG_ 1009 RCM2_a906_internalFault_057 7;
BA_ "FieldType" SG_ 1009 RCM2_a907_internalFault_058 "PASSIVE_SAFETY_ALERT";
BA_ "GenSigSendType" SG_ 1009 RCM2_a907_internalFault_058 7;
BA_ "FieldType" SG_ 1009 RCM2_a908_internalFault_059 "PASSIVE_SAFETY_ALERT";
BA_ "GenSigSendType" SG_ 1009 RCM2_a908_internalFault_059 7;
BA_ "FieldType" SG_ 1009 RCM2_a909_internalFault_060 "PASSIVE_SAFETY_ALERT";
BA_ "GenSigSendType" SG_ 1009 RCM2_a909_internalFault_060 7;
BA_ "FieldType" SG_ 1009 RCM2_a910_internalFault_061 "PASSIVE_SAFETY_ALERT";
BA_ "GenSigSendType" SG_ 1009 RCM2_a910_internalFault_061 7;
BA_ "FieldType" SG_ 1009 RCM2_a911_internalFault_062 "PASSIVE_SAFETY_ALERT";
BA_ "GenSigSendType" SG_ 1009 RCM2_a911_internalFault_062 7;
BA_ "FieldType" SG_ 1009 RCM2_a912_internalFault_063 "PASSIVE_SAFETY_ALERT";
BA_ "GenSigSendType" SG_ 1009 RCM2_a912_internalFault_063 7;
BA_ "FieldType" SG_ 1009 RCM2_a913_internalFault_064 "PASSIVE_SAFETY_ALERT";
BA_ "GenSigSendType" SG_ 1009 RCM2_a913_internalFault_064 7;
BA_ "FieldType" SG_ 1009 RCM2_a914_internalFault_065 "PASSIVE_SAFETY_ALERT";
BA_ "GenSigSendType" SG_ 1009 RCM2_a914_internalFault_065 7;
BA_ "FieldType" SG_ 1009 RCM2_a915_internalFault_066 "PASSIVE_SAFETY_ALERT";
BA_ "GenSigSendType" SG_ 1009 RCM2_a915_internalFault_066 7;
BA_ "FieldType" SG_ 1009 RCM2_a916_internalFault_067 "PASSIVE_SAFETY_ALERT";
BA_ "GenSigSendType" SG_ 1009 RCM2_a916_internalFault_067 7;
BA_ "FieldType" SG_ 1009 RCM2_a917_internalFault_068 "PASSIVE_SAFETY_ALERT";
BA_ "GenSigSendType" SG_ 1009 RCM2_a917_internalFault_068 7;
BA_ "FieldType" SG_ 1009 RCM2_a918_internalFault_069 "PASSIVE_SAFETY_ALERT";
BA_ "GenSigSendType" SG_ 1009 RCM2_a918_internalFault_069 7;
BA_ "FieldType" SG_ 1009 RCM2_a919_internalFault_070 "PASSIVE_SAFETY_ALERT";
BA_ "GenSigSendType" SG_ 1009 RCM2_a919_internalFault_070 7;
BA_ "FieldType" SG_ 1009 RCM2_a920_internalFault_071 "PASSIVE_SAFETY_ALERT";
BA_ "GenSigSendType" SG_ 1009 RCM2_a920_internalFault_071 7;
BA_ "FieldType" SG_ 1009 RCM2_a921_internalFault_072 "PASSIVE_SAFETY_ALERT";
BA_ "GenSigSendType" SG_ 1009 RCM2_a921_internalFault_072 7;
BA_ "FieldType" SG_ 1009 RCM2_a922_internalFault_073 "PASSIVE_SAFETY_ALERT";
BA_ "GenSigSendType" SG_ 1009 RCM2_a922_internalFault_073 7;
BA_ "FieldType" SG_ 1009 RCM2_a923_internalFault_074 "PASSIVE_SAFETY_ALERT";
BA_ "GenSigSendType" SG_ 1009 RCM2_a923_internalFault_074 7;
BA_ "FieldType" SG_ 1009 RCM2_a924_internalFault_075 "PASSIVE_SAFETY_ALERT";
BA_ "GenSigSendType" SG_ 1009 RCM2_a924_internalFault_075 7;
BA_ "FieldType" SG_ 1009 RCM2_a925_internalFault_076 "PASSIVE_SAFETY_ALERT";
BA_ "GenSigSendType" SG_ 1009 RCM2_a925_internalFault_076 7;
BA_ "FieldType" SG_ 1009 RCM2_a926_internalFault_077 "PASSIVE_SAFETY_ALERT";
BA_ "GenSigSendType" SG_ 1009 RCM2_a926_internalFault_077 7;
BA_ "FieldType" SG_ 1009 RCM2_a927_internalFault_078 "PASSIVE_SAFETY_ALERT";
BA_ "GenSigSendType" SG_ 1009 RCM2_a927_internalFault_078 7;
BA_ "FieldType" SG_ 1009 RCM2_a928_internalFault_079 "PASSIVE_SAFETY_ALERT";
BA_ "GenSigSendType" SG_ 1009 RCM2_a928_internalFault_079 7;
BA_ "FieldType" SG_ 1009 RCM2_a929_internalFault_080 "PASSIVE_SAFETY_ALERT";
BA_ "GenSigSendType" SG_ 1009 RCM2_a929_internalFault_080 7;
BA_ "FieldType" SG_ 1009 RCM2_a930_internalFault_081 "PASSIVE_SAFETY_ALERT";
BA_ "GenSigSendType" SG_ 1009 RCM2_a930_internalFault_081 7;
BA_ "FieldType" SG_ 1009 RCM2_a931_internalFault_082 "PASSIVE_SAFETY_ALERT";
BA_ "GenSigSendType" SG_ 1009 RCM2_a931_internalFault_082 7;
BA_ "FieldType" SG_ 1009 RCM2_a932_internalFault_083 "PASSIVE_SAFETY_ALERT";
BA_ "GenSigSendType" SG_ 1009 RCM2_a932_internalFault_083 7;
BA_ "FieldType" SG_ 1009 RCM2_a933_internalFault_084 "PASSIVE_SAFETY_ALERT";
BA_ "GenSigSendType" SG_ 1009 RCM2_a933_internalFault_084 7;
BA_ "FieldType" SG_ 1009 RCM2_a934_internalFault_085 "PASSIVE_SAFETY_ALERT";
BA_ "GenSigSendType" SG_ 1009 RCM2_a934_internalFault_085 7;
BA_ "FieldType" SG_ 1009 RCM2_a935_internalFault_086 "PASSIVE_SAFETY_ALERT";
BA_ "GenSigSendType" SG_ 1009 RCM2_a935_internalFault_086 7;
BA_ "FieldType" SG_ 1009 RCM2_a936_internalFault_087 "PASSIVE_SAFETY_ALERT";
BA_ "GenSigSendType" SG_ 1009 RCM2_a936_internalFault_087 7;
BA_ "FieldType" SG_ 1009 RCM2_a937_internalFault_088 "PASSIVE_SAFETY_ALERT";
BA_ "GenSigSendType" SG_ 1009 RCM2_a937_internalFault_088 7;
BA_ "FieldType" SG_ 1009 RCM2_a938_internalFault_089 "PASSIVE_SAFETY_ALERT";
BA_ "GenSigSendType" SG_ 1009 RCM2_a938_internalFault_089 7;
BA_ "FieldType" SG_ 1009 RCM2_a939_internalFault_090 "PASSIVE_SAFETY_ALERT";
BA_ "GenSigSendType" SG_ 1009 RCM2_a939_internalFault_090 7;
BA_ "FieldType" SG_ 1009 RCM2_a940_internalFault_091 "PASSIVE_SAFETY_ALERT";
BA_ "GenSigSendType" SG_ 1009 RCM2_a940_internalFault_091 7;
BA_ "FieldType" SG_ 1009 RCM2_a941_internalFault_092 "PASSIVE_SAFETY_ALERT";
BA_ "GenSigSendType" SG_ 1009 RCM2_a941_internalFault_092 7;
BA_ "FieldType" SG_ 1009 RCM2_a942_internalFault_093 "PASSIVE_SAFETY_ALERT";
BA_ "GenSigSendType" SG_ 1009 RCM2_a942_internalFault_093 7;
BA_ "FieldType" SG_ 1009 RCM2_a943_internalFault_094 "PASSIVE_SAFETY_ALERT";
BA_ "GenSigSendType" SG_ 1009 RCM2_a943_internalFault_094 7;
BA_ "FieldType" SG_ 1009 RCM2_a944_internalFault_095 "PASSIVE_SAFETY_ALERT";
BA_ "GenSigSendType" SG_ 1009 RCM2_a944_internalFault_095 7;
BA_ "FieldType" SG_ 1009 RCM2_a945_internalFault_096 "PASSIVE_SAFETY_ALERT";
BA_ "GenSigSendType" SG_ 1009 RCM2_a945_internalFault_096 7;
BA_ "FieldType" SG_ 1009 RCM2_a946_internalFault_097 "PASSIVE_SAFETY_ALERT";
BA_ "GenSigSendType" SG_ 1009 RCM2_a946_internalFault_097 7;
BA_ "FieldType" SG_ 1009 RCM2_a947_internalFault_098 "PASSIVE_SAFETY_ALERT";
BA_ "GenSigSendType" SG_ 1009 RCM2_a947_internalFault_098 7;
BA_ "FieldType" SG_ 1009 RCM2_a948_internalFault_099 "PASSIVE_SAFETY_ALERT";
BA_ "GenSigSendType" SG_ 1009 RCM2_a948_internalFault_099 7;
BA_ "FieldType" SG_ 1009 RCM2_a949_internalFault_100 "PASSIVE_SAFETY_ALERT";
BA_ "GenSigSendType" SG_ 1009 RCM2_a949_internalFault_100 7;
BA_ "FieldType" SG_ 1009 RCM2_a950_internalFault_101 "PASSIVE_SAFETY_ALERT";
BA_ "GenSigSendType" SG_ 1009 RCM2_a950_internalFault_101 7;
BA_ "FieldType" SG_ 1009 RCM2_a951_internalFault_102 "PASSIVE_SAFETY_ALERT";
BA_ "GenSigSendType" SG_ 1009 RCM2_a951_internalFault_102 7;
BA_ "FieldType" SG_ 1009 RCM2_a952_internalFault_103 "PASSIVE_SAFETY_ALERT";
BA_ "GenSigSendType" SG_ 1009 RCM2_a952_internalFault_103 7;
BA_ "FieldType" SG_ 1009 RCM2_a953_internalFault_104 "PASSIVE_SAFETY_ALERT";
BA_ "GenSigSendType" SG_ 1009 RCM2_a953_internalFault_104 7;
BA_ "FieldType" SG_ 1009 RCM2_a954_internalFault_105 "PASSIVE_SAFETY_ALERT";
BA_ "GenSigSendType" SG_ 1009 RCM2_a954_internalFault_105 7;
BA_ "FieldType" SG_ 1009 RCM2_a955_internalFault_106 "PASSIVE_SAFETY_ALERT";
BA_ "GenSigSendType" SG_ 1009 RCM2_a955_internalFault_106 7;
BA_ "FieldType" SG_ 1009 RCM2_a956_internalFault_107 "PASSIVE_SAFETY_ALERT";
BA_ "GenSigSendType" SG_ 1009 RCM2_a956_internalFault_107 7;
BA_ "FieldType" SG_ 1009 RCM2_a957_internalFault_108 "PASSIVE_SAFETY_ALERT";
BA_ "GenSigSendType" SG_ 1009 RCM2_a957_internalFault_108 7;
BA_ "FieldType" SG_ 1009 RCM2_a958_internalFault_109 "PASSIVE_SAFETY_ALERT";
BA_ "GenSigSendType" SG_ 1009 RCM2_a958_internalFault_109 7;
BA_ "FieldType" SG_ 1009 RCM2_a959_internalFault_110 "PASSIVE_SAFETY_ALERT";
BA_ "GenSigSendType" SG_ 1009 RCM2_a959_internalFault_110 7;
BA_ "FieldType" SG_ 1009 RCM2_a960_internalFault_111 "PASSIVE_SAFETY_ALERT";
BA_ "GenSigSendType" SG_ 1009 RCM2_a960_internalFault_111 7;
BA_ "FieldType" SG_ 1009 RCM2_a961_internalFault_112 "PASSIVE_SAFETY_ALERT";
BA_ "GenSigSendType" SG_ 1009 RCM2_a961_internalFault_112 7;
BA_ "FieldType" SG_ 1009 RCM2_a962_internalFault_113 "PASSIVE_SAFETY_ALERT";
BA_ "GenSigSendType" SG_ 1009 RCM2_a962_internalFault_113 7;
BA_ "FieldType" SG_ 1009 RCM2_a963_internalFault_114 "PASSIVE_SAFETY_ALERT";
BA_ "GenSigSendType" SG_ 1009 RCM2_a963_internalFault_114 7;
BA_ "FieldType" SG_ 1009 RCM2_a964_internalFault_115 "PASSIVE_SAFETY_ALERT";
BA_ "GenSigSendType" SG_ 1009 RCM2_a964_internalFault_115 7;
BA_ "FieldType" SG_ 1009 RCM2_a965_internalFault_116 "PASSIVE_SAFETY_ALERT";
BA_ "GenSigSendType" SG_ 1009 RCM2_a965_internalFault_116 7;
BA_ "FieldType" SG_ 1009 RCM2_a966_internalFault_117 "PASSIVE_SAFETY_ALERT";
BA_ "GenSigSendType" SG_ 1009 RCM2_a966_internalFault_117 7;
BA_ "FieldType" SG_ 1009 RCM2_a967_internalFault_118 "PASSIVE_SAFETY_ALERT";
BA_ "GenSigSendType" SG_ 1009 RCM2_a967_internalFault_118 7;
BA_ "FieldType" SG_ 1009 RCM2_a968_internalFault_119 "PASSIVE_SAFETY_ALERT";
BA_ "GenSigSendType" SG_ 1009 RCM2_a968_internalFault_119 7;
BA_ "FieldType" SG_ 1009 RCM2_a969_internalFault_120 "PASSIVE_SAFETY_ALERT";
BA_ "GenSigSendType" SG_ 1009 RCM2_a969_internalFault_120 7;
BA_ "FieldType" SG_ 1009 RCM2_a970_internalFault_121 "PASSIVE_SAFETY_ALERT";
BA_ "GenSigSendType" SG_ 1009 RCM2_a970_internalFault_121 7;
BA_ "FieldType" SG_ 1009 RCM2_a971_internalFault_122 "PASSIVE_SAFETY_ALERT";
BA_ "GenSigSendType" SG_ 1009 RCM2_a971_internalFault_122 7;
BA_ "FieldType" SG_ 1009 RCM2_a972_internalFault_123 "PASSIVE_SAFETY_ALERT";
BA_ "GenSigSendType" SG_ 1009 RCM2_a972_internalFault_123 7;
BA_ "FieldType" SG_ 1009 RCM2_a973_internalFault_124 "PASSIVE_SAFETY_ALERT";
BA_ "GenSigSendType" SG_ 1009 RCM2_a973_internalFault_124 7;
BA_ "FieldType" SG_ 1009 RCM2_a974_internalFault_125 "PASSIVE_SAFETY_ALERT";
BA_ "GenSigSendType" SG_ 1009 RCM2_a974_internalFault_125 7;
BA_ "FieldType" SG_ 1009 RCM2_a975_internalFault_126 "PASSIVE_SAFETY_ALERT";
BA_ "GenSigSendType" SG_ 1009 RCM2_a975_internalFault_126 7;
BA_ "FieldType" SG_ 1009 RCM2_a976_internalFault_127 "PASSIVE_SAFETY_ALERT";
BA_ "GenSigSendType" SG_ 1009 RCM2_a976_internalFault_127 7;
BA_ "FieldType" SG_ 1009 RCM2_a977_internalFault_128 "PASSIVE_SAFETY_ALERT";
BA_ "GenSigSendType" SG_ 1009 RCM2_a977_internalFault_128 7;
BA_ "FieldType" SG_ 1009 RCM2_a978_internalFault_129 "PASSIVE_SAFETY_ALERT";
BA_ "GenSigSendType" SG_ 1009 RCM2_a978_internalFault_129 7;
BA_ "FieldType" SG_ 1009 RCM2_a979_internalFault_130 "PASSIVE_SAFETY_ALERT";
BA_ "GenSigSendType" SG_ 1009 RCM2_a979_internalFault_130 7;
BA_ "FieldType" SG_ 1009 RCM2_a980_internalFault_131 "PASSIVE_SAFETY_ALERT";
BA_ "GenSigSendType" SG_ 1009 RCM2_a980_internalFault_131 7;
BA_ "FieldType" SG_ 1009 RCM2_a981_internalFault_132 "PASSIVE_SAFETY_ALERT";
BA_ "GenSigSendType" SG_ 1009 RCM2_a981_internalFault_132 7;
BA_ "FieldType" SG_ 1009 RCM2_a982_internalFault_133 "PASSIVE_SAFETY_ALERT";
BA_ "GenSigSendType" SG_ 1009 RCM2_a982_internalFault_133 7;
BA_ "FieldType" SG_ 1009 RCM2_a983_internalFault_134 "PASSIVE_SAFETY_ALERT";
BA_ "GenSigSendType" SG_ 1009 RCM2_a983_internalFault_134 7;
BA_ "FieldType" SG_ 1009 RCM2_a984_internalFault_135 "PASSIVE_SAFETY_ALERT";
BA_ "GenSigSendType" SG_ 1009 RCM2_a984_internalFault_135 7;
BA_ "FieldType" SG_ 1009 RCM2_a985_internalFault_136 "PASSIVE_SAFETY_ALERT";
BA_ "GenSigSendType" SG_ 1009 RCM2_a985_internalFault_136 7;
BA_ "FieldType" SG_ 1009 RCM2_a986_internalFault_137 "PASSIVE_SAFETY_ALERT";
BA_ "GenSigSendType" SG_ 1009 RCM2_a986_internalFault_137 7;
BA_ "FieldType" SG_ 1009 RCM2_a987_internalFault_138 "PASSIVE_SAFETY_ALERT";
BA_ "GenSigSendType" SG_ 1009 RCM2_a987_internalFault_138 7;
BA_ "FieldType" SG_ 1009 RCM2_a988_internalFault_139 "PASSIVE_SAFETY_ALERT";
BA_ "GenSigSendType" SG_ 1009 RCM2_a988_internalFault_139 7;
BA_ "FieldType" SG_ 1009 RCM2_a989_internalFault_140 "PASSIVE_SAFETY_ALERT";
BA_ "GenSigSendType" SG_ 1009 RCM2_a989_internalFault_140 7;
BA_ "FieldType" SG_ 1009 RCM2_a990_internalFault_141 "PASSIVE_SAFETY_ALERT";
BA_ "GenSigSendType" SG_ 1009 RCM2_a990_internalFault_141 7;
BA_ "FieldType" SG_ 1009 RCM2_a991_internalFault_142 "PASSIVE_SAFETY_ALERT";
BA_ "GenSigSendType" SG_ 1009 RCM2_a991_internalFault_142 7;
BA_ "FieldType" SG_ 1009 RCM2_a992_internalFault_143 "PASSIVE_SAFETY_ALERT";
BA_ "GenSigSendType" SG_ 1009 RCM2_a992_internalFault_143 7;
BA_ "FieldType" SG_ 1009 RCM2_a993_internalFault_144 "PASSIVE_SAFETY_ALERT";
BA_ "GenSigSendType" SG_ 1009 RCM2_a993_internalFault_144 7;
BA_ "FieldType" SG_ 1009 RCM2_a994_internalFault_145 "PASSIVE_SAFETY_ALERT";
BA_ "GenSigSendType" SG_ 1009 RCM2_a994_internalFault_145 7;
BA_ "LogSignal" SG_ 17 RCM_rearCrash "onChange";
BA_ "LogSignal" SG_ 17 RCM_rightSideCrash "onChange";
BA_ "LogSignal" SG_ 17 RCM_leftSideCrash "onChange";
BA_ "LogSignal" SG_ 17 RCM_frontCrash "onChange";
BA_ "LogSignal" SG_ 17 RCM_chargerCrash "onChange";
BA_ "LogSignal" SG_ 17 RCM_pedProEvent "onChange";
BA_ "LogSignal" SG_ 17 RCM_rollOverCrash "onChange";
BA_ "LogSignal" SG_ 17 RCM_crashSeverity "onChange";
BA_ "FieldType" SG_ 881 RCM_d000_comFault1 "DTC_VALUES";
BA_ "FieldType" SG_ 881 RCM_d001_vBatRange "DTC_VALUES";
BA_ "FieldType" SG_ 881 RCM_d002_vinMismatch "DTC_VALUES";
BA_ "FieldType" SG_ 881 RCM_d003_swVersionMismatch "DTC_VALUES";
BA_ "FieldType" SG_ 881 RCM_d004_idleMode "DTC_VALUES";
BA_ "FieldType" SG_ 881 RCM_d005_internalHard "DTC_VALUES";
BA_ "FieldType" SG_ 881 RCM_d006_crashAlgoDisabled "DTC_VALUES";
BA_ "FieldType" SG_ 881 RCM_d007_eolProgMismatch "DTC_VALUES";
BA_ "FieldType" SG_ 881 RCM_d008_crcErrorExternal "DTC_VALUES";
BA_ "FieldType" SG_ 881 RCM_d009_cfgFault "DTC_VALUES";
BA_ "FieldType" SG_ 881 RCM_d010_crashCalPNMissing "DTC_VALUES";
BA_ "FieldType" SG_ 881 RCM_d011_vdsFieldCalibFailed "DTC_VALUES";
BA_ "FieldType" SG_ 881 RCM_d012_vdsChannelSigMonTmp "DTC_VALUES";
BA_ "FieldType" SG_ 881 RCM_d013_vdsFieldCalibNotDone "DTC_VALUES";
BA_ "FieldType" SG_ 881 RCM_d014_vdsChannelSigMonPerm "DTC_VALUES";
BA_ "FieldType" SG_ 881 RCM_d015_vdsSensorMonitorTemp "DTC_VALUES";
BA_ "FieldType" SG_ 881 RCM_d016_comCANInitFailure "DTC_VALUES";
BA_ "FieldType" SG_ 881 RCM_d017_comGTWCarConfig "DTC_VALUES";
BA_ "FieldType" SG_ 881 RCM_d018_vinEmptyError "DTC_VALUES";
BA_ "FieldType" SG_ 881 RCM_d019_comESPC "DTC_VALUES";
BA_ "FieldType" SG_ 881 RCM_d020_comESP135 "DTC_VALUES";
BA_ "FieldType" SG_ 881 RCM_d021_comEPBStatus "DTC_VALUES";
BA_ "FieldType" SG_ 881 RCM_d022_comBCS2RStatus "DTC_VALUES";
BA_ "FieldType" SG_ 881 RCM_d023_comBCS2LStatus "DTC_VALUES";
BA_ "FieldType" SG_ 881 RCM_d024_comBCS2CStatus "DTC_VALUES";
BA_ "FieldType" SG_ 881 RCM_d025_comTPMSStatus "DTC_VALUES";
BA_ "FieldType" SG_ 881 RCM_d026_airbagWarnMismatch "DTC_VALUES";
BA_ "FieldType" SG_ 881 RCM_d027_ocsFailure "DTC_VALUES";
BA_ "FieldType" SG_ 881 RCM_d028_comGTWACS "DTC_VALUES";
BA_ "FieldType" SG_ 881 RCM_d029_comChassisBusOff "DTC_VALUES";
BA_ "FieldType" SG_ 881 RCM_d030_comStwAngle "DTC_VALUES";
BA_ "FieldType" SG_ 881 RCM_d031_comESP145 "DTC_VALUES";
BA_ "FieldType" SG_ 881 RCM_d032_comDITorque2 "DTC_VALUES";
BA_ "FieldType" SG_ 881 RCM_d033_comDITorque1 "DTC_VALUES";
BA_ "FieldType" SG_ 881 RCM_d034_comESPB "DTC_VALUES";
BA_ "FieldType" SG_ 881 RCM_d035_comGTWOdo "DTC_VALUES";
BA_ "FieldType" SG_ 881 RCM_d036_comBusOff "DTC_VALUES";
BA_ "FieldType" SG_ 881 RCM_d037_comMissingVehConfg "DTC_VALUES";
BA_ "FieldType" SG_ 881 RCM_d038_seatBackSw2ndRowLeft "DTC_VALUES";
BA_ "FieldType" SG_ 881 RCM_d039_pretenLapFrontRight "DTC_VALUES";
BA_ "FieldType" SG_ 881 RCM_d040_pretenLapFrontLeft "DTC_VALUES";
BA_ "FieldType" SG_ 881 RCM_d041_pretenShldFrontRight "DTC_VALUES";
BA_ "FieldType" SG_ 881 RCM_d042_pretenShldrFrontLeft "DTC_VALUES";
BA_ "FieldType" SG_ 881 RCM_d043_passABLampOnHardWire "DTC_VALUES";
BA_ "FieldType" SG_ 881 RCM_d044_pedProCrashDetected "DTC_VALUES";
BA_ "FieldType" SG_ 881 RCM_d045_crashOutSignal "DTC_VALUES";
BA_ "FieldType" SG_ 881 RCM_d046_passengerActiveVent "DTC_VALUES";
BA_ "FieldType" SG_ 881 RCM_d047_kneeABFrontPassenger "DTC_VALUES";
BA_ "FieldType" SG_ 881 RCM_d048_pressureFrontRtDoor "DTC_VALUES";
BA_ "FieldType" SG_ 881 RCM_d049_pressureFrontLftDoor "DTC_VALUES";
BA_ "FieldType" SG_ 881 RCM_d050_eepromDataLocked "DTC_VALUES";
BA_ "FieldType" SG_ 881 RCM_d051_hoodActuatorLeft "DTC_VALUES";
BA_ "FieldType" SG_ 881 RCM_d052_hoodActuatorRight "DTC_VALUES";
BA_ "FieldType" SG_ 881 RCM_d053_sbsw2ndRowRight "DTC_VALUES";
BA_ "FieldType" SG_ 881 RCM_d054_padLampHardWire "DTC_VALUES";
BA_ "FieldType" SG_ 881 RCM_d055_passResOccupancySw "DTC_VALUES";
BA_ "FieldType" SG_ 881 RCM_d056_stpsDriver "DTC_VALUES";
BA_ "FieldType" SG_ 881 RCM_d057_pasDPillarLeftYAxis "DTC_VALUES";
BA_ "FieldType" SG_ 881 RCM_d058_pasDPillarLeftXAxis "DTC_VALUES";
BA_ "FieldType" SG_ 881 RCM_d059_pasDPillarRight "DTC_VALUES";
BA_ "FieldType" SG_ 881 RCM_d060_pasCPillarRight "DTC_VALUES";
BA_ "FieldType" SG_ 881 RCM_d061_pasBPillarRight "DTC_VALUES";
BA_ "FieldType" SG_ 881 RCM_d062_ufsRightSide "DTC_VALUES";
BA_ "FieldType" SG_ 881 RCM_d063_pasCPillarLeft "DTC_VALUES";
BA_ "FieldType" SG_ 881 RCM_d064_pasBPillarLeft "DTC_VALUES";
BA_ "FieldType" SG_ 881 RCM_d065_ufsLeftSide "DTC_VALUES";
BA_ "FieldType" SG_ 881 RCM_d066_loadLimiterRightSide "DTC_VALUES";
BA_ "FieldType" SG_ 881 RCM_d067_loadLimiterLeftSide "DTC_VALUES";
BA_ "FieldType" SG_ 881 RCM_d068_curAB3rdRowRight "DTC_VALUES";
BA_ "FieldType" SG_ 881 RCM_d069_curAB2ndRowRight "DTC_VALUES";
BA_ "FieldType" SG_ 881 RCM_d070_curAB2ndRowLeft "DTC_VALUES";
BA_ "FieldType" SG_ 881 RCM_d071_preten2ndRowRight "DTC_VALUES";
BA_ "FieldType" SG_ 881 RCM_d072_curAB3rdRowLeft "DTC_VALUES";
BA_ "FieldType" SG_ 881 RCM_d073_preten2ndRowLeft "DTC_VALUES";
BA_ "FieldType" SG_ 881 RCM_d074_siAB2ndRowRight "DTC_VALUES";
BA_ "FieldType" SG_ 881 RCM_d075_siAB2ndRowLeft "DTC_VALUES";
BA_ "FieldType" SG_ 881 RCM_d076_hardwarCodingPin3 "DTC_VALUES";
BA_ "FieldType" SG_ 881 RCM_d077_hardwareCodingPin2 "DTC_VALUES";
BA_ "FieldType" SG_ 881 RCM_d078_hardwareCodingPin1 "DTC_VALUES";
BA_ "FieldType" SG_ 881 RCM_d079_buckleRightSide "DTC_VALUES";
BA_ "FieldType" SG_ 881 RCM_d080_buckleLeftSide "DTC_VALUES";
BA_ "FieldType" SG_ 881 RCM_d081_curAB1stRowRight "DTC_VALUES";
BA_ "FieldType" SG_ 881 RCM_d082_siAB1stRowRight "DTC_VALUES";
BA_ "FieldType" SG_ 881 RCM_d083_curAB1stRowLeft "DTC_VALUES";
BA_ "FieldType" SG_ 881 RCM_d084_siAB1stRowLeft "DTC_VALUES";
BA_ "FieldType" SG_ 881 RCM_d085_pabStage2 "DTC_VALUES";
BA_ "FieldType" SG_ 881 RCM_d086_pabStage1 "DTC_VALUES";
BA_ "FieldType" SG_ 881 RCM_d087_hvDisconnect "DTC_VALUES";
BA_ "FieldType" SG_ 881 RCM_d088_kneeABDriver "DTC_VALUES";
BA_ "FieldType" SG_ 881 RCM_d089_dabStage2 "DTC_VALUES";
BA_ "FieldType" SG_ 881 RCM_d090_dabStage1 "DTC_VALUES";
BA_ "FieldType" SG_ 881 RCM_d091_comGTWCarState "DTC_VALUES";
BA_ "FieldType" SG_ 881 RCM_d092_driverOrientation "DTC_VALUES";
BA_ "FieldType" SG_ 881 RCM_d093_scmUnavailable "DTC_VALUES";
BA_ "FieldType" SG_ 881 RCM_d094_comGTWESP1 "DTC_VALUES";
BA_ "FieldType" SG_ 881 RCM_d095_comDasIDF "DTC_VALUES";
BA_ "FieldType" SG_ 881 RCM_d096_comDasStatus "DTC_VALUES";
BA_ "FieldType" SG_ 881 RCM_d097_comDIState "DTC_VALUES";
BA_ "FieldType" SG_ 881 RCM_d098_comDIState2 "DTC_VALUES";
BA_ "FieldType" SG_ 881 RCM_d099_pedProPTSL "DTC_VALUES";
BA_ "FieldType" SG_ 881 RCM_d100_pedProPTSR "DTC_VALUES";
BA_ "FieldType" SG_ 881 RCM_d101_comVCSEATPrest "DTC_VALUES";
BA_ "FieldType" SG_ 881 RCM_d102_comVCSEATDrest "DTC_VALUES";
BA_ "FieldType" SG_ 881 RCM_d103_crashDetected "DTC_VALUES";
BA_ "FieldType" SG_ 881 RCM_d104_nearDeploy "DTC_VALUES";
BA_ "FieldType" SG_ 881 RCM_d105_airbagsNotArmed "DTC_VALUES";
BA_ "FieldType" SG_ 881 RCM_d106_warningIndicator "DTC_VALUES";
BA_ "FieldType" SG_ 881 RCM_d107_pedProCrashDetected "DTC_VALUES";
BA_ "FieldType" SG_ 881 RCM_d108_pedProNearDeploy "DTC_VALUES";
BA_ "FieldType" SG_ 881 RCM_d109_abuseImmunity "DTC_VALUES";
BA_ "FieldType" SG_ 881 RCM_d110_noDeployCrashCal "DTC_VALUES";
BA_ "FieldType" SG_ 881 RCM_d111_noDeployPedProCal "DTC_VALUES";
BA_ "GenSigSNA" SG_ 545 RCM_yawRate "65535";
BA_ "GenSigSNA" SG_ 545 RCM_pitchRate "65535";
BA_ "GenSigSNA" SG_ 545 RCM_rollRate "65535";
BA_ "GenSigStartValue" SG_ 849 RCM_infoIndex 13;
BA_ "GenSigStartValue" SG_ 849 RCM_infoBuildType 255;
BA_ "GenSigStartValue" SG_ 849 RCM_infoComponentID 65535;
BA_ "GenSigStartValue" SG_ 849 RCM_infoPcbaID 255;
BA_ "GenSigStartValue" SG_ 849 RCM_infoAssemblyID 255;
BA_ "GenSigStartValue" SG_ 849 RCM_infoUsageID 65535;
BA_ "GenSigStartValue" SG_ 849 RCM_infoApplicationCRC 4294967295;
BA_ "GenSigStartValue" SG_ 849 RCM_infoBootloaderCRC 4294967295;
BA_ "GenSigStartValue" SG_ 849 RCM_infoVariantCRC 4294967295;
BA_ "LogSignal" SG_ 273 RCM_ndRearCollision "onChange";
BA_ "LogSignal" SG_ 273 RCM_ndRightSideCollision "onChange";
BA_ "LogSignal" SG_ 273 RCM_ndLeftSideCollision "onChange";
BA_ "LogSignal" SG_ 273 RCM_ndFrontCollision "onChange";
BA_ "LogSignal" SG_ 273 RCM_crashAlgoWakeup "onChange";
BA_ "LogSignal" SG_ 273 RCM_ndChargerCollision "onChange";
BA_ "LogSignal" SG_ 273 RCM_ndPedProEvent "onChange";
BA_ "LogSignal" SG_ 273 RCM_ndRollOverCollision "onChange";
BA_ "GenSigSNA" SG_ 529 RCM_driverOrientationInitStatus "7";
BA_ "GenSigStartValue" SG_ 529 RCM_driverOrientationInitStatus 7;
BA_ "LogSignal" SG_ 529 RCM_driverOrientationInitStatus "onChange";
BA_ "GenSigSNA" SG_ 529 RCM_armStatus "3";
BA_ "GenSigStartValue" SG_ 529 RCM_armStatus 3;
BA_ "LogSignal" SG_ 529 RCM_armStatus "onChange";
BA_ "GenSigSNA" SG_ 529 RCM_warningIndicatorState "3";
BA_ "GenSigStartValue" SG_ 529 RCM_warningIndicatorState 3;
BA_ "LogSignal" SG_ 529 RCM_warningIndicatorState "onChange";
BA_ "GenSigSNA" SG_ 529 RCM_tellTalePassengerState "3";
BA_ "GenSigStartValue" SG_ 529 RCM_tellTalePassengerState 3;
BA_ "LogSignal" SG_ 529 RCM_tellTalePassengerState "onChange";
BA_ "GenSigSNA" SG_ 529 RCM_bucklePassengerStatus "3";
BA_ "GenSigStartValue" SG_ 529 RCM_bucklePassengerStatus 3;
BA_ "LogSignal" SG_ 529 RCM_bucklePassengerStatus "onChange";
BA_ "GenSigSNA" SG_ 529 RCM_tellTaleDriverState "3";
BA_ "GenSigStartValue" SG_ 529 RCM_tellTaleDriverState 3;
BA_ "LogSignal" SG_ 529 RCM_tellTaleDriverState "onChange";
BA_ "GenSigSNA" SG_ 529 RCM_buckleDriverStatus "3";
BA_ "GenSigStartValue" SG_ 529 RCM_buckleDriverStatus 3;
BA_ "LogSignal" SG_ 529 RCM_buckleDriverStatus "onChange";
BA_ "GenSigSNA" SG_ 529 RCM_seatTrackPositionPass "3";
BA_ "GenSigStartValue" SG_ 529 RCM_seatTrackPositionPass 3;
BA_ "LogSignal" SG_ 529 RCM_seatTrackPositionPass "onChange";
BA_ "GenSigSNA" SG_ 529 RCM_seatTrackPositionDrvr "3";
BA_ "GenSigStartValue" SG_ 529 RCM_seatTrackPositionDrvr 3;
BA_ "LogSignal" SG_ 529 RCM_seatTrackPositionDrvr "onChange";
BA_ "GenSigSNA" SG_ 529 RCM_passAirbagRequest "3";
BA_ "GenSigStartValue" SG_ 529 RCM_passAirbagRequest 3;
BA_ "LogSignal" SG_ 529 RCM_passAirbagRequest "onChange";
BA_ "GenSigSNA" SG_ 529 RCM_chimeState1stRow "3";
BA_ "GenSigStartValue" SG_ 529 RCM_chimeState1stRow 3;
BA_ "GenSigSNA" SG_ 529 RCM_vinLearnFlag "3";
BA_ "GenSigStartValue" SG_ 529 RCM_vinLearnFlag 3;
BA_ "GenSigSNA" SG_ 529 RCM_hwConfigPin58 "3";
BA_ "GenSigStartValue" SG_ 529 RCM_hwConfigPin58 3;
BA_ "GenSigSNA" SG_ 529 RCM_hwConfigPin57 "3";
BA_ "GenSigStartValue" SG_ 529 RCM_hwConfigPin57 3;
BA_ "GenSigSNA" SG_ 529 RCM_hwConfigPin56 "3";
BA_ "GenSigStartValue" SG_ 529 RCM_hwConfigPin56 3;
BA_ "GenSigSNA" SG_ 529 RCM_passOccupantStatus "3";
BA_ "GenSigStartValue" SG_ 529 RCM_passOccupantStatus 3;
BA_ "GenSigSNA" SG_ 529 RCM_airbagCutoffSwStatus "3";
BA_ "GenSigStartValue" SG_ 529 RCM_airbagCutoffSwStatus 3;
BA_ "LogSignal" SG_ 529 RCM_airbagCutoffSwStatus "onChange";
BA_ "GenSigSNA" SG_ 529 RCM_privateCANStatus "3";
BA_ "GenSigStartValue" SG_ 529 RCM_privateCANStatus 3;
BA_ "GenSigSNA" SG_ 529 RCM_publicCANStatus "3";
BA_ "GenSigStartValue" SG_ 529 RCM_publicCANStatus 3;
BA_ "GenSigSNA" SG_ 529 RCM_pedProEDR2State "3";
BA_ "GenSigStartValue" SG_ 529 RCM_pedProEDR2State 3;
BA_ "LogSignal" SG_ 529 RCM_pedProEDR2State "onChange";
BA_ "GenSigSNA" SG_ 529 RCM_pedProEDR1State "3";
BA_ "GenSigStartValue" SG_ 529 RCM_pedProEDR1State 3;
BA_ "LogSignal" SG_ 529 RCM_pedProEDR1State "onChange";
BA_ "GenSigSNA" SG_ 529 RCM_edr2State "3";
BA_ "GenSigStartValue" SG_ 529 RCM_edr2State 3;
BA_ "LogSignal" SG_ 529 RCM_edr2State "onChange";
BA_ "GenSigSNA" SG_ 529 RCM_edr1State "3";
BA_ "GenSigStartValue" SG_ 529 RCM_edr1State 3;
BA_ "LogSignal" SG_ 529 RCM_edr1State "onChange";
BA_ "GenSigSNA" SG_ 529 RCM_buckle2ndRowStatus "7";
BA_ "GenSigStartValue" SG_ 529 RCM_buckle2ndRowStatus 7;
BA_ "LogSignal" SG_ 529 RCM_buckle2ndRowStatus "onChange";
BA_ "GenSigSendType" SG_ 2041 RCM_udsDisposalResponseData 7;
BA_ "FlexKomComment" SG_ 109 StW_Sw_Stat3 "Shift by Wire request";
BA_ "FlexKomIsMotorola" SG_ 109 StW_Sw_Stat3 1;
BA_ "FlexKomSID" SG_ 109 StW_Sw_Stat3 117441584;
BA_ "FlexKomSigLaenge" SG_ 109 StW_Sw_Stat3 32;
BA_ "FlexKomSigName" SG_ 109 StW_Sw_Stat3 "SBW_Rq_SCCM";
BA_ "FlexKomSigStartPos" SG_ 109 StW_Sw_Stat3 7;
BA_ "FlexKomSigStartValue" SG_ 109 StW_Sw_Stat3 "00E600FFh";
BA_ "GenSigCycleTime" SG_ 109 StW_Sw_Stat3 10;
BA_ "GenSigSNA" SG_ 109 StW_Sw_Stat3 "7";
BA_ "FlexKomComment" SG_ 109 MsgTxmtId "Shift by Wire request";
BA_ "FlexKomIsMotorola" SG_ 109 MsgTxmtId 1;
BA_ "FlexKomSID" SG_ 109 MsgTxmtId 117441584;
BA_ "FlexKomSigLaenge" SG_ 109 MsgTxmtId 32;
BA_ "FlexKomSigName" SG_ 109 MsgTxmtId "SBW_Rq_SCCM";
BA_ "FlexKomSigStartPos" SG_ 109 MsgTxmtId 7;
BA_ "FlexKomSigStartValue" SG_ 109 MsgTxmtId "00E600FFh";
BA_ "GenSigCycleTime" SG_ 109 MsgTxmtId 10;
BA_ "FlexKomComment" SG_ 109 TSL_RND_Posn_StW "Shift by Wire request";
BA_ "FlexKomIsMotorola" SG_ 109 TSL_RND_Posn_StW 1;
BA_ "FlexKomSID" SG_ 109 TSL_RND_Posn_StW 117441584;
BA_ "FlexKomSigLaenge" SG_ 109 TSL_RND_Posn_StW 32;
BA_ "FlexKomSigName" SG_ 109 TSL_RND_Posn_StW "SBW_Rq_SCCM";
BA_ "FlexKomSigStartPos" SG_ 109 TSL_RND_Posn_StW 7;
BA_ "FlexKomSigStartValue" SG_ 109 TSL_RND_Posn_StW "00E600FFh";
BA_ "GenSigCycleTime" SG_ 109 TSL_RND_Posn_StW 10;
BA_ "GenSigSNA" SG_ 109 TSL_RND_Posn_StW "15";
BA_ "GenSigStartValue" SG_ 109 TSL_RND_Posn_StW 6;
BA_ "LogSignal" SG_ 109 TSL_RND_Posn_StW "onChange";
BA_ "FlexKomComment" SG_ 109 TSL_P_Psd_StW "Shift by Wire request";
BA_ "FlexKomIsMotorola" SG_ 109 TSL_P_Psd_StW 1;
BA_ "FlexKomSID" SG_ 109 TSL_P_Psd_StW 117441584;
BA_ "FlexKomSigLaenge" SG_ 109 TSL_P_Psd_StW 32;
BA_ "FlexKomSigName" SG_ 109 TSL_P_Psd_StW "SBW_Rq_SCCM";
BA_ "FlexKomSigStartPos" SG_ 109 TSL_P_Psd_StW 7;
BA_ "FlexKomSigStartValue" SG_ 109 TSL_P_Psd_StW "00E600FFh";
BA_ "GenSigCycleTime" SG_ 109 TSL_P_Psd_StW 10;
BA_ "GenSigSNA" SG_ 109 TSL_P_Psd_StW "3";
BA_ "GenSigStartValue" SG_ 109 TSL_P_Psd_StW 2;
BA_ "LogSignal" SG_ 109 TSL_P_Psd_StW "onChange";
BA_ "FlexKomComment" SG_ 109 MC_SBW_RQ_SCCM "Shift by Wire request";
BA_ "FlexKomIsMotorola" SG_ 109 MC_SBW_RQ_SCCM 1;
BA_ "FlexKomSID" SG_ 109 MC_SBW_RQ_SCCM 117441584;
BA_ "FlexKomSigLaenge" SG_ 109 MC_SBW_RQ_SCCM 32;
BA_ "FlexKomSigName" SG_ 109 MC_SBW_RQ_SCCM "SBW_Rq_SCCM";
BA_ "FlexKomSigStartPos" SG_ 109 MC_SBW_RQ_SCCM 7;
BA_ "FlexKomSigStartValue" SG_ 109 MC_SBW_RQ_SCCM "00E600FFh";
BA_ "GenSigCycleTime" SG_ 109 MC_SBW_RQ_SCCM 10;
BA_ "GenSigSNA" SG_ 109 MC_SBW_RQ_SCCM "0h";
BA_ "FlexKomComment" SG_ 109 CRC_SBW_RQ_SCCM "Shift by Wire request";
BA_ "FlexKomIsMotorola" SG_ 109 CRC_SBW_RQ_SCCM 1;
BA_ "FlexKomSID" SG_ 109 CRC_SBW_RQ_SCCM 117441584;
BA_ "FlexKomSigLaenge" SG_ 109 CRC_SBW_RQ_SCCM 32;
BA_ "FlexKomSigName" SG_ 109 CRC_SBW_RQ_SCCM "SBW_Rq_SCCM";
BA_ "FlexKomSigStartPos" SG_ 109 CRC_SBW_RQ_SCCM 7;
BA_ "FlexKomSigStartValue" SG_ 109 CRC_SBW_RQ_SCCM "00E600FFh";
BA_ "GenSigCycleTime" SG_ 109 CRC_SBW_RQ_SCCM 10;
BA_ "GenSigSNA" SG_ 109 CRC_SBW_RQ_SCCM "FFh";
BA_ "GenSigStartValue" SG_ 109 CRC_SBW_RQ_SCCM 255;
BA_ "FlexKomComment" SG_ 815 StW_Temp "Steering wheel temperature sensor state";
BA_ "FlexKomIsMotorola" SG_ 815 StW_Temp 1;
BA_ "FlexKomSID" SG_ 815 StW_Temp 117443705;
BA_ "FlexKomSigLaenge" SG_ 815 StW_Temp 16;
BA_ "FlexKomSigName" SG_ 815 StW_Temp "StW_TempSens_Stat";
BA_ "FlexKomSigStartPos" SG_ 815 StW_Temp 7;
BA_ "FlexKomSigStartValue" SG_ 815 StW_Temp "FF03h";
BA_ "GenSigSNA" SG_ 815 StW_Temp "255";
BA_ "GenSigSendType" SG_ 815 StW_Temp 10;
BA_ "GenSigStartValue" SG_ 815 StW_Temp 255;
BA_ "GenSigTimeout_CGW" SG_ 815 StW_Temp 1050;
BA_ "FlexKomComment" SG_ 815 StW_TempSens_Flt "Steering wheel temperature sensor state";
BA_ "FlexKomIsMotorola" SG_ 815 StW_TempSens_Flt 1;
BA_ "FlexKomSID" SG_ 815 StW_TempSens_Flt 117443705;
BA_ "FlexKomSigLaenge" SG_ 815 StW_TempSens_Flt 16;
BA_ "FlexKomSigName" SG_ 815 StW_TempSens_Flt "StW_TempSens_Stat";
BA_ "FlexKomSigStartPos" SG_ 815 StW_TempSens_Flt 7;
BA_ "FlexKomSigStartValue" SG_ 815 StW_TempSens_Flt "FF03h";
BA_ "GenSigCycleTime" SG_ 815 StW_TempSens_Flt 100;
BA_ "GenSigSNA" SG_ 815 StW_TempSens_Flt "3";
BA_ "GenSigSendType" SG_ 815 StW_TempSens_Flt 5;
BA_ "GenSigStartValue" SG_ 815 StW_TempSens_Flt 3;
BA_ "GenSigTimeout_CGW" SG_ 815 StW_TempSens_Flt 1050;
BA_ "FlexKomComment" SG_ 815 ALDW_VibMot_Stat "ALDW vibration motor";
BA_ "FlexKomIsMotorola" SG_ 815 ALDW_VibMot_Stat 1;
BA_ "FlexKomSID" SG_ 815 ALDW_VibMot_Stat 117443737;
BA_ "FlexKomSigLaenge" SG_ 815 ALDW_VibMot_Stat 4;
BA_ "FlexKomSigName" SG_ 815 ALDW_VibMot_Stat "ALDW_VibMot";
BA_ "FlexKomSigStartPos" SG_ 815 ALDW_VibMot_Stat 19;
BA_ "FlexKomSigStartValue" SG_ 815 ALDW_VibMot_Stat "07h";
BA_ "GenSigCycleTime" SG_ 815 ALDW_VibMot_Stat 100;
BA_ "GenSigSNA" SG_ 815 ALDW_VibMot_Stat "7";
BA_ "GenSigSendType" SG_ 815 ALDW_VibMot_Stat 5;
BA_ "GenSigStartValue" SG_ 815 ALDW_VibMot_Stat 7;
BA_ "GenSigTimeout_MPC" SG_ 815 ALDW_VibMot_Stat 1050;
BA_ "GenSigTimeout_RDU" SG_ 815 ALDW_VibMot_Stat 1050;
BA_ "FlexKomComment" SG_ 815 ALDW_VibMot_Avl "ALDW vibration motor";
BA_ "FlexKomIsMotorola" SG_ 815 ALDW_VibMot_Avl 1;
BA_ "FlexKomSID" SG_ 815 ALDW_VibMot_Avl 117443737;
BA_ "FlexKomSigLaenge" SG_ 815 ALDW_VibMot_Avl 4;
BA_ "FlexKomSigName" SG_ 815 ALDW_VibMot_Avl "ALDW_VibMot";
BA_ "FlexKomSigStartPos" SG_ 815 ALDW_VibMot_Avl 19;
BA_ "FlexKomSigStartValue" SG_ 815 ALDW_VibMot_Avl "07h";
BA_ "GenSigCycleTime" SG_ 815 ALDW_VibMot_Avl 100;
BA_ "GenSigSendType" SG_ 815 ALDW_VibMot_Avl 5;
BA_ "GenSigTimeout_MPC" SG_ 815 ALDW_VibMot_Avl 1050;
BA_ "FlexKomComment" SG_ 1944 SCCM_udsResponseData "ECU to external application";
BA_ "FlexKomIsMotorola" SG_ 1944 SCCM_udsResponseData 1;
BA_ "FlexKomSID" SG_ 1944 SCCM_udsResponseData 117450570;
BA_ "FlexKomSigLaenge" SG_ 1944 SCCM_udsResponseData 64;
BA_ "FlexKomSigName" SG_ 1944 SCCM_udsResponseData "SG_APPL_SCCM2";
BA_ "FlexKomSigStartPos" SG_ 1944 SCCM_udsResponseData 7;
BA_ "FlexKomSigStartValue" SG_ 1944 SCCM_udsResponseData "0000000000000000h";
BA_ "GenSigSendType" SG_ 1944 SCCM_udsResponseData 1;
BA_ "GenSigSNA" SG_ 638 DDM_driverFrontPresentReq "3";
BA_ "GenSigSNA" SG_ 638 SC_keyfobButton1 "3";
BA_ "GenSigSNA" SG_ 638 DDM_driverRearPresentReq "3";
BA_ "GenSigSNA" SG_ 638 SC_keyfobButton2 "3";
BA_ "GenSigSNA" SG_ 638 PDM_passFrontPresentReq "3";
BA_ "GenSigSNA" SG_ 638 SC_keyfobButton3 "3";
BA_ "GenSigSNA" SG_ 638 PDM_passRearPresentReq "3";
VAL_ 1009 RCM2_a567_seaTrkPosLeftConfig 1 "RCM2_ALERT_SET" 0 "RCM2_ALERT_CLEARED" ;
VAL_ 1009 RCM2_a568_occPROSSht2Gnd 1 "RCM2_ALERT_SET" 0 "RCM2_ALERT_CLEARED" ;
VAL_ 1009 RCM2_a569_occPROSSht2Bat 1 "RCM2_ALERT_SET" 0 "RCM2_ALERT_CLEARED" ;
VAL_ 1009 RCM2_a570_occPROSOpen 1 "RCM2_ALERT_SET" 0 "RCM2_ALERT_CLEARED" ;
VAL_ 1009 RCM2_a571_occPROSUndef 1 "RCM2_ALERT_SET" 0 "RCM2_ALERT_CLEARED" ;
VAL_ 1009 RCM2_a572_occPROSCrssCoup 1 "RCM2_ALERT_SET" 0 "RCM2_ALERT_CLEARED" ;
VAL_ 1009 RCM2_a573_occPROSConfig 1 "RCM2_ALERT_SET" 0 "RCM2_ALERT_CLEARED" ;
VAL_ 1009 RCM2_a587_sbrRearNetSht2Gnd 1 "RCM2_ALERT_SET" 0 "RCM2_ALERT_CLEARED" ;
VAL_ 1009 RCM2_a588_sbrRearNetSht2Bat 1 "RCM2_ALERT_SET" 0 "RCM2_ALERT_CLEARED" ;
VAL_ 1009 RCM2_a589_sbrRearNetOpen 1 "RCM2_ALERT_SET" 0 "RCM2_ALERT_CLEARED" ;
VAL_ 1009 RCM2_a590_sbrRearNetUndefined 1 "RCM2_ALERT_SET" 0 "RCM2_ALERT_CLEARED" ;
VAL_ 1009 RCM2_a591_sbrRearNetCrssCoup 1 "RCM2_ALERT_SET" 0 "RCM2_ALERT_CLEARED" ;
VAL_ 1009 RCM2_a592_sbrRearNetConfig 1 "RCM2_ALERT_SET" 0 "RCM2_ALERT_CLEARED" ;
VAL_ 1009 RCM2_a593_driveOrientaSht2Gnd 1 "RCM2_ALERT_SET" 0 "RCM2_ALERT_CLEARED" ;
VAL_ 1009 RCM2_a594_driveOrientaSht2Bat 1 "RCM2_ALERT_SET" 0 "RCM2_ALERT_CLEARED" ;
VAL_ 1009 RCM2_a595_driveOrientaOpen 1 "RCM2_ALERT_SET" 0 "RCM2_ALERT_CLEARED" ;
VAL_ 1009 RCM2_a596_driveOrientaUndefined 1 "RCM2_ALERT_SET" 0 "RCM2_ALERT_CLEARED" ;
VAL_ 1009 RCM2_a597_driveOrientaCrssCoup 1 "RCM2_ALERT_SET" 0 "RCM2_ALERT_CLEARED" ;
VAL_ 1009 RCM2_a598_driveOrientaConfig 1 "RCM2_ALERT_SET" 0 "RCM2_ALERT_CLEARED" ;
VAL_ 1009 RCM2_a600_comCANinternalTimeout 1 "RCM2_ALERT_SET" 0 "RCM2_ALERT_CLEARED" ;
VAL_ 1009 RCM2_a601_comChassisCANInit 1 "RCM2_ALERT_SET" 0 "RCM2_ALERT_CLEARED" ;
VAL_ 1009 RCM2_a602_comChassisCANBusOff 1 "RCM2_ALERT_SET" 0 "RCM2_ALERT_CLEARED" ;
VAL_ 1009 RCM2_a603_comPARTYCANInit 1 "RCM2_ALERT_SET" 0 "RCM2_ALERT_CLEARED" ;
VAL_ 1009 RCM2_a604_comPARTYCANBusOff 1 "RCM2_ALERT_SET" 0 "RCM2_ALERT_CLEARED" ;
VAL_ 1009 RCM2_a605_comStwAngStatMIA 1 "RCM2_ALERT_SET" 0 "RCM2_ALERT_CLEARED" ;
VAL_ 1009 RCM2_a606_comStwAngStatChkSm 1 "RCM2_ALERT_SET" 0 "RCM2_ALERT_CLEARED" ;
VAL_ 1009 RCM2_a607_comStwAngStatCntr 1 "RCM2_ALERT_SET" 0 "RCM2_ALERT_CLEARED" ;
VAL_ 1009 RCM2_a608_comDItorque1MIA 1 "RCM2_ALERT_SET" 0 "RCM2_ALERT_CLEARED" ;
VAL_ 1009 RCM2_a609_comDItorque1ChkSm 1 "RCM2_ALERT_SET" 0 "RCM2_ALERT_CLEARED" ;
VAL_ 1009 RCM2_a610_comDItorque1Cntr 1 "RCM2_ALERT_SET" 0 "RCM2_ALERT_CLEARED" ;
VAL_ 1009 RCM2_a611_comDItorque2MIA 1 "RCM2_ALERT_SET" 0 "RCM2_ALERT_CLEARED" ;
VAL_ 1009 RCM2_a612_comDItorque2ChkSm 1 "RCM2_ALERT_SET" 0 "RCM2_ALERT_CLEARED" ;
VAL_ 1009 RCM2_a613_comDItorque2Cntr 1 "RCM2_ALERT_SET" 0 "RCM2_ALERT_CLEARED" ;
VAL_ 1009 RCM2_a614_comESP135MIA 1 "RCM2_ALERT_SET" 0 "RCM2_ALERT_CLEARED" ;
VAL_ 1009 RCM2_a615_comESP135ChkSm 1 "RCM2_ALERT_SET" 0 "RCM2_ALERT_CLEARED" ;
VAL_ 1009 RCM2_a616_comESP135Cntr 1 "RCM2_ALERT_SET" 0 "RCM2_ALERT_CLEARED" ;
VAL_ 1009 RCM2_a617_comESP145MIA 1 "RCM2_ALERT_SET" 0 "RCM2_ALERT_CLEARED" ;
VAL_ 1009 RCM2_a618_comESP145ChkSm 1 "RCM2_ALERT_SET" 0 "RCM2_ALERT_CLEARED" ;
VAL_ 1009 RCM2_a619_comESP145Cntr 1 "RCM2_ALERT_SET" 0 "RCM2_ALERT_CLEARED" ;
VAL_ 1009 RCM2_a620_comInvalidVehicleSpeed 1 "RCM2_ALERT_SET" 0 "RCM2_ALERT_CLEARED" ;
VAL_ 1009 RCM2_a621_comESPBMIA 1 "RCM2_ALERT_SET" 0 "RCM2_ALERT_CLEARED" ;
VAL_ 1009 RCM2_a622_comESPBChkSm 1 "RCM2_ALERT_SET" 0 "RCM2_ALERT_CLEARED" ;
VAL_ 1009 RCM2_a623_comESPBCntr 1 "RCM2_ALERT_SET" 0 "RCM2_ALERT_CLEARED" ;
VAL_ 1009 RCM2_a624_comESPCMIA 1 "RCM2_ALERT_SET" 0 "RCM2_ALERT_CLEARED" ;
VAL_ 1009 RCM2_a625_comESPCChkSm 1 "RCM2_ALERT_SET" 0 "RCM2_ALERT_CLEARED" ;
VAL_ 1009 RCM2_a626_comESPCCntr 1 "RCM2_ALERT_SET" 0 "RCM2_ALERT_CLEARED" ;
VAL_ 1009 RCM2_a627_comEPBStatusMIA 1 "RCM2_ALERT_SET" 0 "RCM2_ALERT_CLEARED" ;
VAL_ 1009 RCM2_a628_comEPBStatusChkSm 1 "RCM2_ALERT_SET" 0 "RCM2_ALERT_CLEARED" ;
VAL_ 1009 RCM2_a629_comEPBStatusCntr 1 "RCM2_ALERT_SET" 0 "RCM2_ALERT_CLEARED" ;
VAL_ 1009 RCM2_a630_comGTWACSMIA 1 "RCM2_ALERT_SET" 0 "RCM2_ALERT_CLEARED" ;
VAL_ 1009 RCM2_a631_comGTWACSChkSm 1 "RCM2_ALERT_SET" 0 "RCM2_ALERT_CLEARED" ;
VAL_ 1009 RCM2_a632_comGTWACSCntr 1 "RCM2_ALERT_SET" 0 "RCM2_ALERT_CLEARED" ;
VAL_ 1009 RCM2_a633_comOCS1PMIA 1 "RCM2_ALERT_SET" 0 "RCM2_ALERT_CLEARED" ;
VAL_ 1009 RCM2_a634_comOCS1PChkSm 1 "RCM2_ALERT_SET" 0 "RCM2_ALERT_CLEARED" ;
VAL_ 1009 RCM2_a635_comOCS1PCntr 1 "RCM2_ALERT_SET" 0 "RCM2_ALERT_CLEARED" ;
VAL_ 1009 RCM2_a636_ocsFaulted 1 "RCM2_ALERT_SET" 0 "RCM2_ALERT_CLEARED" ;
VAL_ 1009 RCM2_a637_ocsUnknown 1 "RCM2_ALERT_SET" 0 "RCM2_ALERT_CLEARED" ;
VAL_ 1009 RCM2_a638_comGTWodoMIA 1 "RCM2_ALERT_SET" 0 "RCM2_ALERT_CLEARED" ;
VAL_ 1009 RCM2_a639_comGTWCarStateMIA 1 "RCM2_ALERT_SET" 0 "RCM2_ALERT_CLEARED" ;
VAL_ 1009 RCM2_a640_comTPMSStatusCMIA 1 "RCM2_ALERT_SET" 0 "RCM2_ALERT_CLEARED" ;
VAL_ 1009 RCM2_a641_comGTWCarConfigMIA 1 "RCM2_ALERT_SET" 0 "RCM2_ALERT_CLEARED" ;
VAL_ 1009 RCM2_a642_comVINmessageMIA 1 "RCM2_ALERT_SET" 0 "RCM2_ALERT_CLEARED" ;
VAL_ 1009 RCM2_a643_comDASSafetyFrntMIA 1 "RCM2_ALERT_SET" 0 "RCM2_ALERT_CLEARED" ;
VAL_ 1009 RCM2_a644_comDASSafetyFrntChkSm 1 "RCM2_ALERT_SET" 0 "RCM2_ALERT_CLEARED" ;
VAL_ 1009 RCM2_a645_comDASSafetyFrntCntr 1 "RCM2_ALERT_SET" 0 "RCM2_ALERT_CLEARED" ;
VAL_ 1009 RCM2_a646_comDIstateMIA 1 "RCM2_ALERT_SET" 0 "RCM2_ALERT_CLEARED" ;
VAL_ 1009 RCM2_a647_comDIstateChkSm 1 "RCM2_ALERT_SET" 0 "RCM2_ALERT_CLEARED" ;
VAL_ 1009 RCM2_a648_comDIstateCntr 1 "RCM2_ALERT_SET" 0 "RCM2_ALERT_CLEARED" ;
VAL_ 1009 RCM2_a649_comDIstate2MIA 1 "RCM2_ALERT_SET" 0 "RCM2_ALERT_CLEARED" ;
VAL_ 1009 RCM2_a650_comDIstate2ChkSm 1 "RCM2_ALERT_SET" 0 "RCM2_ALERT_CLEARED" ;
VAL_ 1009 RCM2_a651_comDIstate2Cntr 1 "RCM2_ALERT_SET" 0 "RCM2_ALERT_CLEARED" ;
VAL_ 1009 RCM2_a652_ambientTempFaulted 1 "RCM2_ALERT_SET" 0 "RCM2_ALERT_CLEARED" ;
VAL_ 1009 RCM2_a653_comGTWESP1MIA 1 "RCM2_ALERT_SET" 0 "RCM2_ALERT_CLEARED" ;
VAL_ 1009 RCM2_a654_comGTWESP1ChkSm 1 "RCM2_ALERT_SET" 0 "RCM2_ALERT_CLEARED" ;
VAL_ 1009 RCM2_a655_comGTWESP1Cntr 1 "RCM2_ALERT_SET" 0 "RCM2_ALERT_CLEARED" ;
VAL_ 1009 RCM2_a750_linInternalTimeout 1 "RCM2_ALERT_SET" 0 "RCM2_ALERT_CLEARED" ;
VAL_ 1009 RCM2_a800_cfgMissingCalibration 1 "RCM2_ALERT_SET" 0 "RCM2_ALERT_CLEARED" ;
VAL_ 1009 RCM2_a801_cfgImplausConfig 1 "RCM2_ALERT_SET" 0 "RCM2_ALERT_CLEARED" ;
VAL_ 1009 RCM2_a802_cfgInvalidConfig 1 "RCM2_ALERT_SET" 0 "RCM2_ALERT_CLEARED" ;
VAL_ 1009 RCM2_a803_cfgNotConfigured 1 "RCM2_ALERT_SET" 0 "RCM2_ALERT_CLEARED" ;
VAL_ 1009 RCM2_a804_cfgNotProgrammed 1 "RCM2_ALERT_SET" 0 "RCM2_ALERT_CLEARED" ;
VAL_ 1009 RCM2_a805_cfgPedProNotProgrammed 1 "RCM2_ALERT_SET" 0 "RCM2_ALERT_CLEARED" ;
VAL_ 1009 RCM2_a806_cfgCrashCalPNmissing 1 "RCM2_ALERT_SET" 0 "RCM2_ALERT_CLEARED" ;
VAL_ 1009 RCM2_a807_cfgExternalCRCError 1 "RCM2_ALERT_SET" 0 "RCM2_ALERT_CLEARED" ;
VAL_ 1009 RCM2_a808_cfgInvalParamLayoutID 1 "RCM2_ALERT_SET" 0 "RCM2_ALERT_CLEARED" ;
VAL_ 1009 RCM2_a809_cfgInvalParamTransID 1 "RCM2_ALERT_SET" 0 "RCM2_ALERT_CLEARED" ;
VAL_ 1009 RCM2_a810_cfgAlgoVerifySnsrID 1 "RCM2_ALERT_SET" 0 "RCM2_ALERT_CLEARED" ;
VAL_ 1009 RCM2_a811_cfgConfigDataInconsist 1 "RCM2_ALERT_SET" 0 "RCM2_ALERT_CLEARED" ;
VAL_ 1009 RCM2_a812_swVersionWrong 1 "RCM2_ALERT_SET" 0 "RCM2_ALERT_CLEARED" ;
VAL_ 1009 RCM2_a813_vinNotProgrammed 1 "RCM2_ALERT_SET" 0 "RCM2_ALERT_CLEARED" ;
VAL_ 1009 RCM2_a814_vinMismatch 1 "RCM2_ALERT_SET" 0 "RCM2_ALERT_CLEARED" ;
VAL_ 1009 RCM2_a815_driveLeaningNotDone 1 "RCM2_ALERT_SET" 0 "RCM2_ALERT_CLEARED" ;
VAL_ 1009 RCM2_a816_driveLeaningMismatch 1 "RCM2_ALERT_SET" 0 "RCM2_ALERT_CLEARED" ;
VAL_ 1009 RCM2_a817_bootActionsFailed 1 "RCM2_ALERT_SET" 0 "RCM2_ALERT_CLEARED" ;
VAL_ 1009 RCM2_a850_internalFault_001 1 "RCM2_ALERT_SET" 0 "RCM2_ALERT_CLEARED" ;
VAL_ 1009 RCM2_a851_internalFault_002 1 "RCM2_ALERT_SET" 0 "RCM2_ALERT_CLEARED" ;
VAL_ 1009 RCM2_a852_internalFault_003 1 "RCM2_ALERT_SET" 0 "RCM2_ALERT_CLEARED" ;
VAL_ 1009 RCM2_a853_internalFault_004 1 "RCM2_ALERT_SET" 0 "RCM2_ALERT_CLEARED" ;
VAL_ 1009 RCM2_a854_internalFault_005 1 "RCM2_ALERT_SET" 0 "RCM2_ALERT_CLEARED" ;
VAL_ 1009 RCM2_a855_internalFault_006 1 "RCM2_ALERT_SET" 0 "RCM2_ALERT_CLEARED" ;
VAL_ 1009 RCM2_a856_internalFault_007 1 "RCM2_ALERT_SET" 0 "RCM2_ALERT_CLEARED" ;
VAL_ 1009 RCM2_a857_internalFault_008 1 "RCM2_ALERT_SET" 0 "RCM2_ALERT_CLEARED" ;
VAL_ 1009 RCM2_a858_internalFault_009 1 "RCM2_ALERT_SET" 0 "RCM2_ALERT_CLEARED" ;
VAL_ 1009 RCM2_a859_internalFault_010 1 "RCM2_ALERT_SET" 0 "RCM2_ALERT_CLEARED" ;
VAL_ 1009 RCM2_a860_internalFault_011 1 "RCM2_ALERT_SET" 0 "RCM2_ALERT_CLEARED" ;
VAL_ 1009 RCM2_a861_internalFault_012 1 "RCM2_ALERT_SET" 0 "RCM2_ALERT_CLEARED" ;
VAL_ 1009 RCM2_a862_internalFault_013 1 "RCM2_ALERT_SET" 0 "RCM2_ALERT_CLEARED" ;
VAL_ 1009 RCM2_a863_internalFault_014 1 "RCM2_ALERT_SET" 0 "RCM2_ALERT_CLEARED" ;
VAL_ 1009 RCM2_a864_internalFault_015 1 "RCM2_ALERT_SET" 0 "RCM2_ALERT_CLEARED" ;
VAL_ 1009 RCM2_a865_internalFault_016 1 "RCM2_ALERT_SET" 0 "RCM2_ALERT_CLEARED" ;
VAL_ 1009 RCM2_a866_internalFault_017 1 "RCM2_ALERT_SET" 0 "RCM2_ALERT_CLEARED" ;
VAL_ 1009 RCM2_a867_internalFault_018 1 "RCM2_ALERT_SET" 0 "RCM2_ALERT_CLEARED" ;
VAL_ 1009 RCM2_a868_internalFault_019 1 "RCM2_ALERT_SET" 0 "RCM2_ALERT_CLEARED" ;
VAL_ 1009 RCM2_a869_internalFault_020 1 "RCM2_ALERT_SET" 0 "RCM2_ALERT_CLEARED" ;
VAL_ 1009 RCM2_a870_internalFault_021 1 "RCM2_ALERT_SET" 0 "RCM2_ALERT_CLEARED" ;
VAL_ 1009 RCM2_a871_internalFault_022 1 "RCM2_ALERT_SET" 0 "RCM2_ALERT_CLEARED" ;
VAL_ 1009 RCM2_a872_internalFault_023 1 "RCM2_ALERT_SET" 0 "RCM2_ALERT_CLEARED" ;
VAL_ 1009 RCM2_a873_internalFault_024 1 "RCM2_ALERT_SET" 0 "RCM2_ALERT_CLEARED" ;
VAL_ 1009 RCM2_a874_internalFault_025 1 "RCM2_ALERT_SET" 0 "RCM2_ALERT_CLEARED" ;
VAL_ 1009 RCM2_a875_internalFault_026 1 "RCM2_ALERT_SET" 0 "RCM2_ALERT_CLEARED" ;
VAL_ 1009 RCM2_a876_internalFault_027 1 "RCM2_ALERT_SET" 0 "RCM2_ALERT_CLEARED" ;
VAL_ 1009 RCM2_a877_internalFault_028 1 "RCM2_ALERT_SET" 0 "RCM2_ALERT_CLEARED" ;
VAL_ 1009 RCM2_a878_internalFault_029 1 "RCM2_ALERT_SET" 0 "RCM2_ALERT_CLEARED" ;
VAL_ 1009 RCM2_a879_internalFault_030 1 "RCM2_ALERT_SET" 0 "RCM2_ALERT_CLEARED" ;
VAL_ 1009 RCM2_a880_internalFault_031 1 "RCM2_ALERT_SET" 0 "RCM2_ALERT_CLEARED" ;
VAL_ 1009 RCM2_a881_internalFault_032 1 "RCM2_ALERT_SET" 0 "RCM2_ALERT_CLEARED" ;
VAL_ 1009 RCM2_a882_internalFault_033 1 "RCM2_ALERT_SET" 0 "RCM2_ALERT_CLEARED" ;
VAL_ 1009 RCM2_a883_internalFault_034 1 "RCM2_ALERT_SET" 0 "RCM2_ALERT_CLEARED" ;
VAL_ 1009 RCM2_a884_internalFault_035 1 "RCM2_ALERT_SET" 0 "RCM2_ALERT_CLEARED" ;
VAL_ 1009 RCM2_a885_internalFault_036 1 "RCM2_ALERT_SET" 0 "RCM2_ALERT_CLEARED" ;
VAL_ 1009 RCM2_a886_internalFault_037 1 "RCM2_ALERT_SET" 0 "RCM2_ALERT_CLEARED" ;
VAL_ 1009 RCM2_a887_internalFault_038 1 "RCM2_ALERT_SET" 0 "RCM2_ALERT_CLEARED" ;
VAL_ 1009 RCM2_a888_internalFault_039 1 "RCM2_ALERT_SET" 0 "RCM2_ALERT_CLEARED" ;
VAL_ 1009 RCM2_a889_internalFault_040 1 "RCM2_ALERT_SET" 0 "RCM2_ALERT_CLEARED" ;
VAL_ 1009 RCM2_a890_internalFault_041 1 "RCM2_ALERT_SET" 0 "RCM2_ALERT_CLEARED" ;
VAL_ 1009 RCM2_a891_internalFault_042 1 "RCM2_ALERT_SET" 0 "RCM2_ALERT_CLEARED" ;
VAL_ 1009 RCM2_a892_internalFault_043 1 "RCM2_ALERT_SET" 0 "RCM2_ALERT_CLEARED" ;
VAL_ 1009 RCM2_a893_internalFault_044 1 "RCM2_ALERT_SET" 0 "RCM2_ALERT_CLEARED" ;
VAL_ 1009 RCM2_a894_internalFault_045 1 "RCM2_ALERT_SET" 0 "RCM2_ALERT_CLEARED" ;
VAL_ 1009 RCM2_a895_internalFault_046 1 "RCM2_ALERT_SET" 0 "RCM2_ALERT_CLEARED" ;
VAL_ 1009 RCM2_a896_internalFault_047 1 "RCM2_ALERT_SET" 0 "RCM2_ALERT_CLEARED" ;
VAL_ 1009 RCM2_a897_internalFault_048 1 "RCM2_ALERT_SET" 0 "RCM2_ALERT_CLEARED" ;
VAL_ 1009 RCM2_a898_internalFault_049 1 "RCM2_ALERT_SET" 0 "RCM2_ALERT_CLEARED" ;
VAL_ 1009 RCM2_a899_internalFault_050 1 "RCM2_ALERT_SET" 0 "RCM2_ALERT_CLEARED" ;
VAL_ 1009 RCM2_a900_internalFault_051 1 "RCM2_ALERT_SET" 0 "RCM2_ALERT_CLEARED" ;
VAL_ 1009 RCM2_a901_internalFault_052 1 "RCM2_ALERT_SET" 0 "RCM2_ALERT_CLEARED" ;
VAL_ 1009 RCM2_a902_internalFault_053 1 "RCM2_ALERT_SET" 0 "RCM2_ALERT_CLEARED" ;
VAL_ 1009 RCM2_a903_internalFault_054 1 "RCM2_ALERT_SET" 0 "RCM2_ALERT_CLEARED" ;
VAL_ 1009 RCM2_a904_internalFault_055 1 "RCM2_ALERT_SET" 0 "RCM2_ALERT_CLEARED" ;
VAL_ 1009 RCM2_a905_internalFault_056 1 "RCM2_ALERT_SET" 0 "RCM2_ALERT_CLEARED" ;
VAL_ 1009 RCM2_a906_internalFault_057 1 "RCM2_ALERT_SET" 0 "RCM2_ALERT_CLEARED" ;
VAL_ 1009 RCM2_a907_internalFault_058 1 "RCM2_ALERT_SET" 0 "RCM2_ALERT_CLEARED" ;
VAL_ 1009 RCM2_a908_internalFault_059 1 "RCM2_ALERT_SET" 0 "RCM2_ALERT_CLEARED" ;
VAL_ 1009 RCM2_a909_internalFault_060 1 "RCM2_ALERT_SET" 0 "RCM2_ALERT_CLEARED" ;
VAL_ 1009 RCM2_a910_internalFault_061 1 "RCM2_ALERT_SET" 0 "RCM2_ALERT_CLEARED" ;
VAL_ 1009 RCM2_a911_internalFault_062 1 "RCM2_ALERT_SET" 0 "RCM2_ALERT_CLEARED" ;
VAL_ 1009 RCM2_a912_internalFault_063 1 "RCM2_ALERT_SET" 0 "RCM2_ALERT_CLEARED" ;
VAL_ 1009 RCM2_a913_internalFault_064 1 "RCM2_ALERT_SET" 0 "RCM2_ALERT_CLEARED" ;
VAL_ 1009 RCM2_a914_internalFault_065 1 "RCM2_ALERT_SET" 0 "RCM2_ALERT_CLEARED" ;
VAL_ 1009 RCM2_a915_internalFault_066 1 "RCM2_ALERT_SET" 0 "RCM2_ALERT_CLEARED" ;
VAL_ 1009 RCM2_a916_internalFault_067 1 "RCM2_ALERT_SET" 0 "RCM2_ALERT_CLEARED" ;
VAL_ 1009 RCM2_a917_internalFault_068 1 "RCM2_ALERT_SET" 0 "RCM2_ALERT_CLEARED" ;
VAL_ 1009 RCM2_a918_internalFault_069 1 "RCM2_ALERT_SET" 0 "RCM2_ALERT_CLEARED" ;
VAL_ 1009 RCM2_a919_internalFault_070 1 "RCM2_ALERT_SET" 0 "RCM2_ALERT_CLEARED" ;
VAL_ 1009 RCM2_a920_internalFault_071 1 "RCM2_ALERT_SET" 0 "RCM2_ALERT_CLEARED" ;
VAL_ 1009 RCM2_a921_internalFault_072 1 "RCM2_ALERT_SET" 0 "RCM2_ALERT_CLEARED" ;
VAL_ 1009 RCM2_a922_internalFault_073 1 "RCM2_ALERT_SET" 0 "RCM2_ALERT_CLEARED" ;
VAL_ 1009 RCM2_a923_internalFault_074 1 "RCM2_ALERT_SET" 0 "RCM2_ALERT_CLEARED" ;
VAL_ 1009 RCM2_a924_internalFault_075 1 "RCM2_ALERT_SET" 0 "RCM2_ALERT_CLEARED" ;
VAL_ 1009 RCM2_a925_internalFault_076 1 "RCM2_ALERT_SET" 0 "RCM2_ALERT_CLEARED" ;
VAL_ 1009 RCM2_a926_internalFault_077 1 "RCM2_ALERT_SET" 0 "RCM2_ALERT_CLEARED" ;
VAL_ 1009 RCM2_a927_internalFault_078 1 "RCM2_ALERT_SET" 0 "RCM2_ALERT_CLEARED" ;
VAL_ 1009 RCM2_a928_internalFault_079 1 "RCM2_ALERT_SET" 0 "RCM2_ALERT_CLEARED" ;
VAL_ 1009 RCM2_a929_internalFault_080 1 "RCM2_ALERT_SET" 0 "RCM2_ALERT_CLEARED" ;
VAL_ 1009 RCM2_a930_internalFault_081 1 "RCM2_ALERT_SET" 0 "RCM2_ALERT_CLEARED" ;
VAL_ 1009 RCM2_a931_internalFault_082 1 "RCM2_ALERT_SET" 0 "RCM2_ALERT_CLEARED" ;
VAL_ 1009 RCM2_a932_internalFault_083 1 "RCM2_ALERT_SET" 0 "RCM2_ALERT_CLEARED" ;
VAL_ 1009 RCM2_a933_internalFault_084 1 "RCM2_ALERT_SET" 0 "RCM2_ALERT_CLEARED" ;
VAL_ 1009 RCM2_a934_internalFault_085 1 "RCM2_ALERT_SET" 0 "RCM2_ALERT_CLEARED" ;
VAL_ 1009 RCM2_a935_internalFault_086 1 "RCM2_ALERT_SET" 0 "RCM2_ALERT_CLEARED" ;
VAL_ 1009 RCM2_a936_internalFault_087 1 "RCM2_ALERT_SET" 0 "RCM2_ALERT_CLEARED" ;
VAL_ 1009 RCM2_a937_internalFault_088 1 "RCM2_ALERT_SET" 0 "RCM2_ALERT_CLEARED" ;
VAL_ 1009 RCM2_a938_internalFault_089 1 "RCM2_ALERT_SET" 0 "RCM2_ALERT_CLEARED" ;
VAL_ 1009 RCM2_a939_internalFault_090 1 "RCM2_ALERT_SET" 0 "RCM2_ALERT_CLEARED" ;
VAL_ 1009 RCM2_a940_internalFault_091 1 "RCM2_ALERT_SET" 0 "RCM2_ALERT_CLEARED" ;
VAL_ 1009 RCM2_a941_internalFault_092 1 "RCM2_ALERT_SET" 0 "RCM2_ALERT_CLEARED" ;
VAL_ 1009 RCM2_a942_internalFault_093 1 "RCM2_ALERT_SET" 0 "RCM2_ALERT_CLEARED" ;
VAL_ 1009 RCM2_a943_internalFault_094 1 "RCM2_ALERT_SET" 0 "RCM2_ALERT_CLEARED" ;
VAL_ 1009 RCM2_a944_internalFault_095 1 "RCM2_ALERT_SET" 0 "RCM2_ALERT_CLEARED" ;
VAL_ 1009 RCM2_a945_internalFault_096 1 "RCM2_ALERT_SET" 0 "RCM2_ALERT_CLEARED" ;
VAL_ 1009 RCM2_a946_internalFault_097 1 "RCM2_ALERT_SET" 0 "RCM2_ALERT_CLEARED" ;
VAL_ 1009 RCM2_a947_internalFault_098 1 "RCM2_ALERT_SET" 0 "RCM2_ALERT_CLEARED" ;
VAL_ 1009 RCM2_a948_internalFault_099 1 "RCM2_ALERT_SET" 0 "RCM2_ALERT_CLEARED" ;
VAL_ 1009 RCM2_a949_internalFault_100 1 "RCM2_ALERT_SET" 0 "RCM2_ALERT_CLEARED" ;
VAL_ 1009 RCM2_a950_internalFault_101 1 "RCM2_ALERT_SET" 0 "RCM2_ALERT_CLEARED" ;
VAL_ 1009 RCM2_a951_internalFault_102 1 "RCM2_ALERT_SET" 0 "RCM2_ALERT_CLEARED" ;
VAL_ 1009 RCM2_a952_internalFault_103 1 "RCM2_ALERT_SET" 0 "RCM2_ALERT_CLEARED" ;
VAL_ 1009 RCM2_a953_internalFault_104 1 "RCM2_ALERT_SET" 0 "RCM2_ALERT_CLEARED" ;
VAL_ 1009 RCM2_a954_internalFault_105 1 "RCM2_ALERT_SET" 0 "RCM2_ALERT_CLEARED" ;
VAL_ 1009 RCM2_a955_internalFault_106 1 "RCM2_ALERT_SET" 0 "RCM2_ALERT_CLEARED" ;
VAL_ 1009 RCM2_a956_internalFault_107 1 "RCM2_ALERT_SET" 0 "RCM2_ALERT_CLEARED" ;
VAL_ 1009 RCM2_a957_internalFault_108 1 "RCM2_ALERT_SET" 0 "RCM2_ALERT_CLEARED" ;
VAL_ 1009 RCM2_a958_internalFault_109 1 "RCM2_ALERT_SET" 0 "RCM2_ALERT_CLEARED" ;
VAL_ 1009 RCM2_a959_internalFault_110 1 "RCM2_ALERT_SET" 0 "RCM2_ALERT_CLEARED" ;
VAL_ 1009 RCM2_a960_internalFault_111 1 "RCM2_ALERT_SET" 0 "RCM2_ALERT_CLEARED" ;
VAL_ 1009 RCM2_a961_internalFault_112 1 "RCM2_ALERT_SET" 0 "RCM2_ALERT_CLEARED" ;
VAL_ 1009 RCM2_a962_internalFault_113 1 "RCM2_ALERT_SET" 0 "RCM2_ALERT_CLEARED" ;
VAL_ 1009 RCM2_a963_internalFault_114 1 "RCM2_ALERT_SET" 0 "RCM2_ALERT_CLEARED" ;
VAL_ 1009 RCM2_a964_internalFault_115 1 "RCM2_ALERT_SET" 0 "RCM2_ALERT_CLEARED" ;
VAL_ 1009 RCM2_a965_internalFault_116 1 "RCM2_ALERT_SET" 0 "RCM2_ALERT_CLEARED" ;
VAL_ 1009 RCM2_a966_internalFault_117 1 "RCM2_ALERT_SET" 0 "RCM2_ALERT_CLEARED" ;
VAL_ 1009 RCM2_a967_internalFault_118 1 "RCM2_ALERT_SET" 0 "RCM2_ALERT_CLEARED" ;
VAL_ 1009 RCM2_a968_internalFault_119 1 "RCM2_ALERT_SET" 0 "RCM2_ALERT_CLEARED" ;
VAL_ 1009 RCM2_a969_internalFault_120 1 "RCM2_ALERT_SET" 0 "RCM2_ALERT_CLEARED" ;
VAL_ 1009 RCM2_a970_internalFault_121 1 "RCM2_ALERT_SET" 0 "RCM2_ALERT_CLEARED" ;
VAL_ 1009 RCM2_a971_internalFault_122 1 "RCM2_ALERT_SET" 0 "RCM2_ALERT_CLEARED" ;
VAL_ 1009 RCM2_a972_internalFault_123 1 "RCM2_ALERT_SET" 0 "RCM2_ALERT_CLEARED" ;
VAL_ 1009 RCM2_a973_internalFault_124 1 "RCM2_ALERT_SET" 0 "RCM2_ALERT_CLEARED" ;
VAL_ 1009 RCM2_a974_internalFault_125 1 "RCM2_ALERT_SET" 0 "RCM2_ALERT_CLEARED" ;
VAL_ 1009 RCM2_a975_internalFault_126 1 "RCM2_ALERT_SET" 0 "RCM2_ALERT_CLEARED" ;
VAL_ 1009 RCM2_a976_internalFault_127 1 "RCM2_ALERT_SET" 0 "RCM2_ALERT_CLEARED" ;
VAL_ 1009 RCM2_a977_internalFault_128 1 "RCM2_ALERT_SET" 0 "RCM2_ALERT_CLEARED" ;
VAL_ 1009 RCM2_a978_internalFault_129 1 "RCM2_ALERT_SET" 0 "RCM2_ALERT_CLEARED" ;
VAL_ 1009 RCM2_a979_internalFault_130 1 "RCM2_ALERT_SET" 0 "RCM2_ALERT_CLEARED" ;
VAL_ 1009 RCM2_a980_internalFault_131 1 "RCM2_ALERT_SET" 0 "RCM2_ALERT_CLEARED" ;
VAL_ 1009 RCM2_a981_internalFault_132 1 "RCM2_ALERT_SET" 0 "RCM2_ALERT_CLEARED" ;
VAL_ 1009 RCM2_a982_internalFault_133 1 "RCM2_ALERT_SET" 0 "RCM2_ALERT_CLEARED" ;
VAL_ 1009 RCM2_a983_internalFault_134 1 "RCM2_ALERT_SET" 0 "RCM2_ALERT_CLEARED" ;
VAL_ 1009 RCM2_a984_internalFault_135 1 "RCM2_ALERT_SET" 0 "RCM2_ALERT_CLEARED" ;
VAL_ 1009 RCM2_a985_internalFault_136 1 "RCM2_ALERT_SET" 0 "RCM2_ALERT_CLEARED" ;
VAL_ 1009 RCM2_a986_internalFault_137 1 "RCM2_ALERT_SET" 0 "RCM2_ALERT_CLEARED" ;
VAL_ 1009 RCM2_a987_internalFault_138 1 "RCM2_ALERT_SET" 0 "RCM2_ALERT_CLEARED" ;
VAL_ 1009 RCM2_a988_internalFault_139 1 "RCM2_ALERT_SET" 0 "RCM2_ALERT_CLEARED" ;
VAL_ 1009 RCM2_a989_internalFault_140 1 "RCM2_ALERT_SET" 0 "RCM2_ALERT_CLEARED" ;
VAL_ 1009 RCM2_a990_internalFault_141 1 "RCM2_ALERT_SET" 0 "RCM2_ALERT_CLEARED" ;
VAL_ 1009 RCM2_a991_internalFault_142 1 "RCM2_ALERT_SET" 0 "RCM2_ALERT_CLEARED" ;
VAL_ 1009 RCM2_a992_internalFault_143 1 "RCM2_ALERT_SET" 0 "RCM2_ALERT_CLEARED" ;
VAL_ 1009 RCM2_a993_internalFault_144 1 "RCM2_ALERT_SET" 0 "RCM2_ALERT_CLEARED" ;
VAL_ 1009 RCM2_a994_internalFault_145 1 "RCM2_ALERT_SET" 0 "RCM2_ALERT_CLEARED" ;
VAL_ 1297 RCM_alertID 16495 "RCM_d111_noDeployPedProCal" 16494 "RCM_d110_noDeployCrashCal" 16493 "RCM_d109_abuseImmunity" 16492 "RCM_d108_pedProNearDeploy" 16491 "RCM_d107_pedProCrashDetected" 16490 "RCM_d106_warningIndicator" 16489 "RCM_d105_airbagsNotArmed" 16488 "RCM_d104_nearDeploy" 16487 "RCM_d103_crashDetected" 16486 "RCM_d102_comVCSEATDrest" 16485 "RCM_d101_comVCSEATPrest" 16484 "RCM_d100_pedProPTSR" 16483 "RCM_d099_pedProPTSL" 16482 "RCM_d098_comDIState2" 16481 "RCM_d097_comDIState" 16480 "RCM_d096_comDasStatus" 16479 "RCM_d095_comDasIDF" 16478 "RCM_d094_comGTWESP1" 16477 "RCM_d093_scmUnavailable" 16476 "RCM_d092_driverOrientation" 16475 "RCM_d091_comGTWCarState" 16474 "RCM_d090_dabStage1" 16473 "RCM_d089_dabStage2" 16472 "RCM_d088_kneeABDriver" 16471 "RCM_d087_hvDisconnect" 16470 "RCM_d086_pabStage1" 16469 "RCM_d085_pabStage2" 16468 "RCM_d084_siAB1stRowLeft" 16467 "RCM_d083_curAB1stRowLeft" 16466 "RCM_d082_siAB1stRowRight" 16465 "RCM_d081_curAB1stRowRight" 16464 "RCM_d080_buckleLeftSide" 16463 "RCM_d079_buckleRightSide" 16462 "RCM_d078_hardwareCodingPin1" 16461 "RCM_d077_hardwareCodingPin2" 16460 "RCM_d076_hardwarCodingPin3" 16459 "RCM_d075_siAB2ndRowLeft" 16458 "RCM_d074_siAB2ndRowRight" 16457 "RCM_d073_preten2ndRowLeft" 16456 "RCM_d072_curAB3rdRowLeft" 16455 "RCM_d071_preten2ndRowRight" 16454 "RCM_d070_curAB2ndRowLeft" 16453 "RCM_d069_curAB2ndRowRight" 16452 "RCM_d068_curAB3rdRowRight" 16451 "RCM_d067_loadLimiterLeftSide" 16450 "RCM_d066_loadLimiterRightSide" 16449 "RCM_d065_ufsLeftSide" 16448 "RCM_d064_pasBPillarLeft" 16447 "RCM_d063_pasCPillarLeft" 16446 "RCM_d062_ufsRightSide" 16445 "RCM_d061_pasBPillarRight" 16444 "RCM_d060_pasCPillarRight" 16443 "RCM_d059_pasDPillarRight" 16442 "RCM_d058_pasDPillarLeftXAxis" 16441 "RCM_d057_pasDPillarLeftYAxis" 16440 "RCM_d056_stpsDriver" 16439 "RCM_d055_passResOccupancySw" 16438 "RCM_d054_padLampHardWire" 16437 "RCM_d053_sbsw2ndRowRight" 16436 "RCM_d052_hoodActuatorRight" 16435 "RCM_d051_hoodActuatorLeft" 16434 "RCM_d050_eepromDataLocked" 16433 "RCM_d049_pressureFrontLftDoor" 16432 "RCM_d048_pressureFrontRtDoor" 16431 "RCM_d047_kneeABFrontPassenger" 16430 "RCM_d046_passengerActiveVent" 16429 "RCM_d045_crashOutSignal" 16428 "RCM_d044_pedProCrashDetected" 16427 "RCM_d043_passABLampOnHardWire" 16426 "RCM_d042_pretenShldrFrontLeft" 16425 "RCM_d041_pretenShldFrontRight" 16424 "RCM_d040_pretenLapFrontLeft" 16423 "RCM_d039_pretenLapFrontRight" 16422 "RCM_d038_seatBackSw2ndRowLeft" 16421 "RCM_d037_comMissingVehConfg" 16420 "RCM_d036_comBusOff" 16419 "RCM_d035_comGTWOdo" 16418 "RCM_d034_comESPB" 16417 "RCM_d033_comDITorque1" 16416 "RCM_d032_comDITorque2" 16415 "RCM_d031_comESP145" 16414 "RCM_d030_comStwAngle" 16413 "RCM_d029_comChassisBusOff" 16412 "RCM_d028_comGTWACS" 16411 "RCM_d027_ocsFailure" 16410 "RCM_d026_airbagWarnMismatch" 16409 "RCM_d025_comTPMSStatus" 16408 "RCM_d024_comBCS2CStatus" 16407 "RCM_d023_comBCS2LStatus" 16406 "RCM_d022_comBCS2RStatus" 16405 "RCM_d021_comEPBStatus" 16404 "RCM_d020_comESP135" 16403 "RCM_d019_comESPC" 16402 "RCM_d018_vinEmptyError" 16401 "RCM_d017_comGTWCarConfig" 16400 "RCM_d016_comCANInitFailure" 16399 "RCM_d015_vdsSensorMonitorTemp" 16398 "RCM_d014_vdsChannelSigMonPerm" 16397 "RCM_d013_vdsFieldCalibNotDone" 16396 "RCM_d012_vdsChannelSigMonTmp" 16395 "RCM_d011_vdsFieldCalibFailed" 16394 "RCM_d010_crashCalPNMissing" 16393 "RCM_d009_cfgFault" 16392 "RCM_d008_crcErrorExternal" 16391 "RCM_d007_eolProgMismatch" 16390 "RCM_d006_crashAlgoDisabled" 16389 "RCM_d005_internalHard" 16388 "RCM_d004_idleMode" 16387 "RCM_d003_swVersionMismatch" 16386 "RCM_d002_vinMismatch" 16385 "RCM_d001_vBatRange" 16384 "RCM_d000_comFault1" ;
VAL_ 17 RCM_rearCrash 2 "RCM_CRASH_EVENT_UNUSED" 1 "RCM_CRASH_EVENT_ACTIVE" 0 "RCM_CRASH_EVENT_INACTIVE" ;
VAL_ 17 RCM_rightSideCrash 2 "RCM_CRASH_EVENT_UNUSED" 1 "RCM_CRASH_EVENT_ACTIVE" 0 "RCM_CRASH_EVENT_INACTIVE" ;
VAL_ 17 RCM_leftSideCrash 2 "RCM_CRASH_EVENT_UNUSED" 1 "RCM_CRASH_EVENT_ACTIVE" 0 "RCM_CRASH_EVENT_INACTIVE" ;
VAL_ 17 RCM_frontCrash 2 "RCM_CRASH_EVENT_UNUSED" 1 "RCM_CRASH_EVENT_ACTIVE" 0 "RCM_CRASH_EVENT_INACTIVE" ;
VAL_ 17 RCM_chargerCrash 2 "RCM_CRASH_EVENT_UNUSED" 1 "RCM_CRASH_EVENT_ACTIVE" 0 "RCM_CRASH_EVENT_INACTIVE" ;
VAL_ 17 RCM_pedProEvent 2 "RCM_CRASH_EVENT_UNUSED" 1 "RCM_CRASH_EVENT_ACTIVE" 0 "RCM_CRASH_EVENT_INACTIVE" ;
VAL_ 17 RCM_rollOverCrash 2 "RCM_CRASH_EVENT_UNUSED" 1 "RCM_CRASH_EVENT_ACTIVE" 0 "RCM_CRASH_EVENT_INACTIVE" ;
VAL_ 17 RCM_crashSeverity 3 "RCM_CRASHSEVERITY_PEDPRO_EVENT_ONLY" 2 "RCM_CRASHSEVERITY_SECOND_STAGE" 1 "RCM_CRASHSEVERITY_FIRST_STAGE" 0 "RCM_CRASHSEVERITY_PRETENSIONER" ;
VAL_ 881 RCM_d000_comFault1 3 "UNABLE_TO_TEST_DTC" 2 "FAILED_DTC" 1 "PASSED_DTC" 0 "NOT_TESTED_DTC" ;
VAL_ 881 RCM_d001_vBatRange 3 "UNABLE_TO_TEST_DTC" 2 "FAILED_DTC" 1 "PASSED_DTC" 0 "NOT_TESTED_DTC" ;
VAL_ 881 RCM_d002_vinMismatch 3 "UNABLE_TO_TEST_DTC" 2 "FAILED_DTC" 1 "PASSED_DTC" 0 "NOT_TESTED_DTC" ;
VAL_ 881 RCM_d003_swVersionMismatch 3 "UNABLE_TO_TEST_DTC" 2 "FAILED_DTC" 1 "PASSED_DTC" 0 "NOT_TESTED_DTC" ;
VAL_ 881 RCM_d004_idleMode 3 "UNABLE_TO_TEST_DTC" 2 "FAILED_DTC" 1 "PASSED_DTC" 0 "NOT_TESTED_DTC" ;
VAL_ 881 RCM_d005_internalHard 3 "UNABLE_TO_TEST_DTC" 2 "FAILED_DTC" 1 "PASSED_DTC" 0 "NOT_TESTED_DTC" ;
VAL_ 881 RCM_d006_crashAlgoDisabled 3 "UNABLE_TO_TEST_DTC" 2 "FAILED_DTC" 1 "PASSED_DTC" 0 "NOT_TESTED_DTC" ;
VAL_ 881 RCM_d007_eolProgMismatch 3 "UNABLE_TO_TEST_DTC" 2 "FAILED_DTC" 1 "PASSED_DTC" 0 "NOT_TESTED_DTC" ;
VAL_ 881 RCM_d008_crcErrorExternal 3 "UNABLE_TO_TEST_DTC" 2 "FAILED_DTC" 1 "PASSED_DTC" 0 "NOT_TESTED_DTC" ;
VAL_ 881 RCM_d009_cfgFault 3 "UNABLE_TO_TEST_DTC" 2 "FAILED_DTC" 1 "PASSED_DTC" 0 "NOT_TESTED_DTC" ;
VAL_ 881 RCM_d010_crashCalPNMissing 3 "UNABLE_TO_TEST_DTC" 2 "FAILED_DTC" 1 "PASSED_DTC" 0 "NOT_TESTED_DTC" ;
VAL_ 881 RCM_d011_vdsFieldCalibFailed 3 "UNABLE_TO_TEST_DTC" 2 "FAILED_DTC" 1 "PASSED_DTC" 0 "NOT_TESTED_DTC" ;
VAL_ 881 RCM_d012_vdsChannelSigMonTmp 3 "UNABLE_TO_TEST_DTC" 2 "FAILED_DTC" 1 "PASSED_DTC" 0 "NOT_TESTED_DTC" ;
VAL_ 881 RCM_d013_vdsFieldCalibNotDone 3 "UNABLE_TO_TEST_DTC" 2 "FAILED_DTC" 1 "PASSED_DTC" 0 "NOT_TESTED_DTC" ;
VAL_ 881 RCM_d014_vdsChannelSigMonPerm 3 "UNABLE_TO_TEST_DTC" 2 "FAILED_DTC" 1 "PASSED_DTC" 0 "NOT_TESTED_DTC" ;
VAL_ 881 RCM_d015_vdsSensorMonitorTemp 3 "UNABLE_TO_TEST_DTC" 2 "FAILED_DTC" 1 "PASSED_DTC" 0 "NOT_TESTED_DTC" ;
VAL_ 881 RCM_d016_comCANInitFailure 3 "UNABLE_TO_TEST_DTC" 2 "FAILED_DTC" 1 "PASSED_DTC" 0 "NOT_TESTED_DTC" ;
VAL_ 881 RCM_d017_comGTWCarConfig 3 "UNABLE_TO_TEST_DTC" 2 "FAILED_DTC" 1 "PASSED_DTC" 0 "NOT_TESTED_DTC" ;
VAL_ 881 RCM_d018_vinEmptyError 3 "UNABLE_TO_TEST_DTC" 2 "FAILED_DTC" 1 "PASSED_DTC" 0 "NOT_TESTED_DTC" ;
VAL_ 881 RCM_d019_comESPC 3 "UNABLE_TO_TEST_DTC" 2 "FAILED_DTC" 1 "PASSED_DTC" 0 "NOT_TESTED_DTC" ;
VAL_ 881 RCM_d020_comESP135 3 "UNABLE_TO_TEST_DTC" 2 "FAILED_DTC" 1 "PASSED_DTC" 0 "NOT_TESTED_DTC" ;
VAL_ 881 RCM_d021_comEPBStatus 3 "UNABLE_TO_TEST_DTC" 2 "FAILED_DTC" 1 "PASSED_DTC" 0 "NOT_TESTED_DTC" ;
VAL_ 881 RCM_d022_comBCS2RStatus 3 "UNABLE_TO_TEST_DTC" 2 "FAILED_DTC" 1 "PASSED_DTC" 0 "NOT_TESTED_DTC" ;
VAL_ 881 RCM_d023_comBCS2LStatus 3 "UNABLE_TO_TEST_DTC" 2 "FAILED_DTC" 1 "PASSED_DTC" 0 "NOT_TESTED_DTC" ;
VAL_ 881 RCM_d024_comBCS2CStatus 3 "UNABLE_TO_TEST_DTC" 2 "FAILED_DTC" 1 "PASSED_DTC" 0 "NOT_TESTED_DTC" ;
VAL_ 881 RCM_d025_comTPMSStatus 3 "UNABLE_TO_TEST_DTC" 2 "FAILED_DTC" 1 "PASSED_DTC" 0 "NOT_TESTED_DTC" ;
VAL_ 881 RCM_d026_airbagWarnMismatch 3 "UNABLE_TO_TEST_DTC" 2 "FAILED_DTC" 1 "PASSED_DTC" 0 "NOT_TESTED_DTC" ;
VAL_ 881 RCM_d027_ocsFailure 3 "UNABLE_TO_TEST_DTC" 2 "FAILED_DTC" 1 "PASSED_DTC" 0 "NOT_TESTED_DTC" ;
VAL_ 881 RCM_d028_comGTWACS 3 "UNABLE_TO_TEST_DTC" 2 "FAILED_DTC" 1 "PASSED_DTC" 0 "NOT_TESTED_DTC" ;
VAL_ 881 RCM_d029_comChassisBusOff 3 "UNABLE_TO_TEST_DTC" 2 "FAILED_DTC" 1 "PASSED_DTC" 0 "NOT_TESTED_DTC" ;
VAL_ 881 RCM_d030_comStwAngle 3 "UNABLE_TO_TEST_DTC" 2 "FAILED_DTC" 1 "PASSED_DTC" 0 "NOT_TESTED_DTC" ;
VAL_ 881 RCM_d031_comESP145 3 "UNABLE_TO_TEST_DTC" 2 "FAILED_DTC" 1 "PASSED_DTC" 0 "NOT_TESTED_DTC" ;
VAL_ 881 RCM_d032_comDITorque2 3 "UNABLE_TO_TEST_DTC" 2 "FAILED_DTC" 1 "PASSED_DTC" 0 "NOT_TESTED_DTC" ;
VAL_ 881 RCM_d033_comDITorque1 3 "UNABLE_TO_TEST_DTC" 2 "FAILED_DTC" 1 "PASSED_DTC" 0 "NOT_TESTED_DTC" ;
VAL_ 881 RCM_d034_comESPB 3 "UNABLE_TO_TEST_DTC" 2 "FAILED_DTC" 1 "PASSED_DTC" 0 "NOT_TESTED_DTC" ;
VAL_ 881 RCM_d035_comGTWOdo 3 "UNABLE_TO_TEST_DTC" 2 "FAILED_DTC" 1 "PASSED_DTC" 0 "NOT_TESTED_DTC" ;
VAL_ 881 RCM_d036_comBusOff 3 "UNABLE_TO_TEST_DTC" 2 "FAILED_DTC" 1 "PASSED_DTC" 0 "NOT_TESTED_DTC" ;
VAL_ 881 RCM_d037_comMissingVehConfg 3 "UNABLE_TO_TEST_DTC" 2 "FAILED_DTC" 1 "PASSED_DTC" 0 "NOT_TESTED_DTC" ;
VAL_ 881 RCM_d038_seatBackSw2ndRowLeft 3 "UNABLE_TO_TEST_DTC" 2 "FAILED_DTC" 1 "PASSED_DTC" 0 "NOT_TESTED_DTC" ;
VAL_ 881 RCM_d039_pretenLapFrontRight 3 "UNABLE_TO_TEST_DTC" 2 "FAILED_DTC" 1 "PASSED_DTC" 0 "NOT_TESTED_DTC" ;
VAL_ 881 RCM_d040_pretenLapFrontLeft 3 "UNABLE_TO_TEST_DTC" 2 "FAILED_DTC" 1 "PASSED_DTC" 0 "NOT_TESTED_DTC" ;
VAL_ 881 RCM_d041_pretenShldFrontRight 3 "UNABLE_TO_TEST_DTC" 2 "FAILED_DTC" 1 "PASSED_DTC" 0 "NOT_TESTED_DTC" ;
VAL_ 881 RCM_d042_pretenShldrFrontLeft 3 "UNABLE_TO_TEST_DTC" 2 "FAILED_DTC" 1 "PASSED_DTC" 0 "NOT_TESTED_DTC" ;
VAL_ 881 RCM_d043_passABLampOnHardWire 3 "UNABLE_TO_TEST_DTC" 2 "FAILED_DTC" 1 "PASSED_DTC" 0 "NOT_TESTED_DTC" ;
VAL_ 881 RCM_d044_pedProCrashDetected 3 "UNABLE_TO_TEST_DTC" 2 "FAILED_DTC" 1 "PASSED_DTC" 0 "NOT_TESTED_DTC" ;
VAL_ 881 RCM_d045_crashOutSignal 3 "UNABLE_TO_TEST_DTC" 2 "FAILED_DTC" 1 "PASSED_DTC" 0 "NOT_TESTED_DTC" ;
VAL_ 881 RCM_d046_passengerActiveVent 3 "UNABLE_TO_TEST_DTC" 2 "FAILED_DTC" 1 "PASSED_DTC" 0 "NOT_TESTED_DTC" ;
VAL_ 881 RCM_d047_kneeABFrontPassenger 3 "UNABLE_TO_TEST_DTC" 2 "FAILED_DTC" 1 "PASSED_DTC" 0 "NOT_TESTED_DTC" ;
VAL_ 881 RCM_d048_pressureFrontRtDoor 3 "UNABLE_TO_TEST_DTC" 2 "FAILED_DTC" 1 "PASSED_DTC" 0 "NOT_TESTED_DTC" ;
VAL_ 881 RCM_d049_pressureFrontLftDoor 3 "UNABLE_TO_TEST_DTC" 2 "FAILED_DTC" 1 "PASSED_DTC" 0 "NOT_TESTED_DTC" ;
VAL_ 881 RCM_d050_eepromDataLocked 3 "UNABLE_TO_TEST_DTC" 2 "FAILED_DTC" 1 "PASSED_DTC" 0 "NOT_TESTED_DTC" ;
VAL_ 881 RCM_d051_hoodActuatorLeft 3 "UNABLE_TO_TEST_DTC" 2 "FAILED_DTC" 1 "PASSED_DTC" 0 "NOT_TESTED_DTC" ;
VAL_ 881 RCM_d052_hoodActuatorRight 3 "UNABLE_TO_TEST_DTC" 2 "FAILED_DTC" 1 "PASSED_DTC" 0 "NOT_TESTED_DTC" ;
VAL_ 881 RCM_d053_sbsw2ndRowRight 3 "UNABLE_TO_TEST_DTC" 2 "FAILED_DTC" 1 "PASSED_DTC" 0 "NOT_TESTED_DTC" ;
VAL_ 881 RCM_d054_padLampHardWire 3 "UNABLE_TO_TEST_DTC" 2 "FAILED_DTC" 1 "PASSED_DTC" 0 "NOT_TESTED_DTC" ;
VAL_ 881 RCM_d055_passResOccupancySw 3 "UNABLE_TO_TEST_DTC" 2 "FAILED_DTC" 1 "PASSED_DTC" 0 "NOT_TESTED_DTC" ;
VAL_ 881 RCM_d056_stpsDriver 3 "UNABLE_TO_TEST_DTC" 2 "FAILED_DTC" 1 "PASSED_DTC" 0 "NOT_TESTED_DTC" ;
VAL_ 881 RCM_d057_pasDPillarLeftYAxis 3 "UNABLE_TO_TEST_DTC" 2 "FAILED_DTC" 1 "PASSED_DTC" 0 "NOT_TESTED_DTC" ;
VAL_ 881 RCM_d058_pasDPillarLeftXAxis 3 "UNABLE_TO_TEST_DTC" 2 "FAILED_DTC" 1 "PASSED_DTC" 0 "NOT_TESTED_DTC" ;
VAL_ 881 RCM_d059_pasDPillarRight 3 "UNABLE_TO_TEST_DTC" 2 "FAILED_DTC" 1 "PASSED_DTC" 0 "NOT_TESTED_DTC" ;
VAL_ 881 RCM_d060_pasCPillarRight 3 "UNABLE_TO_TEST_DTC" 2 "FAILED_DTC" 1 "PASSED_DTC" 0 "NOT_TESTED_DTC" ;
VAL_ 881 RCM_d061_pasBPillarRight 3 "UNABLE_TO_TEST_DTC" 2 "FAILED_DTC" 1 "PASSED_DTC" 0 "NOT_TESTED_DTC" ;
VAL_ 881 RCM_d062_ufsRightSide 3 "UNABLE_TO_TEST_DTC" 2 "FAILED_DTC" 1 "PASSED_DTC" 0 "NOT_TESTED_DTC" ;
VAL_ 881 RCM_d063_pasCPillarLeft 3 "UNABLE_TO_TEST_DTC" 2 "FAILED_DTC" 1 "PASSED_DTC" 0 "NOT_TESTED_DTC" ;
VAL_ 881 RCM_d064_pasBPillarLeft 3 "UNABLE_TO_TEST_DTC" 2 "FAILED_DTC" 1 "PASSED_DTC" 0 "NOT_TESTED_DTC" ;
VAL_ 881 RCM_d065_ufsLeftSide 3 "UNABLE_TO_TEST_DTC" 2 "FAILED_DTC" 1 "PASSED_DTC" 0 "NOT_TESTED_DTC" ;
VAL_ 881 RCM_d066_loadLimiterRightSide 3 "UNABLE_TO_TEST_DTC" 2 "FAILED_DTC" 1 "PASSED_DTC" 0 "NOT_TESTED_DTC" ;
VAL_ 881 RCM_d067_loadLimiterLeftSide 3 "UNABLE_TO_TEST_DTC" 2 "FAILED_DTC" 1 "PASSED_DTC" 0 "NOT_TESTED_DTC" ;
VAL_ 881 RCM_d068_curAB3rdRowRight 3 "UNABLE_TO_TEST_DTC" 2 "FAILED_DTC" 1 "PASSED_DTC" 0 "NOT_TESTED_DTC" ;
VAL_ 881 RCM_d069_curAB2ndRowRight 3 "UNABLE_TO_TEST_DTC" 2 "FAILED_DTC" 1 "PASSED_DTC" 0 "NOT_TESTED_DTC" ;
VAL_ 881 RCM_d070_curAB2ndRowLeft 3 "UNABLE_TO_TEST_DTC" 2 "FAILED_DTC" 1 "PASSED_DTC" 0 "NOT_TESTED_DTC" ;
VAL_ 881 RCM_d071_preten2ndRowRight 3 "UNABLE_TO_TEST_DTC" 2 "FAILED_DTC" 1 "PASSED_DTC" 0 "NOT_TESTED_DTC" ;
VAL_ 881 RCM_d072_curAB3rdRowLeft 3 "UNABLE_TO_TEST_DTC" 2 "FAILED_DTC" 1 "PASSED_DTC" 0 "NOT_TESTED_DTC" ;
VAL_ 881 RCM_d073_preten2ndRowLeft 3 "UNABLE_TO_TEST_DTC" 2 "FAILED_DTC" 1 "PASSED_DTC" 0 "NOT_TESTED_DTC" ;
VAL_ 881 RCM_d074_siAB2ndRowRight 3 "UNABLE_TO_TEST_DTC" 2 "FAILED_DTC" 1 "PASSED_DTC" 0 "NOT_TESTED_DTC" ;
VAL_ 881 RCM_d075_siAB2ndRowLeft 3 "UNABLE_TO_TEST_DTC" 2 "FAILED_DTC" 1 "PASSED_DTC" 0 "NOT_TESTED_DTC" ;
VAL_ 881 RCM_d076_hardwarCodingPin3 3 "UNABLE_TO_TEST_DTC" 2 "FAILED_DTC" 1 "PASSED_DTC" 0 "NOT_TESTED_DTC" ;
VAL_ 881 RCM_d077_hardwareCodingPin2 3 "UNABLE_TO_TEST_DTC" 2 "FAILED_DTC" 1 "PASSED_DTC" 0 "NOT_TESTED_DTC" ;
VAL_ 881 RCM_d078_hardwareCodingPin1 3 "UNABLE_TO_TEST_DTC" 2 "FAILED_DTC" 1 "PASSED_DTC" 0 "NOT_TESTED_DTC" ;
VAL_ 881 RCM_d079_buckleRightSide 3 "UNABLE_TO_TEST_DTC" 2 "FAILED_DTC" 1 "PASSED_DTC" 0 "NOT_TESTED_DTC" ;
VAL_ 881 RCM_d080_buckleLeftSide 3 "UNABLE_TO_TEST_DTC" 2 "FAILED_DTC" 1 "PASSED_DTC" 0 "NOT_TESTED_DTC" ;
VAL_ 881 RCM_d081_curAB1stRowRight 3 "UNABLE_TO_TEST_DTC" 2 "FAILED_DTC" 1 "PASSED_DTC" 0 "NOT_TESTED_DTC" ;
VAL_ 881 RCM_d082_siAB1stRowRight 3 "UNABLE_TO_TEST_DTC" 2 "FAILED_DTC" 1 "PASSED_DTC" 0 "NOT_TESTED_DTC" ;
VAL_ 881 RCM_d083_curAB1stRowLeft 3 "UNABLE_TO_TEST_DTC" 2 "FAILED_DTC" 1 "PASSED_DTC" 0 "NOT_TESTED_DTC" ;
VAL_ 881 RCM_d084_siAB1stRowLeft 3 "UNABLE_TO_TEST_DTC" 2 "FAILED_DTC" 1 "PASSED_DTC" 0 "NOT_TESTED_DTC" ;
VAL_ 881 RCM_d085_pabStage2 3 "UNABLE_TO_TEST_DTC" 2 "FAILED_DTC" 1 "PASSED_DTC" 0 "NOT_TESTED_DTC" ;
VAL_ 881 RCM_d086_pabStage1 3 "UNABLE_TO_TEST_DTC" 2 "FAILED_DTC" 1 "PASSED_DTC" 0 "NOT_TESTED_DTC" ;
VAL_ 881 RCM_d087_hvDisconnect 3 "UNABLE_TO_TEST_DTC" 2 "FAILED_DTC" 1 "PASSED_DTC" 0 "NOT_TESTED_DTC" ;
VAL_ 881 RCM_d088_kneeABDriver 3 "UNABLE_TO_TEST_DTC" 2 "FAILED_DTC" 1 "PASSED_DTC" 0 "NOT_TESTED_DTC" ;
VAL_ 881 RCM_d089_dabStage2 3 "UNABLE_TO_TEST_DTC" 2 "FAILED_DTC" 1 "PASSED_DTC" 0 "NOT_TESTED_DTC" ;
VAL_ 881 RCM_d090_dabStage1 3 "UNABLE_TO_TEST_DTC" 2 "FAILED_DTC" 1 "PASSED_DTC" 0 "NOT_TESTED_DTC" ;
VAL_ 881 RCM_d091_comGTWCarState 3 "UNABLE_TO_TEST_DTC" 2 "FAILED_DTC" 1 "PASSED_DTC" 0 "NOT_TESTED_DTC" ;
VAL_ 881 RCM_d092_driverOrientation 3 "UNABLE_TO_TEST_DTC" 2 "FAILED_DTC" 1 "PASSED_DTC" 0 "NOT_TESTED_DTC" ;
VAL_ 881 RCM_d093_scmUnavailable 3 "UNABLE_TO_TEST_DTC" 2 "FAILED_DTC" 1 "PASSED_DTC" 0 "NOT_TESTED_DTC" ;
VAL_ 881 RCM_d094_comGTWESP1 3 "UNABLE_TO_TEST_DTC" 2 "FAILED_DTC" 1 "PASSED_DTC" 0 "NOT_TESTED_DTC" ;
VAL_ 881 RCM_d095_comDasIDF 3 "UNABLE_TO_TEST_DTC" 2 "FAILED_DTC" 1 "PASSED_DTC" 0 "NOT_TESTED_DTC" ;
VAL_ 881 RCM_d096_comDasStatus 3 "UNABLE_TO_TEST_DTC" 2 "FAILED_DTC" 1 "PASSED_DTC" 0 "NOT_TESTED_DTC" ;
VAL_ 881 RCM_d097_comDIState 3 "UNABLE_TO_TEST_DTC" 2 "FAILED_DTC" 1 "PASSED_DTC" 0 "NOT_TESTED_DTC" ;
VAL_ 881 RCM_d098_comDIState2 3 "UNABLE_TO_TEST_DTC" 2 "FAILED_DTC" 1 "PASSED_DTC" 0 "NOT_TESTED_DTC" ;
VAL_ 881 RCM_d099_pedProPTSL 3 "UNABLE_TO_TEST_DTC" 2 "FAILED_DTC" 1 "PASSED_DTC" 0 "NOT_TESTED_DTC" ;
VAL_ 881 RCM_d100_pedProPTSR 3 "UNABLE_TO_TEST_DTC" 2 "FAILED_DTC" 1 "PASSED_DTC" 0 "NOT_TESTED_DTC" ;
VAL_ 881 RCM_d101_comVCSEATPrest 3 "UNABLE_TO_TEST_DTC" 2 "FAILED_DTC" 1 "PASSED_DTC" 0 "NOT_TESTED_DTC" ;
VAL_ 881 RCM_d102_comVCSEATDrest 3 "UNABLE_TO_TEST_DTC" 2 "FAILED_DTC" 1 "PASSED_DTC" 0 "NOT_TESTED_DTC" ;
VAL_ 881 RCM_d103_crashDetected 3 "UNABLE_TO_TEST_DTC" 2 "FAILED_DTC" 1 "PASSED_DTC" 0 "NOT_TESTED_DTC" ;
VAL_ 881 RCM_d104_nearDeploy 3 "UNABLE_TO_TEST_DTC" 2 "FAILED_DTC" 1 "PASSED_DTC" 0 "NOT_TESTED_DTC" ;
VAL_ 881 RCM_d105_airbagsNotArmed 3 "UNABLE_TO_TEST_DTC" 2 "FAILED_DTC" 1 "PASSED_DTC" 0 "NOT_TESTED_DTC" ;
VAL_ 881 RCM_d106_warningIndicator 3 "UNABLE_TO_TEST_DTC" 2 "FAILED_DTC" 1 "PASSED_DTC" 0 "NOT_TESTED_DTC" ;
VAL_ 881 RCM_d107_pedProCrashDetected 3 "UNABLE_TO_TEST_DTC" 2 "FAILED_DTC" 1 "PASSED_DTC" 0 "NOT_TESTED_DTC" ;
VAL_ 881 RCM_d108_pedProNearDeploy 3 "UNABLE_TO_TEST_DTC" 2 "FAILED_DTC" 1 "PASSED_DTC" 0 "NOT_TESTED_DTC" ;
VAL_ 881 RCM_d109_abuseImmunity 3 "UNABLE_TO_TEST_DTC" 2 "FAILED_DTC" 1 "PASSED_DTC" 0 "NOT_TESTED_DTC" ;
VAL_ 881 RCM_d110_noDeployCrashCal 3 "UNABLE_TO_TEST_DTC" 2 "FAILED_DTC" 1 "PASSED_DTC" 0 "NOT_TESTED_DTC" ;
VAL_ 881 RCM_d111_noDeployPedProCal 3 "UNABLE_TO_TEST_DTC" 2 "FAILED_DTC" 1 "PASSED_DTC" 0 "NOT_TESTED_DTC" ;
VAL_ 545 RCM_yawRate 65535 "SNA" 65534 "FAULTED" ;
VAL_ 545 RCM_pitchRate 65535 "SNA" 65534 "FAULTED" ;
VAL_ 545 RCM_rollRate 65535 "SNA" 65534 "FAULTED" ;
VAL_ 545 RCM_yawRateQF 1 "NOT_FAULTED" 0 "FAULTED" ;
VAL_ 545 RCM_pitchRateQF 1 "NOT_FAULTED" 0 "FAULTED" ;
VAL_ 545 RCM_rollRateQF 1 "NOT_FAULTED" 0 "FAULTED" ;
VAL_ 849 RCM_infoBuildType 4 "INFO_MFG_BUILD" 3 "INFO_TRACEABLE_CI_BUILD" 2 "INFO_LOCAL_BUILD" 1 "INFO_PLATFORM_BUILD" 0 "INFO_UNKNOWN_BUILD" ;
VAL_ 273 RCM_ndRearCollision 2 "RCM_NEAR_DEPLOY_EVENT_UNUSED" 1 "RCM_NEAR_DEPLOY_EVENT_ACTIVE" 0 "RCM_NEAR_DEPLOY_EVENT_INACTIVE" ;
VAL_ 273 RCM_ndRightSideCollision 2 "RCM_NEAR_DEPLOY_EVENT_UNUSED" 1 "RCM_NEAR_DEPLOY_EVENT_ACTIVE" 0 "RCM_NEAR_DEPLOY_EVENT_INACTIVE" ;
VAL_ 273 RCM_ndLeftSideCollision 2 "RCM_NEAR_DEPLOY_EVENT_UNUSED" 1 "RCM_NEAR_DEPLOY_EVENT_ACTIVE" 0 "RCM_NEAR_DEPLOY_EVENT_INACTIVE" ;
VAL_ 273 RCM_ndFrontCollision 2 "RCM_NEAR_DEPLOY_EVENT_UNUSED" 1 "RCM_NEAR_DEPLOY_EVENT_ACTIVE" 0 "RCM_NEAR_DEPLOY_EVENT_INACTIVE" ;
VAL_ 273 RCM_crashAlgoWakeup 2 "RCM_CRASH_ALGO_WAKEUP_EVENT_UNUSED" 1 "RCM_CRASH_ALGO_WAKEUP_EVENT_ACTIVE" 0 "RCM_CRASH_ALGO_WAKEUP_EVENT_INACTIVE" ;
VAL_ 273 RCM_ndChargerCollision 2 "RCM_NEAR_DEPLOY_EVENT_UNUSED" 1 "RCM_NEAR_DEPLOY_EVENT_ACTIVE" 0 "RCM_NEAR_DEPLOY_EVENT_INACTIVE" ;
VAL_ 273 RCM_ndPedProEvent 2 "RCM_NEAR_DEPLOY_EVENT_UNUSED" 1 "RCM_NEAR_DEPLOY_EVENT_ACTIVE" 0 "RCM_NEAR_DEPLOY_EVENT_INACTIVE" ;
VAL_ 273 RCM_ndRollOverCollision 2 "RCM_NEAR_DEPLOY_EVENT_UNUSED" 1 "RCM_NEAR_DEPLOY_EVENT_ACTIVE" 0 "RCM_NEAR_DEPLOY_EVENT_INACTIVE" ;
VAL_ 529 RCM_driverOrientationInitStatus 7 "SNA" 4 "MISMATCH_DEFAULT_RHD" 3 "MISMATCH_DEFAULT_LHD" 2 "MATCHED_RHD" 1 "MATCHED_LHD" 0 "INIT_NOT_COMPLETE" ;
VAL_ 529 RCM_armStatus 3 "SNA" 2 "UNUSED" 1 "ARMED" 0 "UNARMED" ;
VAL_ 529 RCM_warningIndicatorState 3 "SNA" 2 "UNUSED" 1 "ON" 0 "OFF" ;
VAL_ 529 RCM_tellTalePassengerState 3 "SNA" 2 "FLASHING" 1 "ON" 0 "OFF" ;
VAL_ 529 RCM_bucklePassengerStatus 3 "SNA" 2 "FAULTED" 1 "BUCKLE_LATCHED" 0 "BUCKLE_UNLATCHED" ;
VAL_ 529 RCM_tellTaleDriverState 3 "SNA" 2 "FLASHING" 1 "ON" 0 "OFF" ;
VAL_ 529 RCM_buckleDriverStatus 3 "SNA" 2 "FAULTED" 1 "BUCKLE_LATCHED" 0 "BUCKLE_UNLATCHED" ;
VAL_ 529 RCM_seatTrackPositionPass 3 "SNA" 2 "FAULTED" 1 "FAR" 0 "NEAR" ;
VAL_ 529 RCM_seatTrackPositionDrvr 3 "SNA" 2 "FAULTED" 1 "FAR" 0 "NEAR" ;
VAL_ 529 RCM_passAirbagRequest 3 "SNA" 2 "UNUSED" 1 "ON" 0 "OFF" ;
VAL_ 529 RCM_chimeState1stRow 3 "SNA" 2 "UNUSED" 1 "ON" 0 "OFF" ;
VAL_ 529 RCM_vinLearnFlag 3 "SNA" 2 "UNUSED" 1 "VIN_STORED" 0 "NO_VIN_STORED" ;
VAL_ 529 RCM_hwConfigPin58 3 "SNA" 2 "FAULTED" 1 "FLOATING" 0 "GROUNDED" ;
VAL_ 529 RCM_hwConfigPin57 3 "SNA" 2 "FAULTED" 1 "LHD_FLOATING" 0 "RHD_GROUNDED" ;
VAL_ 529 RCM_hwConfigPin56 3 "SNA" 2 "FAULTED" 1 "EU_MARKET_FLOATING" 0 "NA_MARKET_GND" ;
VAL_ 529 RCM_passOccupantStatus 3 "RCM_FRONT_PASS_SEAT_SNA" 2 "RCM_FRONT_PASS_SEAT_FAULTED" 1 "RCM_FRONT_PASS_SEAT_OCCUPIED" 0 "RCM_FRONT_PASS_SEAT_UNOCCUPIED" ;
VAL_ 529 RCM_airbagCutoffSwStatus 3 "SNA" 2 "UNUSED" 1 "AIRBAG_OFF" 0 "AIRBAG_ON" ;
VAL_ 529 RCM_privateCANStatus 3 "SNA" 2 "PAST_HISTORY" 1 "FAULTED" 0 "NO_FAULT" ;
VAL_ 529 RCM_publicCANStatus 3 "SNA" 2 "PAST_HISTORY" 1 "FAULTED" 0 "NO_FAULT" ;
VAL_ 529 RCM_pedProEDR2State 3 "RCM_EDR_SNA" 2 "RCM_EDR_LOCKED" 1 "RCM_EDR_STORED" 0 "RCM_EDR_EMPTY" ;
VAL_ 529 RCM_pedProEDR1State 3 "RCM_EDR_SNA" 2 "RCM_EDR_LOCKED" 1 "RCM_EDR_STORED" 0 "RCM_EDR_EMPTY" ;
VAL_ 529 RCM_edr2State 3 "RCM_EDR_SNA" 2 "RCM_EDR_LOCKED" 1 "RCM_EDR_STORED" 0 "RCM_EDR_EMPTY" ;
VAL_ 529 RCM_edr1State 3 "RCM_EDR_SNA" 2 "RCM_EDR_LOCKED" 1 "RCM_EDR_STORED" 0 "RCM_EDR_EMPTY" ;
VAL_ 529 RCM_buckle2ndRowStatus 7 "RCM_REAR_UNBUCKLED_OCCUPANTS_SNA" 6 "RCM_REAR_UNBUCKLED_OCCUPANTS_FAULT" 3 "RCM_REAR_UNBUCKLED_OCCUPANTS_3" 2 "RCM_REAR_UNBUCKLED_OCCUPANTS_2" 1 "RCM_REAR_UNBUCKLED_OCCUPANTS_1" 0 "RCM_REAR_UNBUCKLED_OCCUPANTS_0" ;
VAL_ 109 StW_Sw_Stat3 7 "SNA" 6 "NDEF6" 5 "NDEF5" 4 "NDEF4" 3 "PLUS_MINUS" 2 "MINUS" 1 "PLUS" 0 "NPSD" ;
VAL_ 109 MsgTxmtId 3 "NDEF3" 2 "NDEF2" 1 "SCCM" 0 "EWM" ;
VAL_ 109 TSL_RND_Posn_StW 15 "SNA" 8 "D" 6 "INI" 4 "N_DOWN" 2 "N_UP" 1 "R" 0 "IDLE" ;
VAL_ 109 TSL_P_Psd_StW 3 "SNA" 2 "INI" 1 "PSD" 0 "IDLE" ;
VAL_ 815 StW_Temp 255 "SNA" ;
VAL_ 815 StW_TempSens_Flt 3 "SNA" 2 "OPN" 1 "SHRT" 0 "OK" ;
VAL_ 815 ALDW_VibMot_Stat 7 "SNA" 6 "LIN_FLT" 5 "VIB_FLT" 4 "OPN" 3 "BLOCK" 2 "SHRT" 1 "VIB_ON" 0 "VIB_OFF" ;
VAL_ 638 DDM_driverFrontPresentReq 3 "SNA" 2 "FAULT" 1 "PRESSED" 0 "UNPRESSED" ;
VAL_ 638 SC_keyfobButton1 3 "SNA" 2 "FAULT" 1 "PRESSED" 0 "UNPRESSED" ;
VAL_ 638 DDM_driverRearPresentReq 3 "SNA" 2 "FAULT" 1 "PRESSED" 0 "UNPRESSED" ;
VAL_ 638 SC_keyfobButton2 3 "SNA" 2 "FAULT" 1 "PRESSED" 0 "UNPRESSED" ;
VAL_ 638 PDM_passFrontPresentReq 3 "SNA" 2 "FAULT" 1 "PRESSED" 0 "UNPRESSED" ;
VAL_ 638 SC_keyfobButton3 3 "SNA" 2 "FAULT" 1 "PRESSED" 0 "UNPRESSED" ;
VAL_ 638 PDM_passRearPresentReq 3 "SNA" 2 "FAULT" 1 "PRESSED" 0 "UNPRESSED" ;
SIG_GROUP_ 109 SBW_Rq_SCCM 1 : CRC_SBW_RQ_SCCM MC_SBW_RQ_SCCM MsgTxmtId StW_Sw_Stat3 TSL_P_Psd_StW TSL_RND_Posn_StW;
SIG_GROUP_ 815 ALDW_VibMot 1 : ALDW_VibMot_Avl ALDW_VibMot_Stat;
SIG_GROUP_ 815 StW_TempSens_Stat 1 : StW_Temp StW_TempSens_Flt;
